VERSION ""

NS_ :

BS_:

BU_:

BO_ 2566756606 AT1HI1: 40 Vector__XXX
 SG_ Aftertreatment1TotalFuelUsed : 0|32@1+ (0.5,0) [0|2105540607.5] "l" Vector__XXX
 SG_ Aftrtrtmnt1TtlDsldTm : 64|32@1+ (1,0) [0|4211081215] "s" Vector__XXX
 SG_ Aftrtrtmnt1TtlNmrfAtvRgnrtns : 96|32@1+ (1,0) [0|4211081215] "count" Vector__XXX
 SG_ Aftrtrtmnt1TtlRgnrtnTm : 32|32@1+ (1,0) [0|4211081215] "s" Vector__XXX
 SG_ Atttt1DsPttFtAvDstBtwAtvRts : 288|32@1+ (0.125,0) [0|526385151.875] "km" Vector__XXX
 SG_ Atttt1DsPttFtAvTBtwAtvRts : 256|32@1+ (1,0) [0|4211081215] "s" Vector__XXX
 SG_ Atttt1DsPttFtTtNAtvRtItRqsts : 192|32@1+ (1,0) [0|4211081215] "count" Vector__XXX
 SG_ Atttt1DsPttFtTtNAtvRtMRqsts : 224|32@1+ (1,0) [0|4211081215] "count" Vector__XXX
 SG_ Atttt1DsPttFtTtNPssvRts : 160|32@1+ (1,0) [0|4211081215] "count" Vector__XXX
 SG_ Atttt1DsPttFtTtPssvRtT : 128|32@1+ (1,0) [0|4211081215] "s" Vector__XXX

BO_ 2566756862 AT2HI1: 40 Vector__XXX
 SG_ Aftertreatment2TotalFuelUsed : 0|32@1+ (0.5,0) [0|2105540607.5] "l" Vector__XXX
 SG_ Aftrtrtmnt2TtlDsldTm : 64|32@1+ (1,0) [0|4211081215] "s" Vector__XXX
 SG_ Aftrtrtmnt2TtlNmrfAtvRgnrtns : 96|32@1+ (1,0) [0|4211081215] "count" Vector__XXX
 SG_ Aftrtrtmnt2TtlRgnrtnTm : 32|32@1+ (1,0) [0|4211081215] "s" Vector__XXX
 SG_ Atttt2DsPttFtAvDstBtwAtvRts : 288|32@1+ (0.125,0) [0|526385151.875] "km" Vector__XXX
 SG_ Atttt2DsPttFtAvTBtwAtvRts : 256|32@1+ (1,0) [0|4211081215] "s" Vector__XXX
 SG_ Atttt2DsPttFtTtNAtvRtItRqsts : 192|32@1+ (1,0) [0|4211081215] "count" Vector__XXX
 SG_ Atttt2DsPttFtTtNAtvRtMRqsts : 224|32@1+ (1,0) [0|4211081215] "count" Vector__XXX
 SG_ Atttt2DsPttFtTtNPssvRts : 160|32@1+ (1,0) [0|4211081215] "count" Vector__XXX
 SG_ Atttt2DsPttFtTtPssvRtT : 128|32@1+ (1,0) [0|4211081215] "s" Vector__XXX

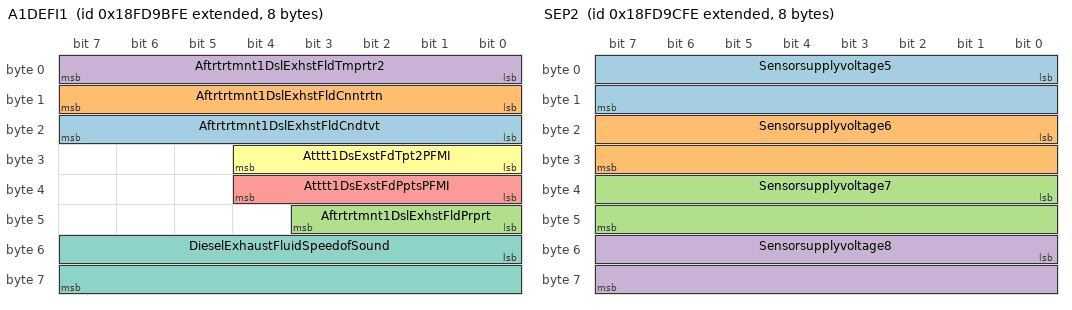
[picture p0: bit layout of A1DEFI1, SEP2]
BO_ 2566757374 A1DEFI1: 8 Vector__XXX
 SG_ Aftrtrtmnt1DslExhstFldCndtvt : 16|8@1+ (5,0) [0|1250] "µSiemens/mm" Vector__XXX
 SG_ Aftrtrtmnt1DslExhstFldCnntrtn : 8|8@1+ (0.25,0) [0|62.5] "%" Vector__XXX
 SG_ Aftrtrtmnt1DslExhstFldPrprt : 40|4@1+ (1,0) [0|15] "" Vector__XXX
 SG_ Aftrtrtmnt1DslExhstFldTmprtr2 : 0|8@1+ (1,-40) [-40|210] "degC" Vector__XXX
 SG_ Atttt1DsExstFdPptsPFMI : 32|5@1+ (1,0) [0|31] "binary" Vector__XXX
 SG_ Atttt1DsExstFdTpt2PFMI : 24|5@1+ (1,0) [0|31] "binary" Vector__XXX
 SG_ DieselExhaustFluidSpeedofSound : 48|16@1+ (0.1,0) [0|6425.5] "m/s" Vector__XXX

BO_ 2566757630 SEP2: 8 Vector__XXX
 SG_ Sensorsupplyvoltage5 : 0|16@1+ (0.05,0) [0|3212.75] "V" Vector__XXX
 SG_ Sensorsupplyvoltage6 : 16|16@1+ (0.05,0) [0|3212.75] "V" Vector__XXX
 SG_ Sensorsupplyvoltage7 : 32|16@1+ (0.05,0) [0|3212.75] "V" Vector__XXX
 SG_ Sensorsupplyvoltage8 : 48|16@1+ (0.05,0) [0|3212.75] "V" Vector__XXX

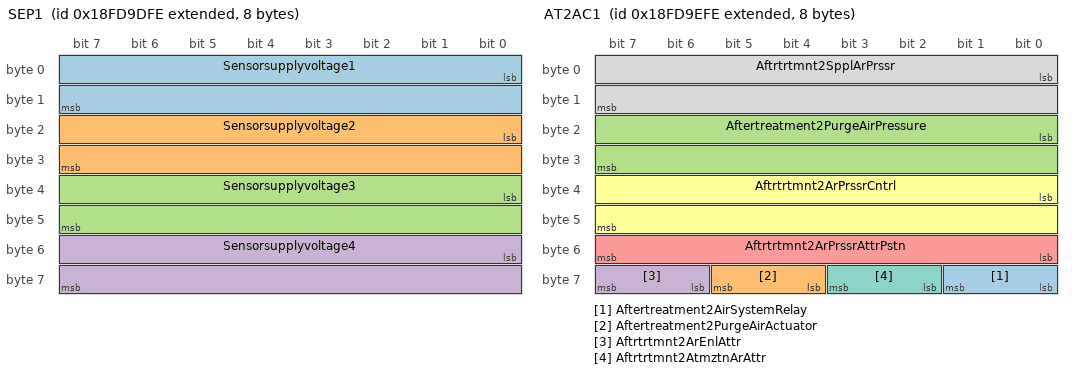
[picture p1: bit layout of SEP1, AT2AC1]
BO_ 2566757886 SEP1: 8 Vector__XXX
 SG_ Sensorsupplyvoltage1 : 0|16@1+ (0.05,0) [0|3212.75] "V" Vector__XXX
 SG_ Sensorsupplyvoltage2 : 16|16@1+ (0.05,0) [0|3212.75] "V" Vector__XXX
 SG_ Sensorsupplyvoltage3 : 32|16@1+ (0.05,0) [0|3212.75] "V" Vector__XXX
 SG_ Sensorsupplyvoltage4 : 48|16@1+ (0.05,0) [0|3212.75] "V" Vector__XXX

BO_ 2566758142 AT2AC1: 8 Vector__XXX
 SG_ Aftertreatment2AirSystemRelay : 56|2@1+ (1,0) [0|3] "" Vector__XXX
 SG_ Aftertreatment2PurgeAirActuator : 60|2@1+ (1,0) [0|3] "" Vector__XXX
 SG_ Aftertreatment2PurgeAirPressure : 16|16@1+ (0.1,0) [0|6425.5] "kPa" Vector__XXX
 SG_ Aftrtrtmnt2ArEnlAttr : 62|2@1+ (1,0) [0|3] "" Vector__XXX
 SG_ Aftrtrtmnt2ArPrssrAttrPstn : 48|8@1+ (0.4,0) [0|100] "%" Vector__XXX
 SG_ Aftrtrtmnt2ArPrssrCntrl : 32|16@1+ (0.0025,0) [0|160.6375] "%" Vector__XXX
 SG_ Aftrtrtmnt2AtmztnArAttr : 58|2@1+ (1,0) [0|3] "" Vector__XXX
 SG_ Aftrtrtmnt2SpplArPrssr : 0|16@1+ (0.1,0) [0|6425.5] "kPa" Vector__XXX

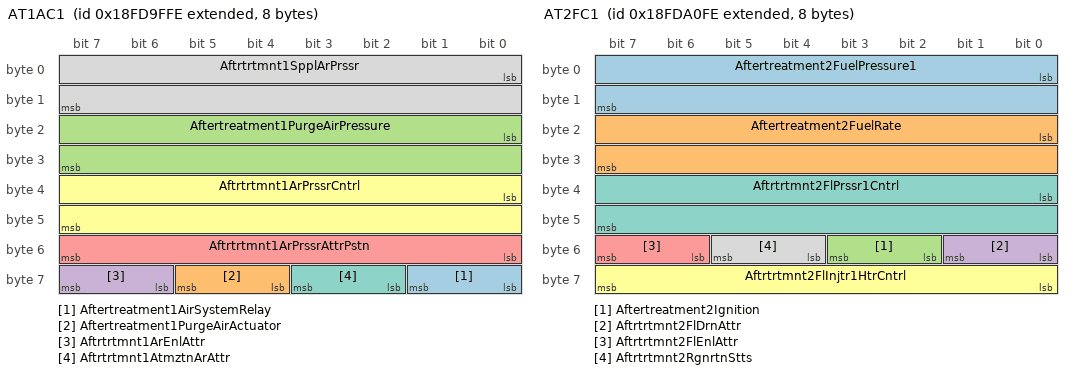
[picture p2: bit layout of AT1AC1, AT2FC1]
BO_ 2566758398 AT1AC1: 8 Vector__XXX
 SG_ Aftertreatment1AirSystemRelay : 56|2@1+ (1,0) [0|3] "" Vector__XXX
 SG_ Aftertreatment1PurgeAirActuator : 60|2@1+ (1,0) [0|3] "" Vector__XXX
 SG_ Aftertreatment1PurgeAirPressure : 16|16@1+ (0.1,0) [0|6425.5] "kPa" Vector__XXX
 SG_ Aftrtrtmnt1ArEnlAttr : 62|2@1+ (1,0) [0|3] "" Vector__XXX
 SG_ Aftrtrtmnt1ArPrssrAttrPstn : 48|8@1+ (0.4,0) [0|100] "%" Vector__XXX
 SG_ Aftrtrtmnt1ArPrssrCntrl : 32|16@1+ (0.0025,0) [0|160.6375] "%" Vector__XXX
 SG_ Aftrtrtmnt1AtmztnArAttr : 58|2@1+ (1,0) [0|3] "" Vector__XXX
 SG_ Aftrtrtmnt1SpplArPrssr : 0|16@1+ (0.1,0) [0|6425.5] "kPa" Vector__XXX

BO_ 2566758654 AT2FC1: 8 Vector__XXX
 SG_ Aftertreatment2FuelPressure1 : 0|16@1+ (0.1,0) [0|6425.5] "kPa" Vector__XXX
 SG_ Aftertreatment2FuelRate : 16|16@1+ (0.05,0) [0|3212.75] "l/h" Vector__XXX
 SG_ Aftertreatment2Ignition : 50|2@1+ (1,0) [0|3] "" Vector__XXX
 SG_ Aftrtrtmnt2FlDrnAttr : 48|2@1+ (1,0) [0|3] "" Vector__XXX
 SG_ Aftrtrtmnt2FlEnlAttr : 54|2@1+ (1,0) [0|3] "" Vector__XXX
 SG_ Aftrtrtmnt2FlInjtr1HtrCntrl : 56|8@1+ (0.4,0) [0|100] "%" Vector__XXX
 SG_ Aftrtrtmnt2FlPrssr1Cntrl : 32|16@1+ (0.0025,0) [0|160.6375] "%" Vector__XXX
 SG_ Aftrtrtmnt2RgnrtnStts : 52|2@1+ (1,0) [0|3] "" Vector__XXX

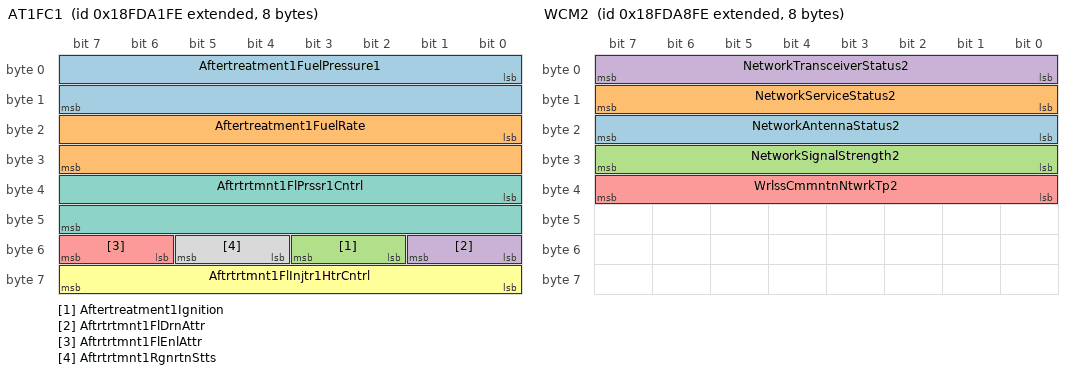
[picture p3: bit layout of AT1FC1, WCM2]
BO_ 2566758910 AT1FC1: 8 Vector__XXX
 SG_ Aftertreatment1FuelPressure1 : 0|16@1+ (0.1,0) [0|6425.5] "kPa" Vector__XXX
 SG_ Aftertreatment1FuelRate : 16|16@1+ (0.05,0) [0|3212.75] "l/h" Vector__XXX
 SG_ Aftertreatment1Ignition : 50|2@1+ (1,0) [0|3] "" Vector__XXX
 SG_ Aftrtrtmnt1FlDrnAttr : 48|2@1+ (1,0) [0|3] "" Vector__XXX
 SG_ Aftrtrtmnt1FlEnlAttr : 54|2@1+ (1,0) [0|3] "" Vector__XXX
 SG_ Aftrtrtmnt1FlInjtr1HtrCntrl : 56|8@1+ (0.4,0) [0|100] "%" Vector__XXX
 SG_ Aftrtrtmnt1FlPrssr1Cntrl : 32|16@1+ (0.0025,0) [0|160.6375] "%" Vector__XXX
 SG_ Aftrtrtmnt1RgnrtnStts : 52|2@1+ (1,0) [0|3] "" Vector__XXX

BO_ 2566759678 PTODE: 8 Vector__XXX
 SG_ AtleastonePTOengaged : 48|2@1+ (1,0) [0|3] "" Vector__XXX
 SG_ EnableSwitchPTOEngineFlywheel : 8|2@1+ (1,0) [0|3] "" Vector__XXX
 SG_ EnggmntCnsntPTOEngnAssrDrv1 : 26|2@1+ (1,0) [0|3] "" Vector__XXX
 SG_ EnggmntCnsntPTOEngnAssrDrv2 : 28|2@1+ (1,0) [0|3] "" Vector__XXX
 SG_ EnggmntCnsntPTOEngnFlwhl : 24|2@1+ (1,0) [0|3] "" Vector__XXX
 SG_ EnggmntSttsPTOEngnAssrDrv1 : 42|2@1+ (1,0) [0|3] "" Vector__XXX
 SG_ EnggmntSttsPTOEngnAssrDrv2 : 44|2@1+ (1,0) [0|3] "" Vector__XXX
 SG_ EnggmntSttsPTOEngnFlwhl : 40|2@1+ (1,0) [0|3] "" Vector__XXX
 SG_ EnlSwthPTOEngnAssrDrv1 : 10|2@1+ (1,0) [0|3] "" Vector__XXX
 SG_ EnlSwthPTOEngnAssrDrv2 : 12|2@1+ (1,0) [0|3] "" Vector__XXX
 SG_ EnlSwthTrnsfrstptshftPTO : 0|2@1+ (1,0) [0|3] "" Vector__XXX
 SG_ EnlSwthTrnsmssntptshftPTO : 2|2@1+ (1,0) [0|3] "" Vector__XXX
 SG_ EnlSwthTrnsmssnnptshftPTO2 : 4|2@1+ (1,0) [0|3] "" Vector__XXX
 SG_ EnlSwthTrnsmssnnptshftPTO1 : 6|2@1+ (1,0) [0|3] "" Vector__XXX
 SG_ EnggmntCnsntTrnsfrstptshftPTO : 16|2@1+ (1,0) [0|3] "" Vector__XXX
 SG_ EnggmntCnsntTrnsmssntptshftPTO : 18|2@1+ (1,0) [0|3] "" Vector__XXX
 SG_ EnggmntCnsntTrnsmssnnptshftPTO2 : 20|2@1+ (1,0) [0|3] "" Vector__XXX
 SG_ EnggmntCnsntTrnsmssnnptshftPTO1 : 22|2@1+ (1,0) [0|3] "" Vector__XXX
 SG_ EnggmntSttsTrnsfrstptshftPTO : 32|2@1+ (1,0) [0|3] "" Vector__XXX
 SG_ EnggmntSttsTrnsmssntptshftPTO : 34|2@1+ (1,0) [0|3] "" Vector__XXX
 SG_ EnggmntSttsTrnsmssnnptshftPTO2 : 36|2@1+ (1,0) [0|3] "" Vector__XXX
 SG_ EnggmntSttsTrnsmssnnptshftPTO1 : 38|2@1+ (1,0) [0|3] "" Vector__XXX
 SG_ PTOMessageCounter : 56|4@1+ (1,0) [0|15] "count" Vector__XXX
 SG_ PTOMessageChecksum : 60|4@1+ (1,0) [0|15] "count" Vector__XXX

BO_ 2566759934 DC2: 8 Vector__XXX
 SG_ EnableStatusofDoor1 : 4|2@1+ (1,0) [0|3] "" Vector__XXX
 SG_ EnableStatusofDoor10 : 58|2@1+ (1,0) [0|3] "" Vector__XXX
 SG_ EnableStatusofDoor2 : 10|2@1+ (1,0) [0|3] "" Vector__XXX
 SG_ EnableStatusofDoor3 : 16|2@1+ (1,0) [0|3] "" Vector__XXX
 SG_ EnableStatusofDoor4 : 22|2@1+ (1,0) [0|3] "" Vector__XXX
 SG_ EnableStatusofDoor5 : 28|2@1+ (1,0) [0|3] "" Vector__XXX
 SG_ EnableStatusofDoor6 : 34|2@1+ (1,0) [0|3] "" Vector__XXX
 SG_ EnableStatusofDoor7 : 40|2@1+ (1,0) [0|3] "" Vector__XXX
 SG_ EnableStatusofDoor8 : 46|2@1+ (1,0) [0|3] "" Vector__XXX
 SG_ EnableStatusofDoor9 : 52|2@1+ (1,0) [0|3] "" Vector__XXX
 SG_ LockStatusofDoor1 : 0|2@1+ (1,0) [0|3] "" Vector__XXX
 SG_ LockStatusofDoor10 : 54|2@1+ (1,0) [0|3] "" Vector__XXX
 SG_ LockStatusofDoor2 : 6|2@1+ (1,0) [0|3] "" Vector__XXX
 SG_ LockStatusofDoor3 : 12|2@1+ (1,0) [0|3] "" Vector__XXX
 SG_ LockStatusofDoor4 : 18|2@1+ (1,0) [0|3] "" Vector__XXX
 SG_ LockStatusofDoor5 : 24|2@1+ (1,0) [0|3] "" Vector__XXX
 SG_ LockStatusofDoor6 : 30|2@1+ (1,0) [0|3] "" Vector__XXX
 SG_ LockStatusofDoor7 : 36|2@1+ (1,0) [0|3] "" Vector__XXX
 SG_ LockStatusofDoor8 : 42|2@1+ (1,0) [0|3] "" Vector__XXX
 SG_ LockStatusofDoor9 : 48|2@1+ (1,0) [0|3] "" Vector__XXX
 SG_ OpenStatusofDoor1 : 2|2@1+ (1,0) [0|3] "" Vector__XXX
 SG_ OpenStatusofDoor10 : 56|2@1+ (1,0) [0|3] "" Vector__XXX
 SG_ OpenStatusofDoor2 : 8|2@1+ (1,0) [0|3] "" Vector__XXX
 SG_ OpenStatusofDoor3 : 14|2@1+ (1,0) [0|3] "" Vector__XXX
 SG_ OpenStatusofDoor4 : 20|2@1+ (1,0) [0|3] "" Vector__XXX
 SG_ OpenStatusofDoor5 : 26|2@1+ (1,0) [0|3] "" Vector__XXX
 SG_ OpenStatusofDoor6 : 32|2@1+ (1,0) [0|3] "" Vector__XXX
 SG_ OpenStatusofDoor7 : 38|2@1+ (1,0) [0|3] "" Vector__XXX
 SG_ OpenStatusofDoor8 : 44|2@1+ (1,0) [0|3] "" Vector__XXX
 SG_ OpenStatusofDoor9 : 50|2@1+ (1,0) [0|3] "" Vector__XXX

BO_ 2566760702 WCM2: 8 Vector__XXX
 SG_ NetworkAntennaStatus2 : 16|8@1+ (1,0) [0|255] "" Vector__XXX
 SG_ NetworkServiceStatus2 : 8|8@1+ (1,0) [0|255] "" Vector__XXX
 SG_ NetworkSignalStrength2 : 24|8@1+ (0.4,0) [0|100] "%" Vector__XXX
 SG_ NetworkTransceiverStatus2 : 0|8@1+ (1,0) [0|255] "" Vector__XXX
 SG_ WrlssCmmntnNtwrkTp2 : 32|8@1+ (1,0) [0|255] "" Vector__XXX

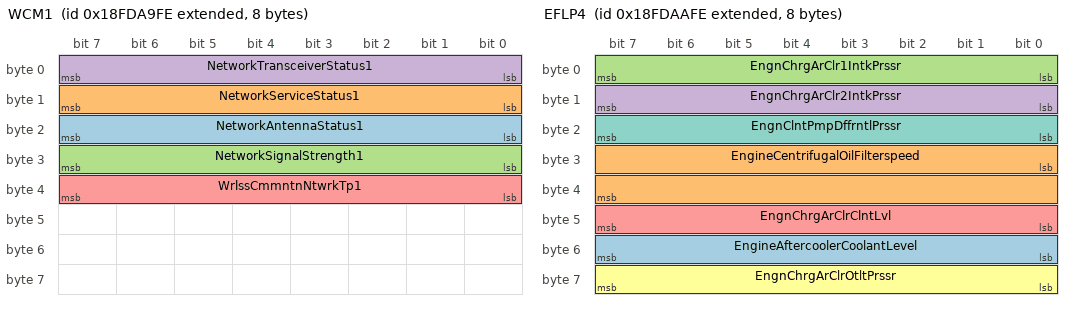
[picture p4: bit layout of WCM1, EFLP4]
BO_ 2566760958 WCM1: 8 Vector__XXX
 SG_ NetworkAntennaStatus1 : 16|8@1+ (1,0) [0|255] "" Vector__XXX
 SG_ NetworkServiceStatus1 : 8|8@1+ (1,0) [0|255] "" Vector__XXX
 SG_ NetworkSignalStrength1 : 24|8@1+ (0.4,0) [0|100] "%" Vector__XXX
 SG_ NetworkTransceiverStatus1 : 0|8@1+ (1,0) [0|255] "" Vector__XXX
 SG_ WrlssCmmntnNtwrkTp1 : 32|8@1+ (1,0) [0|255] "" Vector__XXX

BO_ 2566761214 EFLP4: 8 Vector__XXX
 SG_ EngineAftercoolerCoolantLevel : 48|8@1+ (0.4,0) [0|100] "%" Vector__XXX
 SG_ EngineCentrifugalOilFilterspeed : 24|16@1+ (4,0) [0|257020] "rpm" Vector__XXX
 SG_ EngnChrgArClr1IntkPrssr : 0|8@1+ (2,0) [0|500] "kPa" Vector__XXX
 SG_ EngnChrgArClr2IntkPrssr : 8|8@1+ (2,0) [0|500] "kPa" Vector__XXX
 SG_ EngnChrgArClrClntLvl : 40|8@1+ (0.4,0) [0|100] "%" Vector__XXX
 SG_ EngnChrgArClrOtltPrssr : 56|8@1+ (2,0) [0|500] "kPa" Vector__XXX
 SG_ EngnClntPmpDffrntlPrssr : 16|8@1+ (1.64,-7) [-7|403] "kPa" Vector__XXX

BO_ 2566761726 EFI: 8 Vector__XXX
 SG_ EngineIdleFuelFlowRateThreshold : 8|32@1+ (0.001,0) [0|4211081.215] "l/h" Vector__XXX
 SG_ NmrfFlCnsmptnMntrngTrnsdrs : 0|8@1+ (1,0) [0|250] "count" Vector__XXX

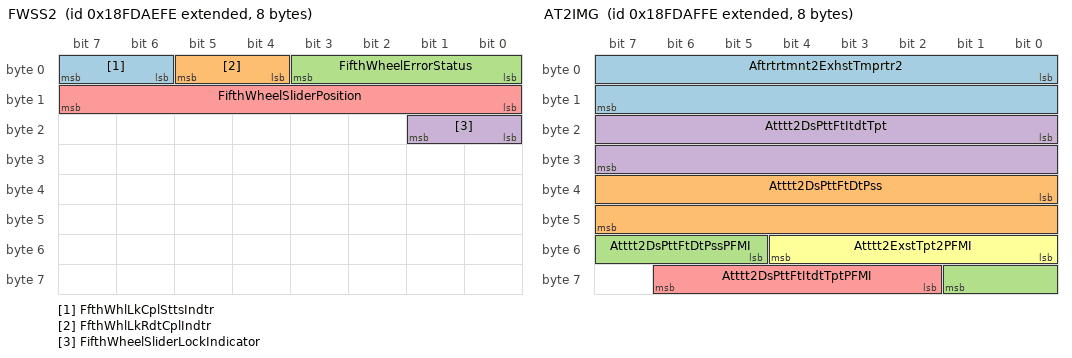
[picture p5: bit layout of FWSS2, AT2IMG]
BO_ 2566762238 FWSS2: 8 Vector__XXX
 SG_ FfthWhlLkCplSttsIndtr : 6|2@1+ (1,0) [0|3] "" Vector__XXX
 SG_ FfthWhlLkRdtCplIndtr : 4|2@1+ (1,0) [0|3] "" Vector__XXX
 SG_ FifthWheelErrorStatus : 0|4@1+ (1,0) [0|15] "" Vector__XXX
 SG_ FifthWheelSliderLockIndicator : 16|2@1+ (1,0) [0|3] "" Vector__XXX
 SG_ FifthWheelSliderPosition : 8|8@1+ (10,0) [0|2500] "mm" Vector__XXX

BO_ 2566762494 AT2IMG: 8 Vector__XXX
 SG_ Aftrtrtmnt2ExhstTmprtr2 : 0|16@1+ (0.03125,-273) [-273|1734.96875] "degC" Vector__XXX
 SG_ Atttt2DsPttFtDtPss : 32|16@1+ (0.1,0) [0|6425.5] "kPa" Vector__XXX
 SG_ Atttt2DsPttFtDtPssPFMI : 53|5@1+ (1,0) [0|31] "binary" Vector__XXX
 SG_ Atttt2DsPttFtItdtTpt : 16|16@1+ (0.03125,-273) [-273|1734.96875] "degC" Vector__XXX
 SG_ Atttt2DsPttFtItdtTptPFMI : 58|5@1+ (1,0) [0|31] "binary" Vector__XXX
 SG_ Atttt2ExstTpt2PFMI : 48|5@1+ (1,0) [0|31] "binary" Vector__XXX

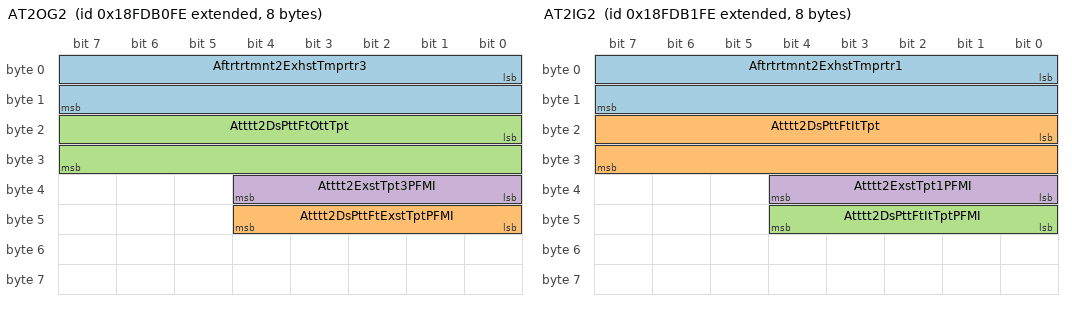
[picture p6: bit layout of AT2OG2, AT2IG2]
BO_ 2566762750 AT2OG2: 8 Vector__XXX
 SG_ Aftrtrtmnt2ExhstTmprtr3 : 0|16@1+ (0.03125,-273) [-273|1734.96875] "degC" Vector__XXX
 SG_ Atttt2DsPttFtExstTptPFMI : 40|5@1+ (1,0) [0|31] "binary" Vector__XXX
 SG_ Atttt2DsPttFtOttTpt : 16|16@1+ (0.03125,-273) [-273|1734.96875] "degC" Vector__XXX
 SG_ Atttt2ExstTpt3PFMI : 32|5@1+ (1,0) [0|31] "binary" Vector__XXX

BO_ 2566763006 AT2IG2: 8 Vector__XXX
 SG_ Aftrtrtmnt2ExhstTmprtr1 : 0|16@1+ (0.03125,-273) [-273|1734.96875] "degC" Vector__XXX
 SG_ Atttt2DsPttFtItTpt : 16|16@1+ (0.03125,-273) [-273|1734.96875] "degC" Vector__XXX
 SG_ Atttt2DsPttFtItTptPFMI : 40|5@1+ (1,0) [0|31] "binary" Vector__XXX
 SG_ Atttt2ExstTpt1PFMI : 32|5@1+ (1,0) [0|31] "binary" Vector__XXX

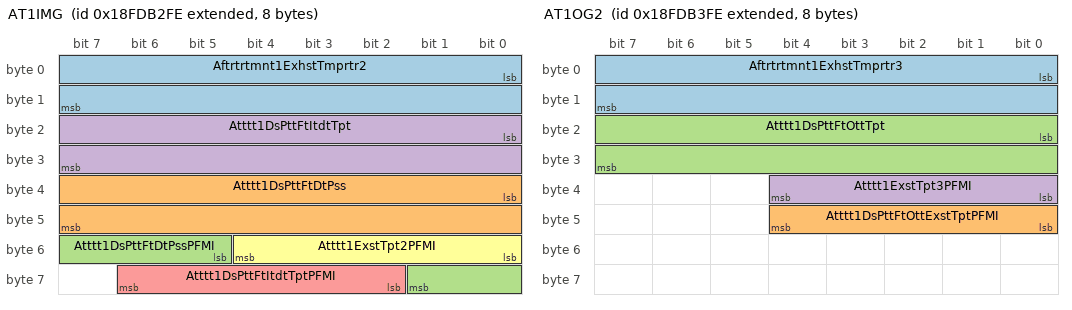
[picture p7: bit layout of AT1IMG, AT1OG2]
BO_ 2566763262 AT1IMG: 8 Vector__XXX
 SG_ Aftrtrtmnt1ExhstTmprtr2 : 0|16@1+ (0.03125,-273) [-273|1734.96875] "degC" Vector__XXX
 SG_ Atttt1DsPttFtDtPss : 32|16@1+ (0.1,0) [0|6425.5] "kPa" Vector__XXX
 SG_ Atttt1DsPttFtDtPssPFMI : 53|5@1+ (1,0) [0|31] "binary" Vector__XXX
 SG_ Atttt1DsPttFtItdtTpt : 16|16@1+ (0.03125,-273) [-273|1734.96875] "degC" Vector__XXX
 SG_ Atttt1DsPttFtItdtTptPFMI : 58|5@1+ (1,0) [0|31] "binary" Vector__XXX
 SG_ Atttt1ExstTpt2PFMI : 48|5@1+ (1,0) [0|31] "binary" Vector__XXX

BO_ 2566763518 AT1OG2: 8 Vector__XXX
 SG_ Aftrtrtmnt1ExhstTmprtr3 : 0|16@1+ (0.03125,-273) [-273|1734.96875] "degC" Vector__XXX
 SG_ Atttt1DsPttFtOttExstTptPFMI : 40|5@1+ (1,0) [0|31] "binary" Vector__XXX
 SG_ Atttt1DsPttFtOttTpt : 16|16@1+ (0.03125,-273) [-273|1734.96875] "degC" Vector__XXX
 SG_ Atttt1ExstTpt3PFMI : 32|5@1+ (1,0) [0|31] "binary" Vector__XXX

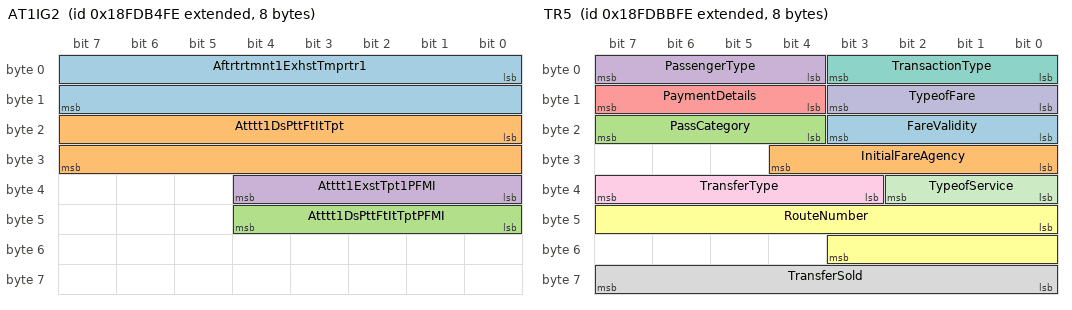
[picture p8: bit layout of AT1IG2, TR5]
BO_ 2566763774 AT1IG2: 8 Vector__XXX
 SG_ Aftrtrtmnt1ExhstTmprtr1 : 0|16@1+ (0.03125,-273) [-273|1734.96875] "degC" Vector__XXX
 SG_ Atttt1DsPttFtItTpt : 16|16@1+ (0.03125,-273) [-273|1734.96875] "degC" Vector__XXX
 SG_ Atttt1DsPttFtItTptPFMI : 40|5@1+ (1,0) [0|31] "binary" Vector__XXX
 SG_ Atttt1ExstTpt1PFMI : 32|5@1+ (1,0) [0|31] "binary" Vector__XXX

BO_ 2566765054 TPRI: 8 Vector__XXX
 SG_ ReferenceTirePressure : 8|8@1+ (8,0) [0|2000] "kPa" Vector__XXX
 SG_ TireLocation : 0|8@1+ (1,0) [0|255] "" Vector__XXX

BO_ 2566765310 TR6: 8 Vector__XXX
 SG_ FareboxAlarmIdentifier : 8|7@1+ (1,0) [0|127] "" Vector__XXX
 SG_ FareboxEmergencyStatus : 0|2@1+ (1,0) [0|3] "" Vector__XXX

BO_ 2566765566 TR5: 8 Vector__XXX
 SG_ FareValidity : 16|4@1+ (1,0) [0|15] "count" Vector__XXX
 SG_ InitialFareAgency : 24|5@1+ (1,0) [0|31] "count" Vector__XXX
 SG_ PassCategory : 20|4@1+ (1,0) [0|15] "count" Vector__XXX
 SG_ PassengerType : 4|4@1+ (1,0) [0|15] "" Vector__XXX
 SG_ PaymentDetails : 12|4@1+ (1,0) [0|15] "" Vector__XXX
 SG_ RouteNumber : 40|12@1+ (1,0) [0|4095] "count" Vector__XXX
 SG_ TransactionType : 0|4@1+ (1,0) [0|15] "" Vector__XXX
 SG_ TransferSold : 56|8@1+ (1,0) [0|255] "count" Vector__XXX
 SG_ TransferType : 35|5@1+ (1,0) [0|31] "" Vector__XXX
 SG_ TypeofFare : 8|4@1+ (1,0) [0|15] "" Vector__XXX
 SG_ TypeofService : 32|3@1+ (1,0) [0|7] "" Vector__XXX

BO_ 2566765822 TR4: 15 Vector__XXX
 SG_ AssignedBlock : 88|16@1+ (1,0) [0|65535] "count" Vector__XXX
 SG_ AssignedRoute : 56|16@1+ (1,0) [0|65535] "count" Vector__XXX
 SG_ AssignedRun : 72|16@1+ (1,0) [0|65535] "count" Vector__XXX
 SG_ Driversfareboxsecuritycode : 104|16@1+ (1,0) [0|65535] "count" Vector__XXX
 SG_ FareboxServiceStatus : 0|2@1+ (1,0) [0|3] "" Vector__XXX
 SG_ FarePresets : 16|8@1+ (1,0) [0|255] "" Vector__XXX
 SG_ PatternNumber : 40|16@1+ (1,0) [0|65535] "count" Vector__XXX
 SG_ TripDirection : 8|4@1+ (1,0) [0|15] "" Vector__XXX
 SG_ TripNumber : 24|16@1+ (1,0) [0|65535] "count" Vector__XXX
 SG_ TripStatus : 2|3@1+ (1,0) [0|7] "" Vector__XXX

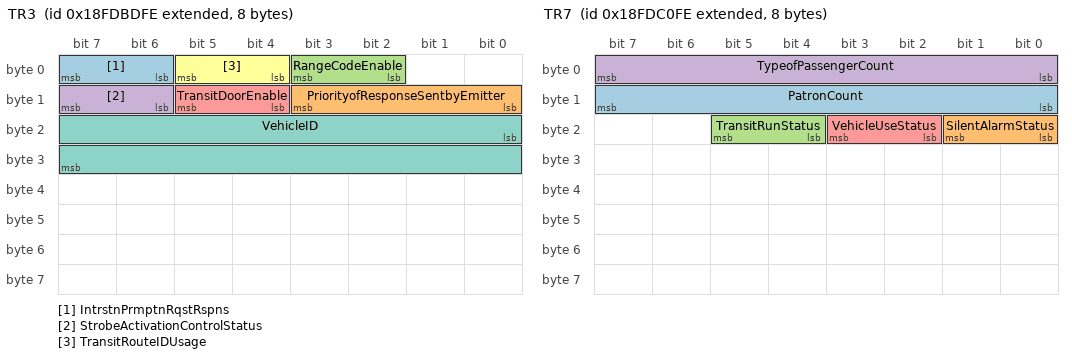
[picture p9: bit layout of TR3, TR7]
BO_ 2566766078 TR3: 8 Vector__XXX
 SG_ IntrstnPrmptnRqstRspns : 6|2@1+ (1,0) [0|3] "" Vector__XXX
 SG_ PriorityofResponseSentbyEmitter : 8|4@1+ (1,0) [0|15] "" Vector__XXX
 SG_ RangeCodeEnable : 2|2@1+ (1,0) [0|3] "" Vector__XXX
 SG_ StrobeActivationControlStatus : 14|2@1+ (1,0) [0|3] "" Vector__XXX
 SG_ TransitDoorEnable : 12|2@1+ (1,0) [0|3] "" Vector__XXX
 SG_ TransitRouteIDUsage : 4|2@1+ (1,0) [0|3] "" Vector__XXX
 SG_ VehicleID : 16|16@1+ (1,0) [0|65535] "count" Vector__XXX

BO_ 2566766334 TR1: 4 Vector__XXX
 SG_ Agency : 0|8@1+ (1,0) [0|255] "count" Vector__XXX
 SG_ NmrftsnthTrnstAssgndBlkIdntt : 24|8@1+ (1,0) [0|250] "byte" Vector__XXX
 SG_ NmrftsnthTrnstAssgndRnIdntt : 16|8@1+ (1,0) [0|250] "byte" Vector__XXX
 SG_ NmrftsnthTrnstAssgndRtIdntt : 8|8@1+ (1,0) [0|250] "byte" Vector__XXX

BO_ 2566766590 TR2: 8 Vector__XXX
 SG_ NmrftsnthMlpstIdntftn : 0|8@1+ (1,0) [0|250] "byte" Vector__XXX

BO_ 2566766846 TR7: 8 Vector__XXX
 SG_ PatronCount : 8|8@1+ (1,0) [0|250] "count" Vector__XXX
 SG_ SilentAlarmStatus : 16|2@1+ (1,0) [0|3] "" Vector__XXX
 SG_ TransitRunStatus : 20|2@1+ (1,0) [0|3] "" Vector__XXX
 SG_ TypeofPassengerCount : 0|8@1+ (1,0) [0|255] "" Vector__XXX
 SG_ VehicleUseStatus : 18|2@1+ (1,0) [0|3] "" Vector__XXX

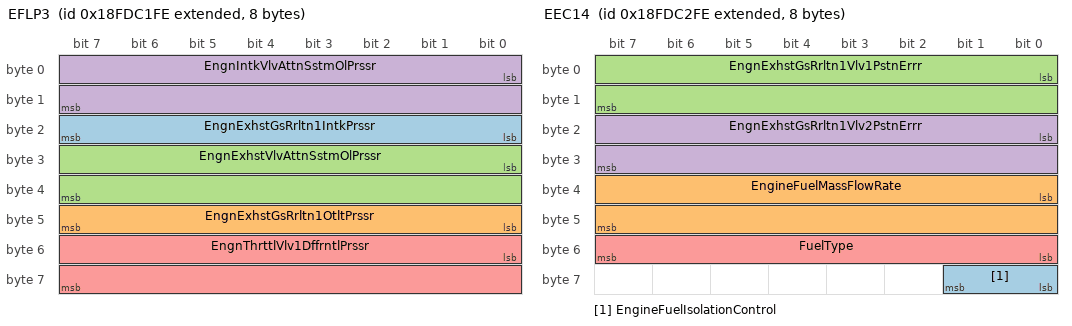
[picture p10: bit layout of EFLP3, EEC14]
BO_ 2566767102 EFLP3: 8 Vector__XXX
 SG_ EngnExhstGsRrltn1IntkPrssr : 16|8@1+ (2,0) [0|500] "kPa" Vector__XXX
 SG_ EngnExhstGsRrltn1OtltPrssr : 40|8@1+ (2,0) [0|500] "kPa" Vector__XXX
 SG_ EngnExhstVlvAttnSstmOlPrssr : 24|16@1+ (0.00390625,0) [0|250.996] "MPa" Vector__XXX
 SG_ EngnIntkVlvAttnSstmOlPrssr : 0|16@1+ (0.00390625,0) [0|250.996] "MPa" Vector__XXX
 SG_ EngnThrttlVlv1DffrntlPrssr : 48|16@1+ (0.1,0) [0|6425.5] "kPa" Vector__XXX

BO_ 2566767358 EEC14: 8 Vector__XXX
 SG_ EngineFuelIsolationControl : 56|2@1+ (1,0) [0|3] "" Vector__XXX
 SG_ EngineFuelMassFlowRate : 32|16@1+ (0.005,0) [0|321.275] "g/s" Vector__XXX
 SG_ EngnExhstGsRrltn1Vlv1PstnErrr : 0|16@1+ (0.004,-125) [-125|132.02] "%" Vector__XXX
 SG_ EngnExhstGsRrltn1Vlv2PstnErrr : 16|16@1+ (0.004,-125) [-125|132.02] "%" Vector__XXX
 SG_ FuelType : 48|8@1+ (1,0) [0|255] "" Vector__XXX

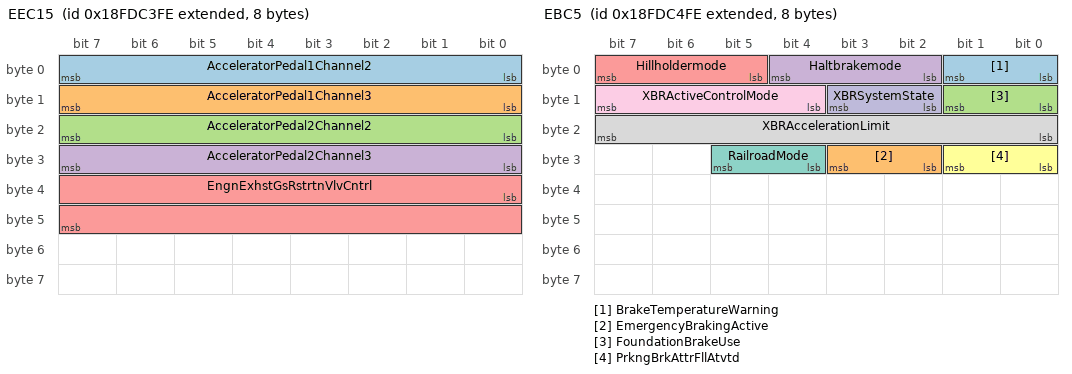
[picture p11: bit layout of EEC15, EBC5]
BO_ 2566767614 EEC15: 8 Vector__XXX
 SG_ AcceleratorPedal1Channel2 : 0|8@1+ (0.4,0) [0|100] "%" Vector__XXX
 SG_ AcceleratorPedal1Channel3 : 8|8@1+ (0.4,0) [0|100] "%" Vector__XXX
 SG_ AcceleratorPedal2Channel2 : 16|8@1+ (0.4,0) [0|100] "%" Vector__XXX
 SG_ AcceleratorPedal2Channel3 : 24|8@1+ (0.4,0) [0|100] "%" Vector__XXX
 SG_ EngnExhstGsRstrtnVlvCntrl : 32|16@1+ (0.0025,0) [0|160.6375] "%" Vector__XXX

BO_ 2566767870 EBC5: 8 Vector__XXX
 SG_ BrakeTemperatureWarning : 0|2@1+ (1,0) [0|3] "" Vector__XXX
 SG_ EmergencyBrakingActive : 26|2@1+ (1,0) [0|3] "" Vector__XXX
 SG_ FoundationBrakeUse : 8|2@1+ (1,0) [0|3] "" Vector__XXX
 SG_ Haltbrakemode : 2|3@1+ (1,0) [0|7] "" Vector__XXX
 SG_ Hillholdermode : 5|3@1+ (1,0) [0|7] "" Vector__XXX
 SG_ PrkngBrkAttrFllAtvtd : 24|2@1+ (1,0) [0|3] "" Vector__XXX
 SG_ RailroadMode : 28|2@1+ (1,0) [0|3] "" Vector__XXX
 SG_ XBRAccelerationLimit : 16|8@1+ (0.1,-12.5) [-12.5|12.5] "m/(s*s)" Vector__XXX
 SG_ XBRActiveControlMode : 12|4@1+ (1,0) [0|15] "" Vector__XXX
 SG_ XBRSystemState : 10|2@1+ (1,0) [0|3] "" Vector__XXX

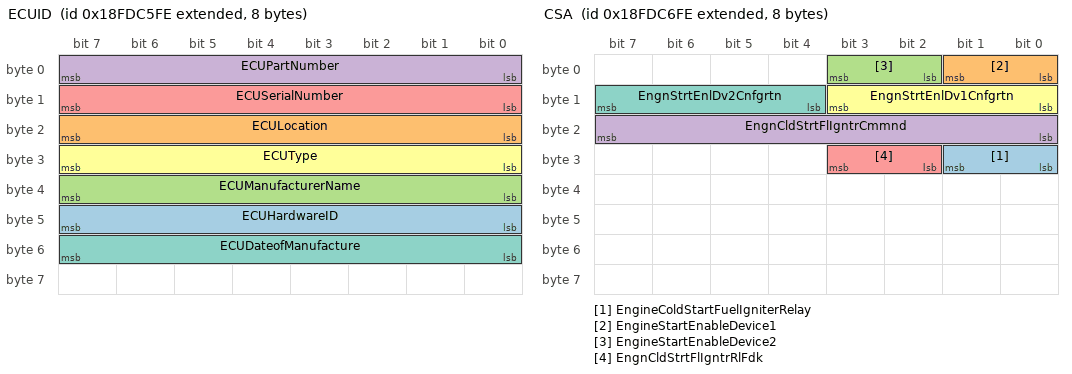
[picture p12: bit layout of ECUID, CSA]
BO_ 2566768126 ECUID: 8 Vector__XXX
 SG_ ECUHardwareID : 40|8@1+ (1,0) [0|255] "ASCII" Vector__XXX
 SG_ ECULocation : 16|8@1+ (1,0) [0|255] "ASCII" Vector__XXX
 SG_ ECUManufacturerName : 32|8@1+ (1,0) [0|255] "ASCII" Vector__XXX
 SG_ ECUPartNumber : 0|8@1+ (1,0) [0|255] "ASCII" Vector__XXX
 SG_ ECUSerialNumber : 8|8@1+ (1,0) [0|255] "ASCII" Vector__XXX
 SG_ ECUType : 24|8@1+ (1,0) [0|255] "ASCII" Vector__XXX
 SG_ ECUDateofManufacture : 48|8@1+ (1,0) [0|255] "ASCII" Vector__XXX

BO_ 2566768382 CSA: 8 Vector__XXX
 SG_ EngineColdStartFuelIgniterRelay : 24|2@1+ (1,0) [0|3] "" Vector__XXX
 SG_ EngineStartEnableDevice1 : 0|2@1+ (1,0) [0|3] "" Vector__XXX
 SG_ EngineStartEnableDevice2 : 2|2@1+ (1,0) [0|3] "" Vector__XXX
 SG_ EngnCldStrtFlIgntrCmmnd : 16|8@1+ (0.4,0) [0|100] "%" Vector__XXX
 SG_ EngnCldStrtFlIgntrRlFdk : 26|2@1+ (1,0) [0|3] "" Vector__XXX
 SG_ EngnStrtEnlDv1Cnfgrtn : 8|4@1+ (1,0) [0|15] "" Vector__XXX
 SG_ EngnStrtEnlDv2Cnfgrtn : 12|4@1+ (1,0) [0|15] "" Vector__XXX

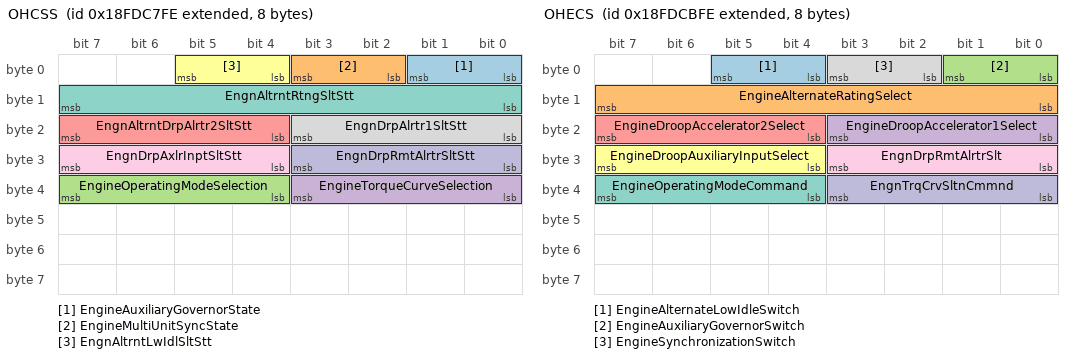
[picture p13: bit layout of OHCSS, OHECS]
BO_ 2566768638 OHCSS: 8 Vector__XXX
 SG_ EngineAuxiliaryGovernorState : 0|2@1+ (1,0) [0|3] "" Vector__XXX
 SG_ EngineMultiUnitSyncState : 2|2@1+ (1,0) [0|3] "" Vector__XXX
 SG_ EngineOperatingModeSelection : 36|4@1+ (1,0) [0|15] "" Vector__XXX
 SG_ EngineTorqueCurveSelection : 32|4@1+ (1,0) [0|15] "" Vector__XXX
 SG_ EngnAltrntDrpAlrtr2SltStt : 20|4@1+ (1,0) [0|15] "" Vector__XXX
 SG_ EngnAltrntLwIdlSltStt : 4|2@1+ (1,0) [0|3] "" Vector__XXX
 SG_ EngnAltrntRtngSltStt : 8|8@1+ (1,0) [0|255] "" Vector__XXX
 SG_ EngnDrpAlrtr1SltStt : 16|4@1+ (1,0) [0|15] "" Vector__XXX
 SG_ EngnDrpAxlrInptSltStt : 28|4@1+ (1,0) [0|15] "" Vector__XXX
 SG_ EngnDrpRmtAlrtrSltStt : 24|4@1+ (1,0) [0|15] "" Vector__XXX

BO_ 2566768894 ISCS: 8 Vector__XXX
 SG_ EngnOprtrPrmrIntrmdtSpdSltStt : 0|4@1+ (1,0) [0|15] "" Vector__XXX

BO_ 2566769406 ISC: 8 Vector__XXX
 SG_ EngnOprtrPrmrIntrmdtSpdSlt : 0|4@1+ (1,0) [0|15] "" Vector__XXX

BO_ 2566769662 OHECS: 8 Vector__XXX
 SG_ EngineAlternateLowIdleSwitch : 4|2@1+ (1,0) [0|3] "" Vector__XXX
 SG_ EngineAlternateRatingSelect : 8|8@1+ (1,0) [0|255] "selection" Vector__XXX
 SG_ EngineAuxiliaryGovernorSwitch : 0|2@1+ (1,0) [0|3] "" Vector__XXX
 SG_ EngineDroopAccelerator1Select : 16|4@1+ (1,0) [0|15] "" Vector__XXX
 SG_ EngineDroopAccelerator2Select : 20|4@1+ (1,0) [0|15] "" Vector__XXX
 SG_ EngineDroopAuxiliaryInputSelect : 28|4@1+ (1,0) [0|15] "" Vector__XXX
 SG_ EngineOperatingModeCommand : 36|4@1+ (1,0) [0|15] "" Vector__XXX
 SG_ EngineSynchronizationSwitch : 2|2@1+ (1,0) [0|3] "" Vector__XXX
 SG_ EngnDrpRmtAlrtrSlt : 24|4@1+ (1,0) [0|15] "" Vector__XXX
 SG_ EngnTrqCrvSltnCmmnd : 32|4@1+ (1,0) [0|15] "" Vector__XXX

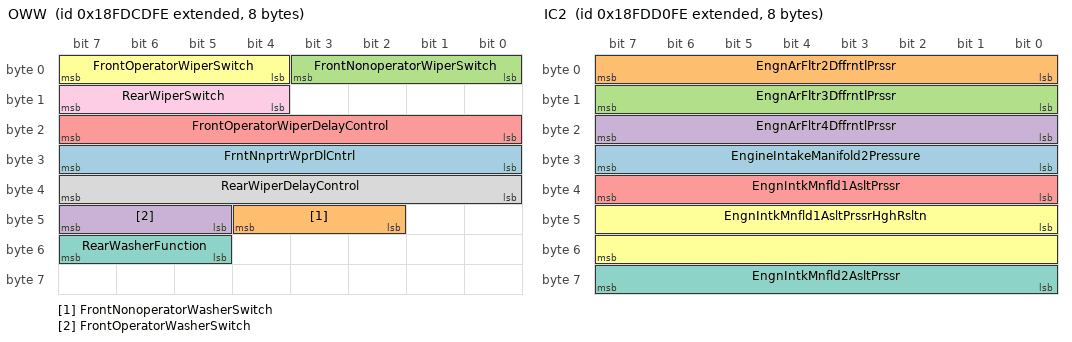
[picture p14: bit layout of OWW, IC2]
BO_ 2566770174 OWW: 8 Vector__XXX
 SG_ FrntNnprtrWprDlCntrl : 24|8@1+ (0.4,0) [0|100] "%" Vector__XXX
 SG_ FrontNonoperatorWasherSwitch : 42|3@1+ (1,0) [0|7] "" Vector__XXX
 SG_ FrontNonoperatorWiperSwitch : 0|4@1+ (1,0) [0|15] "" Vector__XXX
 SG_ FrontOperatorWasherSwitch : 45|3@1+ (1,0) [0|7] "" Vector__XXX
 SG_ FrontOperatorWiperDelayControl : 16|8@1+ (0.4,0) [0|100] "%" Vector__XXX
 SG_ FrontOperatorWiperSwitch : 4|4@1+ (1,0) [0|15] "" Vector__XXX
 SG_ RearWasherFunction : 53|3@1+ (1,0) [0|7] "" Vector__XXX
 SG_ RearWiperDelayControl : 32|8@1+ (0.4,0) [0|100] "%" Vector__XXX
 SG_ RearWiperSwitch : 12|4@1+ (1,0) [0|15] "" Vector__XXX

BO_ 2566770942 IC2: 8 Vector__XXX
 SG_ EngineIntakeManifold2Pressure : 24|8@1+ (2,0) [0|500] "kPa" Vector__XXX
 SG_ EngnArFltr2DffrntlPrssr : 0|8@1+ (0.05,0) [0|12.5] "kPa" Vector__XXX
 SG_ EngnArFltr3DffrntlPrssr : 8|8@1+ (0.05,0) [0|12.5] "kPa" Vector__XXX
 SG_ EngnArFltr4DffrntlPrssr : 16|8@1+ (0.05,0) [0|12.5] "kPa" Vector__XXX
 SG_ EngnIntkMnfld1AsltPrssr : 32|8@1+ (2,0) [0|500] "kPa" Vector__XXX
 SG_ EngnIntkMnfld1AsltPrssrHghRsltn : 40|16@1+ (0.1,0) [0|6425.5] "kPa" Vector__XXX
 SG_ EngnIntkMnfld2AsltPrssr : 56|8@1+ (2,0) [0|500] "kPa" Vector__XXX

BO_ 2566771454 EP: 8 Vector__XXX
 SG_ DataMemoryUsage : 16|8@1+ (0.4,0) [0|100] "%" Vector__XXX
 SG_ KeepAliveBatteryConsumption : 0|16@1+ (1,0) [0|64255] "mAh" Vector__XXX

BO_ 2566771710 TCI6: 8 Vector__XXX
 SG_ EngnTrhrgr1CmprssrOtltTmprtr : 0|16@1+ (0.03125,-273) [-273|1734.96875] "degC" Vector__XXX
 SG_ EngnTrhrgr2CmprssrOtltTmprtr : 16|16@1+ (0.03125,-273) [-273|1734.96875] "degC" Vector__XXX
 SG_ EngnTrhrgr3CmprssrOtltTmprtr : 32|16@1+ (0.03125,-273) [-273|1734.96875] "degC" Vector__XXX
 SG_ EngnTrhrgr4CmprssrOtltTmprtr : 48|16@1+ (0.03125,-273) [-273|1734.96875] "degC" Vector__XXX

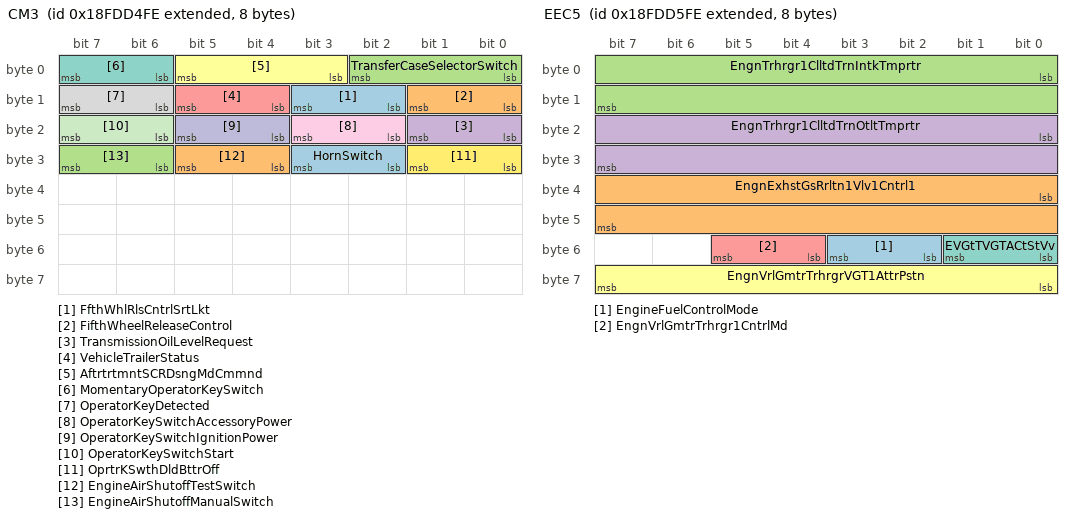
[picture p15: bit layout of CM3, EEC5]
BO_ 2566771966 CM3: 8 Vector__XXX
 SG_ FfthWhlRlsCntrlSrtLkt : 10|2@1+ (1,0) [0|3] "" Vector__XXX
 SG_ FifthWheelReleaseControl : 8|2@1+ (1,0) [0|3] "" Vector__XXX
 SG_ TransferCaseSelectorSwitch : 0|3@1+ (1,0) [0|7] "" Vector__XXX
 SG_ TransmissionOilLevelRequest : 16|2@1+ (1,0) [0|3] "" Vector__XXX
 SG_ VehicleTrailerStatus : 12|2@1+ (1,0) [0|3] "" Vector__XXX
 SG_ AftrtrtmntSCRDsngMdCmmnd : 3|3@1+ (1,0) [0|7] "" Vector__XXX
 SG_ MomentaryOperatorKeySwitch : 6|2@1+ (1,0) [0|3] "" Vector__XXX
 SG_ OperatorKeyDetected : 14|2@1+ (1,0) [0|3] "" Vector__XXX
 SG_ OperatorKeySwitchAccessoryPower : 18|2@1+ (1,0) [0|3] "" Vector__XXX
 SG_ OperatorKeySwitchIgnitionPower : 20|2@1+ (1,0) [0|3] "" Vector__XXX
 SG_ OperatorKeySwitchStart : 22|2@1+ (1,0) [0|3] "" Vector__XXX
 SG_ OprtrKSwthDldBttrOff : 24|2@1+ (1,0) [0|3] "" Vector__XXX
 SG_ HornSwitch : 26|2@1+ (1,0) [0|3] "" Vector__XXX
 SG_ EngineAirShutoffTestSwitch : 28|2@1+ (1,0) [0|3] "" Vector__XXX
 SG_ EngineAirShutoffManualSwitch : 30|2@1+ (1,0) [0|3] "" Vector__XXX

BO_ 2566772222 EEC5: 8 Vector__XXX
 SG_ EngineFuelControlMode : 50|2@1+ (1,0) [0|3] "" Vector__XXX
 SG_ EngnExhstGsRrltn1Vlv1Cntrl1 : 32|16@1+ (0.0025,0) [0|160.6375] "%" Vector__XXX
 SG_ EngnTrhrgr1ClltdTrnIntkTmprtr : 0|16@1+ (0.03125,-273) [-273|1734.96875] "degC" Vector__XXX
 SG_ EngnTrhrgr1ClltdTrnOtltTmprtr : 16|16@1+ (0.03125,-273) [-273|1734.96875] "degC" Vector__XXX
 SG_ EngnVrlGmtrTrhrgr1CntrlMd : 52|2@1+ (1,0) [0|3] "" Vector__XXX
 SG_ EngnVrlGmtrTrhrgrVGT1AttrPstn : 56|8@1+ (0.4,0) [0|100] "%" Vector__XXX
 SG_ EVGtTVGTACtStVv : 48|2@1+ (1,0) [0|3] "" Vector__XXX

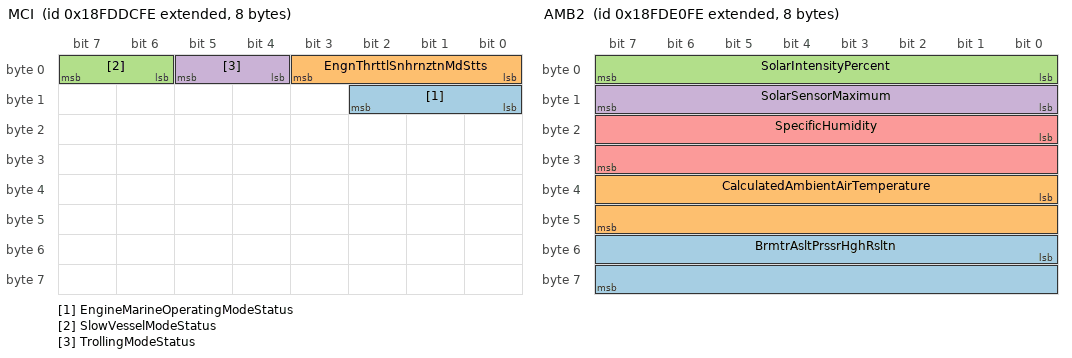
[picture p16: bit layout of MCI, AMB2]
BO_ 2566774014 MCI: 8 Vector__XXX
 SG_ EngineMarineOperatingModeStatus : 8|3@1+ (1,0) [0|7] "" Vector__XXX
 SG_ EngnThrttlSnhrnztnMdStts : 0|4@1+ (1,0) [0|15] "" Vector__XXX
 SG_ SlowVesselModeStatus : 6|2@1+ (1,0) [0|3] "" Vector__XXX
 SG_ TrollingModeStatus : 4|2@1+ (1,0) [0|3] "" Vector__XXX

BO_ 2566775038 AMB2: 8 Vector__XXX
 SG_ BrmtrAsltPrssrHghRsltn : 48|16@1+ (0.1,0) [0|6425.5] "kPa" Vector__XXX
 SG_ CalculatedAmbientAirTemperature : 32|16@1+ (0.03125,-273) [-273|1734.96875] "degC" Vector__XXX
 SG_ SolarIntensityPercent : 0|8@1+ (0.4,0) [0|100] "%" Vector__XXX
 SG_ SolarSensorMaximum : 8|8@1+ (0.4,0) [0|100] "mW/(cm*cm)" Vector__XXX
 SG_ SpecificHumidity : 16|16@1+ (0.01,0) [0|642.55] "g/kg" Vector__XXX

BO_ 2566775294 CCSI1: 8 Vector__XXX
 SG_ AirConditionerCompressorStatus : 8|2@1+ (1,0) [0|3] "" Vector__XXX
 SG_ CACRfrgrntCmprssrOtltPrssr : 0|8@1+ (16,0) [0|4000] "kPa" Vector__XXX

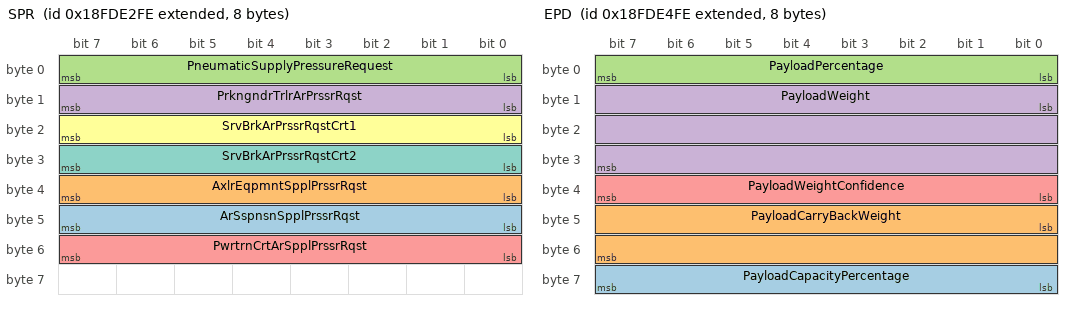
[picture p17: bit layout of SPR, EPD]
BO_ 2566775550 SPR: 8 Vector__XXX
 SG_ ArSspnsnSpplPrssrRqst : 40|8@1+ (8,0) [0|2000] "kPa" Vector__XXX
 SG_ AxlrEqpmntSpplPrssrRqst : 32|8@1+ (8,0) [0|2000] "kPa" Vector__XXX
 SG_ PneumaticSupplyPressureRequest : 0|8@1+ (8,0) [0|2000] "kPa" Vector__XXX
 SG_ PrkngndrTrlrArPrssrRqst : 8|8@1+ (8,0) [0|2000] "kPa" Vector__XXX
 SG_ PwrtrnCrtArSpplPrssrRqst : 48|8@1+ (8,0) [0|2000] "kPa" Vector__XXX
 SG_ SrvBrkArPrssrRqstCrt1 : 16|8@1+ (8,0) [0|2000] "kPa" Vector__XXX
 SG_ SrvBrkArPrssrRqstCrt2 : 24|8@1+ (8,0) [0|2000] "kPa" Vector__XXX

BO_ 2566775806 EOAC: 8 Vector__XXX
 SG_ TravelVelocityControlPosition : 0|8@1+ (1,-125) [-125|125] "%" Vector__XXX

BO_ 2566776062 EPD: 8 Vector__XXX
 SG_ PayloadCapacityPercentage : 56|8@1+ (1,0) [0|250] "%" Vector__XXX
 SG_ PayloadCarryBackWeight : 40|16@1+ (2,0) [0|128510] "kg" Vector__XXX
 SG_ PayloadPercentage : 0|8@1+ (1,0) [0|250] "%" Vector__XXX
 SG_ PayloadWeight : 8|24@1+ (2,0) [0|32899070] "kg" Vector__XXX
 SG_ PayloadWeightConfidence : 32|8@1+ (0.5,0) [0|125] "%" Vector__XXX

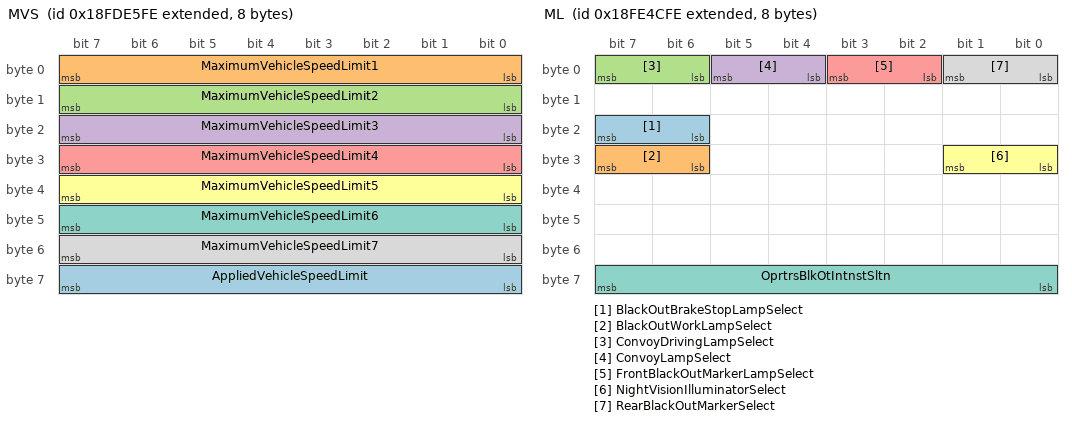
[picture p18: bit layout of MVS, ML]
BO_ 2566776318 MVS: 8 Vector__XXX
 SG_ AppliedVehicleSpeedLimit : 56|8@1+ (1,0) [0|250] "km/h" Vector__XXX
 SG_ MaximumVehicleSpeedLimit1 : 0|8@1+ (1,0) [0|250] "km/h" Vector__XXX
 SG_ MaximumVehicleSpeedLimit2 : 8|8@1+ (1,0) [0|250] "km/h" Vector__XXX
 SG_ MaximumVehicleSpeedLimit3 : 16|8@1+ (1,0) [0|250] "km/h" Vector__XXX
 SG_ MaximumVehicleSpeedLimit4 : 24|8@1+ (1,0) [0|250] "km/h" Vector__XXX
 SG_ MaximumVehicleSpeedLimit5 : 32|8@1+ (1,0) [0|250] "km/h" Vector__XXX
 SG_ MaximumVehicleSpeedLimit6 : 40|8@1+ (1,0) [0|250] "km/h" Vector__XXX
 SG_ MaximumVehicleSpeedLimit7 : 48|8@1+ (1,0) [0|250] "km/h" Vector__XXX

BO_ 2566785022 ET: 8 Vector__XXX
 SG_ EngnExhstMnfldBnk1Tmprtr1 : 16|16@1+ (0.03125,-273) [-273|1734.96875] "degC" Vector__XXX
 SG_ EngnExhstMnfldBnk1Tmprtr2 : 48|16@1+ (0.03125,-273) [-273|1734.96875] "degC" Vector__XXX
 SG_ EngnExhstMnfldBnk2Tmprtr1 : 0|16@1+ (0.03125,-273) [-273|1734.96875] "degC" Vector__XXX
 SG_ EngnExhstMnfldBnk2Tmprtr2 : 32|16@1+ (0.03125,-273) [-273|1734.96875] "degC" Vector__XXX

BO_ 2566799614 LD: 8 Vector__XXX
 SG_ AlternateBeamHeadLightData : 2|2@1+ (1,0) [0|3] "" Vector__XXX
 SG_ BackUpLightandAlarmHorn : 16|2@1+ (1,0) [0|3] "" Vector__XXX
 SG_ CenterStopLight : 18|2@1+ (1,0) [0|3] "" Vector__XXX
 SG_ HighBeamHeadLightData : 6|2@1+ (1,0) [0|3] "" Vector__XXX
 SG_ ImplementClearanceLight : 24|2@1+ (1,0) [0|3] "" Vector__XXX
 SG_ ImplementLeftFacingWorkLight : 60|2@1+ (1,0) [0|3] "" Vector__XXX
 SG_ ImplementLeftForwardWorkLight : 54|2@1+ (1,0) [0|3] "" Vector__XXX
 SG_ ImplementMarkerLight : 28|2@1+ (1,0) [0|3] "" Vector__XXX
 SG_ ImplementOEMOption1Light : 50|2@1+ (1,0) [0|3] "" Vector__XXX
 SG_ ImplementOEMOption2Light : 48|2@1+ (1,0) [0|3] "" Vector__XXX
 SG_ ImplementRearWorkLight : 62|2@1+ (1,0) [0|3] "" Vector__XXX
 SG_ ImplementRightFacingWorkLight : 52|2@1+ (1,0) [0|3] "" Vector__XXX
 SG_ ImplementRightForwardWorkLight : 58|2@1+ (1,0) [0|3] "" Vector__XXX
 SG_ LeftStopLight : 22|2@1+ (1,0) [0|3] "" Vector__XXX
 SG_ LeftTurnSignalLights : 14|2@1+ (1,0) [0|3] "" Vector__XXX
 SG_ LowBeamHeadLightData : 4|2@1+ (1,0) [0|3] "" Vector__XXX
 SG_ RearFogLights : 32|2@1+ (1,0) [0|3] "" Vector__XXX
 SG_ RightStopLight : 20|2@1+ (1,0) [0|3] "" Vector__XXX
 SG_ RightTurnSignalLights : 12|2@1+ (1,0) [0|3] "" Vector__XXX
 SG_ RotatingBeaconLight : 10|2@1+ (1,0) [0|3] "" Vector__XXX
 SG_ RunningLight : 0|2@1+ (1,0) [0|3] "" Vector__XXX
 SG_ TractorClearanceLight : 26|2@1+ (1,0) [0|3] "" Vector__XXX
 SG_ TractorFrontFogLights : 8|2@1+ (1,0) [0|3] "" Vector__XXX
 SG_ TractorMarkerLight : 30|2@1+ (1,0) [0|3] "" Vector__XXX
 SG_ TractorRearLowMountedWorkLights : 36|2@1+ (1,0) [0|3] "" Vector__XXX
 SG_ TractorSideLowMountedWorkLights : 40|2@1+ (1,0) [0|3] "" Vector__XXX
 SG_ TrtrFrntHghMntdWrkLghts : 46|2@1+ (1,0) [0|3] "" Vector__XXX
 SG_ TrtrFrntLwMntdWrkLghts : 44|2@1+ (1,0) [0|3] "" Vector__XXX
 SG_ TrtrRrHghMntdWrkLghts : 38|2@1+ (1,0) [0|3] "" Vector__XXX
 SG_ TrtrSdHghMntdWrkLghts : 42|2@1+ (1,0) [0|3] "" Vector__XXX
 SG_ TrtrUndrsdMntdWrkLghts : 34|2@1+ (1,0) [0|3] "" Vector__XXX

BO_ 2566802174 ETC7: 8 Vector__XXX
 SG_ ActiveShiftConsoleIndicator : 10|2@1+ (1,0) [0|3] "" Vector__XXX
 SG_ TransmissionEngineCrankEnable : 12|2@1+ (1,0) [0|3] "" Vector__XXX
 SG_ TransmissionManualModeIndicator : 54|2@1+ (1,0) [0|3] "" Vector__XXX
 SG_ TransmissionMode10Indicator : 46|2@1+ (1,0) [0|3] "" Vector__XXX
 SG_ TransmissionMode1Indicator : 22|2@1+ (1,0) [0|3] "" Vector__XXX
 SG_ TransmissionMode2Indicator : 20|2@1+ (1,0) [0|3] "" Vector__XXX
 SG_ TransmissionMode3Indicator : 18|2@1+ (1,0) [0|3] "" Vector__XXX
 SG_ TransmissionMode4Indicator : 16|2@1+ (1,0) [0|3] "" Vector__XXX
 SG_ TransmissionMode5Indicator : 32|2@1+ (1,0) [0|3] "" Vector__XXX
 SG_ TransmissionMode6Indicator : 34|2@1+ (1,0) [0|3] "" Vector__XXX
 SG_ TransmissionMode7Indicator : 36|2@1+ (1,0) [0|3] "" Vector__XXX
 SG_ TransmissionMode8Indicator : 38|2@1+ (1,0) [0|3] "" Vector__XXX
 SG_ TransmissionMode9Indicator : 44|2@1+ (1,0) [0|3] "" Vector__XXX
 SG_ TransmissionServiceIndicator : 2|2@1+ (1,0) [0|3] "" Vector__XXX
 SG_ TransmissionWarningIndicator : 42|2@1+ (1,0) [0|3] "" Vector__XXX
 SG_ TrnsmssnArSpplPrssrIndtr : 48|3@1+ (1,0) [0|7] "" Vector__XXX
 SG_ TrnsmssnAtNtrlMnlRtrnStt : 51|3@1+ (1,0) [0|7] "" Vector__XXX
 SG_ TrnsmssnCrrntRngDsplBlnkStt : 0|2@1+ (1,0) [0|3] "" Vector__XXX
 SG_ TrnsmssnRdfrBrkRls : 8|2@1+ (1,0) [0|3] "" Vector__XXX
 SG_ TrnsmssnRqstdGrFdk : 24|8@1+ (1,-125) [-125|125] "gear value" Vector__XXX
 SG_ TrnsmssnRqstdRngDsplBlnkStt : 4|2@1+ (1,0) [0|3] "" Vector__XXX
 SG_ TrnsmssnRqstdRngDsplFlshStt : 6|2@1+ (1,0) [0|3] "" Vector__XXX
 SG_ TrnsmssnRvrsGrShftInhtStts : 40|2@1+ (1,0) [0|3] "" Vector__XXX
 SG_ TrnsmssnShftInhtIndtr : 14|2@1+ (1,0) [0|3] "" Vector__XXX
 SG_ TrnsmssnLdRdtnIndtr : 56|2@1+ (1,0) [0|3] "" Vector__XXX
 SG_ TrnsmssnPrDfndRngLmtIndtr : 58|2@1+ (1,0) [0|3] "" Vector__XXX
 SG_ TransmissionCoastModeIndicator : 60|2@1+ (1,0) [0|3] "" Vector__XXX

BO_ 2566802430 TCFG2: 8 Vector__XXX
 SG_ TransmissionReferenceTorque : 16|16@1+ (1,0) [0|64255] "Nm" Vector__XXX
 SG_ TransmissionTorqueLimit : 0|16@1+ (1,0) [0|64255] "Nm" Vector__XXX
 SG_ TrnsmssnCmmntnsFlrIdlTrqLmt : 32|8@1+ (1,-125) [-125|125] "%" Vector__XXX

BO_ 2566802686 ML: 8 Vector__XXX
 SG_ BlackOutBrakeStopLampSelect : 22|2@1+ (1,0) [0|3] "" Vector__XXX
 SG_ BlackOutWorkLampSelect : 30|2@1+ (1,0) [0|3] "" Vector__XXX
 SG_ ConvoyDrivingLampSelect : 6|2@1+ (1,0) [0|3] "" Vector__XXX
 SG_ ConvoyLampSelect : 4|2@1+ (1,0) [0|3] "" Vector__XXX
 SG_ FrontBlackOutMarkerLampSelect : 2|2@1+ (1,0) [0|3] "" Vector__XXX
 SG_ NightVisionIlluminatorSelect : 24|2@1+ (1,0) [0|3] "" Vector__XXX
 SG_ OprtrsBlkOtIntnstSltn : 56|8@1+ (0.4,0) [0|100] "%" Vector__XXX
 SG_ RearBlackOutMarkerSelect : 0|2@1+ (1,0) [0|3] "" Vector__XXX

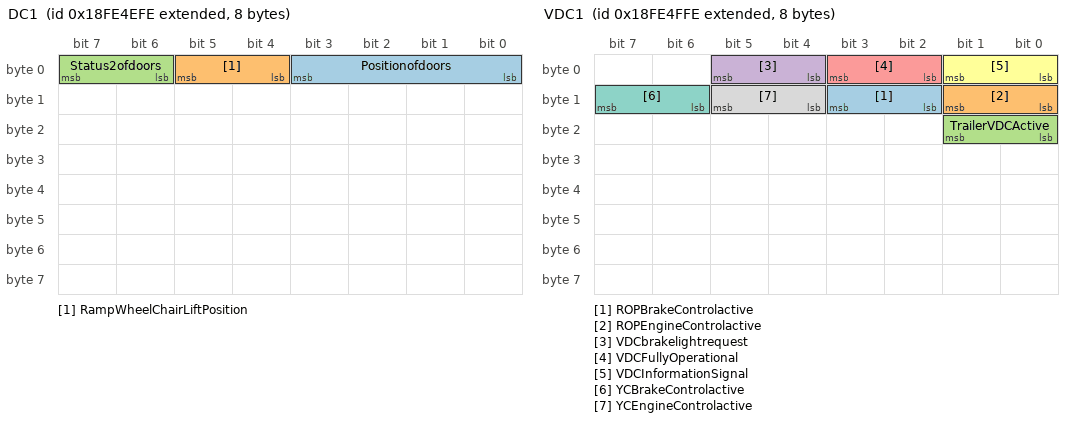
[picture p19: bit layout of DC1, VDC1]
BO_ 2566803198 DC1: 8 Vector__XXX
 SG_ Positionofdoors : 0|4@1+ (1,0) [0|15] "" Vector__XXX
 SG_ RampWheelChairLiftPosition : 4|2@1+ (1,0) [0|3] "" Vector__XXX
 SG_ Status2ofdoors : 6|2@1+ (1,0) [0|3] "" Vector__XXX

BO_ 2566803454 VDC1: 8 Vector__XXX
 SG_ ROPBrakeControlactive : 10|2@1+ (1,0) [0|3] "" Vector__XXX
 SG_ ROPEngineControlactive : 8|2@1+ (1,0) [0|3] "" Vector__XXX
 SG_ TrailerVDCActive : 16|2@1+ (1,0) [0|3] "" Vector__XXX
 SG_ VDCbrakelightrequest : 4|2@1+ (1,0) [0|3] "" Vector__XXX
 SG_ VDCFullyOperational : 2|2@1+ (1,0) [0|3] "" Vector__XXX
 SG_ VDCInformationSignal : 0|2@1+ (1,0) [0|3] "" Vector__XXX
 SG_ YCBrakeControlactive : 14|2@1+ (1,0) [0|3] "" Vector__XXX
 SG_ YCEngineControlactive : 12|2@1+ (1,0) [0|3] "" Vector__XXX

BO_ 2566803710 BT1: 8 Vector__XXX
 SG_ SLIBattery1Temperature : 0|8@1+ (1,-40) [-40|210] "degC" Vector__XXX
 SG_ SLIBattery2Temperature : 8|8@1+ (1,-40) [-40|210] "degC" Vector__XXX
 SG_ SLIBattery3Temperature : 16|8@1+ (1,-40) [-40|210] "degC" Vector__XXX
 SG_ SLIBattery4Temperature : 24|8@1+ (1,-40) [-40|210] "degC" Vector__XXX

BO_ 2566803966 ACC2: 8 Vector__XXX
 SG_ ACCusagedemand : 0|2@1+ (1,0) [0|3] "" Vector__XXX
 SG_ RequestedACCDistanceMode : 5|3@1+ (1,0) [0|7] "" Vector__XXX

CM_ BO_ 2566756606 "Aftertreatment 1 Historical Information 1";
CM_ SG_ 2566756606 Aftertreatment1TotalFuelUsed "Aftertreatment 1 Total Fuel Used: Total amount of fuel used by aftertreatment device 1 over the lifetime of the device.";
CM_ SG_ 2566756606 Aftrtrtmnt1TtlDsldTm "Aftertreatment 1 Total Disabled Time: Total amount of time that aftertreatment 1 regeneration has been manually disabled.";
CM_ SG_ 2566756606 Aftrtrtmnt1TtlNmrfAtvRgnrtns "Aftertreatment 1 Total Number of Active Regenerations: Total number of active regenerations by aftertreatment device 1 over the lifetime of the device.";
CM_ SG_ 2566756606 Aftrtrtmnt1TtlRgnrtnTm "Aftertreatment 1 Total Regeneration Time: Total amount of time that aftertreatment device 1 has been regenerating over the lifetime of the device.";
CM_ SG_ 2566756606 Atttt1DsPttFtAvDstBtwAtvRts "Aftertreatment 1 Diesel Particulate Filter Average Distance Between Active Regenerations: Indicates the average distance since last reset between active regenerations, that have not been forced to occur by manual request, for aftertreatment device 1....";
CM_ SG_ 2566756606 Atttt1DsPttFtAvTBtwAtvRts "Aftertreatment 1 Diesel Particulate Filter Average Time Between Active Regenerations: Indicates the average time since last reset between active regenerations, that have not been forced to occur by manual request, for Aftertreatment device 1.If the m...";
CM_ SG_ 2566756606 Atttt1DsPttFtTtNAtvRtItRqsts "Aftertreatment 1 Diesel Particulate Filter Total Number of Active Regeneration Inhibit Requests: Total number of aftertreatment device 1 active regeneration inhibit requests by the operator over the lifetime of the device.";
CM_ SG_ 2566756606 Atttt1DsPttFtTtNAtvRtMRqsts "Aftertreatment 1 Diesel Particulate Filter Total Number of Active Regeneration Manual Requests: Total number of aftertreatment device 1 active regeneration manual requests by the operator over the lifetime of the device.";
CM_ SG_ 2566756606 Atttt1DsPttFtTtNPssvRts "Aftertreatment 1 Diesel Particulate Filter Total Number of Passive Regenerations: Total number of passive regenerations by aftertreatment device 1 over the lifetime of the device.";
CM_ SG_ 2566756606 Atttt1DsPttFtTtPssvRtT "Aftertreatment 1 Diesel Particulate Filter Total Passive Regeneration Time: Total amount of time that aftertreatment 1 diesel particulate filter has been in passive regeneration over the lifetime of the device.";
CM_ BO_ 2566756862 "Aftertreatment 2 Historical information 1";
CM_ SG_ 2566756862 Aftertreatment2TotalFuelUsed "Aftertreatment 2 Total Fuel Used: Total amount of fuel used by aftertreatment device 2 over the lifetime of the device.";
CM_ SG_ 2566756862 Aftrtrtmnt2TtlDsldTm "Aftertreatment 2 Total Disabled Time: Total amount of time that aftertreatment 2 regeneration has been manually disabled.";
CM_ SG_ 2566756862 Aftrtrtmnt2TtlNmrfAtvRgnrtns "Aftertreatment 2 Total Number of Active Regenerations: Total number of active regenerations by aftertreatment device 2 over the lifetime of the device.";
CM_ SG_ 2566756862 Aftrtrtmnt2TtlRgnrtnTm "Aftertreatment 2 Total Regeneration Time: Total amount of time that aftertreatment device 2 has been regenerating over the lifetime of the device.";
CM_ SG_ 2566756862 Atttt2DsPttFtAvDstBtwAtvRts "Aftertreatment 2 Diesel Particulate Filter Average Distance Between Active Regenerations: Indicates the average distance since last reset between active regenerations, that have not been forced to occur by manual request, for aftertreatment device 2....";
CM_ SG_ 2566756862 Atttt2DsPttFtAvTBtwAtvRts "Aftertreatment 2 Diesel Particulate Filter Average Time Between Active Regenerations: Indicates the average time since last reset between active regenerations, that have not been forced to occur by manual request, for Aftertreatment device 2.";
CM_ SG_ 2566756862 Atttt2DsPttFtTtNAtvRtItRqsts "Aftertreatment 2 Diesel Particulate Filter Total Number of Active Regeneration Inhibit Requests: Total number of Aftertreatment device 2 active regeneration inhibit requests by the operator over the lifetime of the device.";
CM_ SG_ 2566756862 Atttt2DsPttFtTtNAtvRtMRqsts "Aftertreatment 2 Diesel Particulate Filter Total Number of Active Regeneration Manual Requests: Total number of Aftertreatment device 2 active regeneration manual requests by the operator over the lifetime of the device.";
CM_ SG_ 2566756862 Atttt2DsPttFtTtNPssvRts "Aftertreatment 2 Diesel Particulate Filter Total Number of Passive Regenerations: Total number of passive regenerations by Aftertreatment device 2 over the lifetime of the device.";
CM_ SG_ 2566756862 Atttt2DsPttFtTtPssvRtT "Aftertreatment 2 Diesel Particulate Filter Total Passive Regeneration Time: Total amount of time that Aftertreatment device 2 has been in passive regeneration over the lifetime of the device.";
CM_ BO_ 2566757374 "Aftertreatment 1 Diesel Exhaust Fluid Information 1";
CM_ SG_ 2566757374 Aftrtrtmnt1DslExhstFldCndtvt "Aftertreatment 1 Diesel Exhaust Fluid Conductivity: A measure of the conductivity of the diesel exhaust fluid at the sensor.  The conductivity is an indication of the diesel exhaust fluid's chemical make up.";
CM_ SG_ 2566757374 Aftrtrtmnt1DslExhstFldCnntrtn "Aftertreatment 1 Diesel Exhaust Fluid Concentration: A measure of the concentration of urea in water.  Zero percent means that the tank contains no urea.  A 32.5% value indicates that the diesel exhaust fluid is of the proper concentration.  The 32.5...";
CM_ SG_ 2566757374 Aftrtrtmnt1DslExhstFldPrprt "Aftertreatment 1 Diesel Exhaust Fluid Property: This parameter indicates the property of the fluid compound in the tank.  A value of 0011b indicates uncontaminated Diesel Exhaust Fluid.0000b = Urea concentration too high0001b = Urea concentration too...";
CM_ SG_ 2566757374 Aftrtrtmnt1DslExhstFldTmprtr2 "Aftertreatment 1 Diesel Exhaust Fluid Temperature 2: Temperature of the diesel exhaust fluid at the device measuring diesel exhaust fluid quality";
CM_ SG_ 2566757374 Atttt1DsExstFdPptsPFMI "Aftertreatment 1 Diesel Exhaust Fluid Properties Preliminary FMI: Used to identify the applicable J1939-73 FMI that applies to the most significant failure of the diesel exhaust fluid properties sensor.  This may be used for indicating failures of th...";
CM_ SG_ 2566757374 Atttt1DsExstFdTpt2PFMI "Aftertreatment 1 Diesel Exhaust Fluid Temperature 2 Preliminary FMI: Used to identify the applicable J1939-73 FMI that applies to the most significant failure of the diesel exhaust fluid temperature sensor.  In the case of multiple failures the most ...";
CM_ SG_ 2566757374 DieselExhaustFluidSpeedofSound "Diesel Exhaust Fluid Speed of Sound: The speed of sound in the fluid that is in the diesel exhaust fluid tank.";
CM_ BO_ 2566757630 "Sensor Electrical Power #2";
CM_ SG_ 2566757630 Sensorsupplyvoltage5 "Sensor supply voltage 5: Sensor ECU supply voltage 5";
CM_ SG_ 2566757630 Sensorsupplyvoltage6 "Sensor supply voltage 6: Sensor ECU supply voltage 6";
CM_ SG_ 2566757630 Sensorsupplyvoltage7 "Sensor supply voltage 7: Sensor ECU supply voltage 7";
CM_ SG_ 2566757630 Sensorsupplyvoltage8 "Sensor supply voltage 8: Sensor ECU supply voltage 8";
CM_ BO_ 2566757886 "Sensor Electrical Power #1";
CM_ SG_ 2566757886 Sensorsupplyvoltage1 "Sensor supply voltage 1: Sensor ECU supply voltage 1";
CM_ SG_ 2566757886 Sensorsupplyvoltage2 "Sensor supply voltage 2: Sensor ECU supply voltage 2";
CM_ SG_ 2566757886 Sensorsupplyvoltage3 "Sensor supply voltage 3: Sensor ECU supply voltage 3";
CM_ SG_ 2566757886 Sensorsupplyvoltage4 "Sensor supply voltage 4: Sensor ECU supply voltage 4";
CM_ BO_ 2566758142 "Aftertreatment 2 Air Control 1";
CM_ SG_ 2566758142 Aftertreatment2AirSystemRelay "Aftertreatment 2 Air System Relay: Indicates whether aftertreatment 2 air system relay is on or off00b = not active01b = active10b = reserved for SAE assignment11b = not available";
CM_ SG_ 2566758142 Aftertreatment2PurgeAirActuator "Aftertreatment 2 Purge Air Actuator: Indicates whether aftertreatment 2 purge air actuator is on or off00b = not active01b = active10b = reserved for SAE assignment11b = not available";
CM_ SG_ 2566758142 Aftertreatment2PurgeAirPressure "Aftertreatment 2 Purge Air Pressure: Pressure of the purge air supply for aftertreatment 2";
CM_ SG_ 2566758142 Aftrtrtmnt2ArEnlAttr "Aftertreatment 2 Air Enable Actuator: Indicates whether aftertreatment 2 air enable actuator is on or off00b = not active01b = active10b = reserved for SAE assignment11b = not available";
CM_ SG_ 2566758142 Aftrtrtmnt2ArPrssrAttrPstn "Aftertreatment 2 Air Pressure Actuator Position: Position of the aftertreatment 2 air pressure actuator as measured by a position feedback sensor.";
CM_ SG_ 2566758142 Aftrtrtmnt2ArPrssrCntrl "Aftertreatment 2 Air Pressure Control: Position that the controller is commanding the aftertreatment 2 air pressure control to maintain.  0% = fully closed, 100% = fully open";
CM_ SG_ 2566758142 Aftrtrtmnt2AtmztnArAttr "Aftertreatment 2 Atomization Air Actuator: Indicates whether aftertreatment 2 atomization air actuator is on or off00b = not active01b = active10b = reserved for SAE assignment11b = not available";
CM_ SG_ 2566758142 Aftrtrtmnt2SpplArPrssr "Aftertreatment 2 Supply Air Pressure: Pressure of the supply air for aftertreatment 2.  Supply air is the air supplied from a pneumatic line for an air-assisted or pneumatic actuator.  One example is an air assisted fuel injector (the supply air assi...";
CM_ BO_ 2566758398 "Aftertreatment 1 Air Control 1";
CM_ SG_ 2566758398 Aftertreatment1AirSystemRelay "Aftertreatment 1 Air System Relay: Indicates whether aftertreatment 1 air system relay is on or off00b = not active01b = active10b = reserved for SAE assignment11b = not available";
CM_ SG_ 2566758398 Aftertreatment1PurgeAirActuator "Aftertreatment 1 Purge Air Actuator: Indicates whether aftertreatment 1 purge air actuator is on or off00b = not active01b = active10b = reserved for SAE assignment11b = not available";
CM_ SG_ 2566758398 Aftertreatment1PurgeAirPressure "Aftertreatment 1 Purge Air Pressure: Pressure of the purge air supply for aftertreatment 1";
CM_ SG_ 2566758398 Aftrtrtmnt1ArEnlAttr "Aftertreatment 1 Air Enable Actuator: Indicates whether aftertreatment 1 air enable actuator is on or off00b = not active01b = active10b = reserved for SAE assignment11b = not available";
CM_ SG_ 2566758398 Aftrtrtmnt1ArPrssrAttrPstn "Aftertreatment 1 Air Pressure Actuator Position: Position of the aftertreatment 1 air pressure actuator as measured by a position feedback sensor.";
CM_ SG_ 2566758398 Aftrtrtmnt1ArPrssrCntrl "Aftertreatment 1 Air Pressure Control: Position that the controller is commanding the aftertreatment 1 air pressure control to maintain.  0% = fully closed, 100% = fully open";
CM_ SG_ 2566758398 Aftrtrtmnt1AtmztnArAttr "Aftertreatment 1 Atomization Air Actuator: Indicates whether aftertreatment 1 atomization air actuator is on or off00b = not active01b = active10b = reserved for SAE assignment11b = not available";
CM_ SG_ 2566758398 Aftrtrtmnt1SpplArPrssr "Aftertreatment 1 Supply Air Pressure: Pressure of the supply air for aftertreatment 1.  Supply air is the air supplied from a pneumatic line for an air-assisted or pneumatic actuator.  One example is an air assisted fuel injector (the supply air assi...";
CM_ BO_ 2566758654 "Aftertreatment 2 Fuel Control 1";
CM_ SG_ 2566758654 Aftertreatment2FuelPressure1 "Aftertreatment 2 Fuel Pressure 1: Pressure of the fuel for Aftertreatment 2.";
CM_ SG_ 2566758654 Aftertreatment2FuelRate "Aftertreatment 2 Fuel Rate: Rate of fuel being delivered to aftertreatment 2 for regeneration";
CM_ SG_ 2566758654 Aftertreatment2Ignition "Aftertreatment 2 Ignition: Indicates whether aftertreatment 2 ignition circuit is energized by the ECU.00b = not active01b = active10b = reserved for SAE assignment11b = not available";
CM_ SG_ 2566758654 Aftrtrtmnt2FlDrnAttr "Aftertreatment 2 Fuel Drain Actuator: Indicates whether aftertreatment 2 fuel drain actuator is on or off00b = not active01b = active10b = reserved for SAE assignment11b = not available";
CM_ SG_ 2566758654 Aftrtrtmnt2FlEnlAttr "Aftertreatment 2 Fuel Enable Actuator: Indicates whether aftertreatment 2 fuel enable actuator is on or off00b = not active01b = active10b = reserved for SAE assignment11b = not available";
CM_ SG_ 2566758654 Aftrtrtmnt2FlInjtr1HtrCntrl "Aftertreatment 2 Fuel Injector 1 Heater Control: Heating level that the controller is commanding the aftertreatment 2 fuel injector 1 heater control to maintain. 0% = off, 100% = maximum.";
CM_ SG_ 2566758654 Aftrtrtmnt2FlPrssr1Cntrl "Aftertreatment 2 Fuel Pressure 1 Control: Position that the controller is commanding the aftertreatment 2 fuel pressure control to maintain.  0% = fully closed, 100% = fully open.";
CM_ SG_ 2566758654 Aftrtrtmnt2RgnrtnStts "Aftertreatment 2 Regeneration Status: Indicates whether regeneration is active or inactive in aftertreatment 2.  00b = not active01b = active10b = reserved for SAE assignment11b = not available";
CM_ BO_ 2566758910 "Aftertreatment 1 Fuel Control 1";
CM_ SG_ 2566758910 Aftertreatment1FuelPressure1 "Aftertreatment 1 Fuel Pressure 1: First fuel pressure measurement for the aftertreatment 1 system";
CM_ SG_ 2566758910 Aftertreatment1FuelRate "Aftertreatment 1 Fuel Rate: Rate of fuel being delivered to aftertreatment 1 for regeneration";
CM_ SG_ 2566758910 Aftertreatment1Ignition "Aftertreatment 1 Ignition: Indicates whether aftertreatment 1 ignition circuit is energized by the ECU.00b = not active01b = active10b = reserved for SAE assignment11b = not available";
CM_ SG_ 2566758910 Aftrtrtmnt1FlDrnAttr "Aftertreatment 1 Fuel Drain Actuator: Indicates whether aftertreatment 1 fuel drain actuator is on or off00b = not active01b = active10b = reserved for SAE assignment11b = not available";
CM_ SG_ 2566758910 Aftrtrtmnt1FlEnlAttr "Aftertreatment 1 Fuel Enable Actuator: Indicates whether aftertreatment 1 fuel enable actuator is on or off00b = not active01b = active10b = reserved for SAE assignment11b = not available";
CM_ SG_ 2566758910 Aftrtrtmnt1FlInjtr1HtrCntrl "Aftertreatment 1 Fuel Injector 1 Heater Control: Heating level that the controller is commanding the aftertreatment 1 fuel injector 1 heater control to maintain. 0% = off, 100% = maximum.";
CM_ SG_ 2566758910 Aftrtrtmnt1FlPrssr1Cntrl "Aftertreatment 1 Fuel Pressure 1 Control: Position that the controller is commanding the aftertreatment 1 fuel pressure control to maintain.  0% = fully closed, 100% = fully open.";
CM_ SG_ 2566758910 Aftrtrtmnt1RgnrtnStts "Aftertreatment 1 Regeneration Status: Indicates whether regeneration is active or inactive in aftertreatment 1.  00b = not active01b = active10b = reserved for SAE assignment11b = not available";
CM_ BO_ 2566759678 "PTO Drive Engagement";
CM_ SG_ 2566759678 AtleastonePTOengaged "At least one PTO engaged: Indicates that at least one PTO is engaged00b = No PTO drive is engaged01b = At least one PTO drive is engaged10b = Error11b = Not availableNote:  This parameter should only be sent by the controller that has knowledge of al...";
CM_ SG_ 2566759678 EnableSwitchPTOEngineFlywheel "Enable Switch - PTO Engine Flywheel: Status of the PTO Engine Flywheel enable switch00b = Enable switch off – PTO operation not desired01b = Enable switch on – PTO operation desired 10b = Error11b = Not available";
CM_ SG_ 2566759678 EnggmntCnsntPTOEngnAssrDrv1 "Engagement Consent - PTO Engine Accessory Drive 1: Engagement consent status for the PTO engine accessory drive 100b = Consent not given – PTO drive may not be engaged01b = Consent given – PTO drive may be engaged10b = Error11b = Not available...";
CM_ SG_ 2566759678 EnggmntCnsntPTOEngnAssrDrv2 "Engagement Consent - PTO Engine Accessory Drive 2: Engagement Consent status for the PTO engine accessory drive 2 00b = Consent not given – PTO drive may not be engaged01b = Consent given – PTO drive may be engaged10b = Error11b = Not available...";
CM_ SG_ 2566759678 EnggmntCnsntPTOEngnFlwhl "Engagement Consent - PTO Engine Flywheel: Engagement Consent status for the PTO Engine Flywheel00b = Consent not given – PTO drive may not be engaged01b = Consent given – PTO drive may be engaged10b = Error11b = Not available";
CM_ SG_ 2566759678 EnggmntSttsPTOEngnAssrDrv1 "Engagement Status - PTO Engine Accessory Drive 1: Engagement status of the PTO engine accessory drive 100b = Drive not engaged01b = Drive engaged10b = Error11b = Not available";
CM_ SG_ 2566759678 EnggmntSttsPTOEngnAssrDrv2 "Engagement Status - PTO Engine Accessory Drive 2: Engagement status of the PTO engine accessory drive 200b = Drive not engaged01b = Drive engaged10b = Error11b = Not available";
CM_ SG_ 2566759678 EnggmntSttsPTOEngnFlwhl "Engagement Status - PTO Engine Flywheel: Engagement status of the PTO Engine Flywheel00b = Drive not engaged01b = Drive engaged10b = Error11b = Not available";
CM_ SG_ 2566759678 EnlSwthPTOEngnAssrDrv1 "Enable Switch - PTO Engine Accessory Drive 1: Status of the PTO engine accessory drive 1 enable switch00b = Enable switch off – PTO operation not desired01b = Enable switch on – PTO operation desired10b = Error11b = Not available";
CM_ SG_ 2566759678 EnlSwthPTOEngnAssrDrv2 "Enable Switch - PTO Engine Accessory Drive 2: Status of the PTO engine accessory drive 2 enable switch00b = Enable switch off – PTO operation not desired01b = Enable switch on – PTO operation desired10b = Error11b = Not available";
CM_ SG_ 2566759678 EnlSwthTrnsfrstptshftPTO "Enable Switch – Transfer case output shaft PTO: Status of the operator's switch or other input which indicates the desire for engaging the PTO drive mounted on the output shaft of the transfer case. 00b = Enable switch off – PTO operation not desired...";
CM_ SG_ 2566759678 EnlSwthTrnsmssntptshftPTO "Enable Switch – Transmission output shaft PTO: Status of the operator's switch or other input which indicates the desire for engaging the PTO drive mounted on the transmission output shaft. 00b = Enable switch off – PTO operation not desired01b = Ena...";
CM_ SG_ 2566759678 EnlSwthTrnsmssnnptshftPTO2 "Enable Switch – Transmission input shaft PTO 2: Status of the operator's switch or other input which indicates the desire for engaging the second PTO drive mounted on the transmission case.   If there is only one PTO drive on the transmission case, u...";
CM_ SG_ 2566759678 EnlSwthTrnsmssnnptshftPTO1 "Enable Switch – Transmission input shaft PTO 1: Status of the operator's switch or other input which indicates the desire for engaging the first PTO drive mounted on the transmission case.  There may be more than one PTO drive mounted on the transmis...";
CM_ SG_ 2566759678 EnggmntCnsntTrnsfrstptshftPTO "Engagement Consent – Transfer case output shaft PTO: Status of the transmission controller's consent to engage the PTO drive connected to the transfer case output shaft.  The controller in charge of the PTO drive should monitor this parameter and onl...";
CM_ SG_ 2566759678 EnggmntCnsntTrnsmssntptshftPTO "Engagement Consent – Transmission output shaft PTO: Status of the transmission controller's consent to engage the PTO drive connected to the transmission output shaft.  The controller in charge of the PTO drive should monitor this parameter and only ...";
CM_ SG_ 2566759678 EnggmntCnsntTrnsmssnnptshftPTO2 "Engagement Consent – Transmission input shaft PTO 2: Status of the transmission controller's consent to engage the second PTO drive mounted on the transmission case.  The controller in charge of the PTO drive should monitor this parameter and only en...";
CM_ SG_ 2566759678 EnggmntCnsntTrnsmssnnptshftPTO1 "Engagement Consent – Transmission input shaft PTO 1: Status of the transmission controller's consent to engage the first or sole PTO drive mounted on the transmission case.  The controller in charge of the PTO drive should monitor this parameter and ...";
CM_ SG_ 2566759678 EnggmntSttsTrnsfrstptshftPTO "Engagement Status – Transfer case output shaft PTO: Reports if this specific PTO drive is engaged.  This parameter should be broadcast only by the controller(s) receiving feedback about the specific drive.  For example, a pressure switch may be used ...";
CM_ SG_ 2566759678 EnggmntSttsTrnsmssntptshftPTO "Engagement Status – Transmission output shaft PTO: Reports if this specific PTO drive is engaged.  This parameter should be broadcast only by the controller(s) receiving feedback about the specific drive.  For example, a pressure switch may be used t...";
CM_ SG_ 2566759678 EnggmntSttsTrnsmssnnptshftPTO2 "Engagement Status – Transmission input shaft PTO 2: Reports if this specific PTO drive is engaged.  This parameter should be broadcast only by the controller(s) receiving feedback about the specific drive.  For example, a pressure switch may be used ...";
CM_ SG_ 2566759678 EnggmntSttsTrnsmssnnptshftPTO1 "Engagement Status – Transmission input shaft PTO 1: Reports if this specific PTO drive is engaged.  This parameter should be broadcast only by the controller(s) receiving feedback about the specific drive.  For example, a pressure switch may be used ...";
CM_ SG_ 2566759678 PTOMessageCounter "PTO Message Counter: The message counter is used to detect situations where the transmitting ECU malfunction repeats the same frame all the time.  The receiver of the information may use the counter parameter to detect this situation.  The transmitti...";
CM_ SG_ 2566759678 PTOMessageChecksum "PTO Message Checksum: The message checksum is used to verify the signal path from the transmitting device to the receiving device. The message checksum is calculated using the first 7 data bytes, the message counter and the bytes of the message ident...";
CM_ BO_ 2566759934 "Door Control 2";
CM_ SG_ 2566759934 EnableStatusofDoor1 "Enable Status of Door 1: Enable status of bus door 1.  Enabled means the bus doors are able to be automatically opened or closed.00b = door disabled01b = door enabled10b = error11b = not available";
CM_ SG_ 2566759934 EnableStatusofDoor10 "Enable Status of Door 10: Enable status of bus door 10.  Enabled means the bus doors are able to be automatically opened or closed.00b = door disabled01b = door enabled10b = error11b = not available";
CM_ SG_ 2566759934 EnableStatusofDoor2 "Enable Status of Door 2: Enable status of bus door 2.  Enabled means the bus doors are able to be automatically opened or closed.00b = door disabled01b = door enabled10b = error11b = not available";
CM_ SG_ 2566759934 EnableStatusofDoor3 "Enable Status of Door 3: Enable status of bus door 3.  Enabled means the bus doors are able to be automatically opened or closed.00b = door disabled01b = door enabled10b = error11b = not available";
CM_ SG_ 2566759934 EnableStatusofDoor4 "Enable Status of Door 4: Enable status of bus door 4.  Enabled means the bus doors are able to be automatically opened or closed.00b = door disabled01b = door enabled10b = error11b = not available";
CM_ SG_ 2566759934 EnableStatusofDoor5 "Enable Status of Door 5: Enable status of bus door 5.  Enabled means the bus doors are able to be automatically opened or closed.00b = door disabled01b = door enabled10b = error11b = not available";
CM_ SG_ 2566759934 EnableStatusofDoor6 "Enable Status of Door 6: Enable status of bus door 6.  Enabled means the bus doors are able to be automatically opened or closed.00b = door disabled01b = door enabled10b = error11b = not available";
CM_ SG_ 2566759934 EnableStatusofDoor7 "Enable Status of Door 7: Enable status of bus door 7.  Enabled means the bus doors are able to be automatically opened or closed.00b = door disabled01b = door enabled10b = error11b = not available";
CM_ SG_ 2566759934 EnableStatusofDoor8 "Enable Status of Door 8: Enable status of bus door 8.  Enabled means the bus doors are able to be automatically opened or closed.00b = door disabled01b = door enabled10b = error11b = not available";
CM_ SG_ 2566759934 EnableStatusofDoor9 "Enable Status of Door 9: Enable status of bus door 9.  Enabled means the bus doors are able to be automatically opened or closed.00b = door disabled01b = door enabled10b = error11b = not available";
CM_ SG_ 2566759934 LockStatusofDoor1 "Lock Status of Door 1: Lock status of bus door 100b = unlocked 01b = locked10b = error11b = not available";
CM_ SG_ 2566759934 LockStatusofDoor10 "Lock Status of Door 10: Lock status of bus door 1000b = unlocked 01b = locked10b = error11b = not available";
CM_ SG_ 2566759934 LockStatusofDoor2 "Lock Status of Door 2: Lock status of bus door 200b = unlocked 01b = locked10b = error11b = not available";
CM_ SG_ 2566759934 LockStatusofDoor3 "Lock Status of Door 3: Lock status of bus door 300b = unlocked 01b = locked10b = error11b = not available";
CM_ SG_ 2566759934 LockStatusofDoor4 "Lock Status of Door 4: Lock status of bus door 400b = unlocked 01b = locked10b = error11b = not available";
CM_ SG_ 2566759934 LockStatusofDoor5 "Lock Status of Door 5: Lock status of bus door 500b = unlocked 01b = locked10b = error11b = not available";
CM_ SG_ 2566759934 LockStatusofDoor6 "Lock Status of Door 6: Lock status of bus door 600b = unlocked 01b = locked10b = error11b = not available";
CM_ SG_ 2566759934 LockStatusofDoor7 "Lock Status of Door 7: Lock status of bus door 700b = unlocked 01b = locked10b = error11b = not available";
CM_ SG_ 2566759934 LockStatusofDoor8 "Lock Status of Door 8: Lock status of bus door 800b = unlocked 01b = locked10b = error11b = not available";
CM_ SG_ 2566759934 LockStatusofDoor9 "Lock Status of Door 9: Lock status of bus door 900b = unlocked 01b = locked10b = error11b = not available";
CM_ SG_ 2566759934 OpenStatusofDoor1 "Open Status of Door 1: Open status of bus door 100b = door closed01b = door opened10b = error11b = not available";
CM_ SG_ 2566759934 OpenStatusofDoor10 "Open Status of Door 10: Open status of bus door 1000b = door closed01b = door opened10b = error11b = not available";
CM_ SG_ 2566759934 OpenStatusofDoor2 "Open Status of Door 2: Open status of bus door 200b = door closed01b = door opened10b = error11b = not available";
CM_ SG_ 2566759934 OpenStatusofDoor3 "Open Status of Door 3: Open status of bus door 300b = door closed01b = door opened10b = error11b = not available";
CM_ SG_ 2566759934 OpenStatusofDoor4 "Open Status of Door 4: Open status of bus door 400b = door closed01b = door opened10b = error11b = not available";
CM_ SG_ 2566759934 OpenStatusofDoor5 "Open Status of Door 5: Open status of bus door 500b = door closed01b = door opened10b = error11b = not available";
CM_ SG_ 2566759934 OpenStatusofDoor6 "Open Status of Door 6: Open status of bus door 600b = door closed01b = door opened10b = error11b = not available";
CM_ SG_ 2566759934 OpenStatusofDoor7 "Open Status of Door 7: Open status of bus door 700b = door closed01b = door opened10b = error11b = not available";
CM_ SG_ 2566759934 OpenStatusofDoor8 "Open Status of Door 8: Open status of bus door 800b = door closed01b = door opened10b = error11b = not available";
CM_ SG_ 2566759934 OpenStatusofDoor9 "Open Status of Door 9: Open status of bus door 900b = door closed01b = door opened10b = error11b = not available";
CM_ BO_ 2566760702 "Wireless Communications Message 2";
CM_ SG_ 2566760702 NetworkAntennaStatus2 "Network Antenna Status 2: Indicates the status of the antenna for the wireless communications network type0 = Off1 = On2 to 250 = Reserved for Future Assignment251 to 253 = Reserved254 = Error255 = Not Available";
CM_ SG_ 2566760702 NetworkServiceStatus2 "Network Service Status 2: Indicates the status of the Service for the wireless communications network type0 = Local Service1 = Roaming Service2 = Service not available3 = Not Authorized to Operate on Service4 to 250 = Reserved for Future Assignment25...";
CM_ SG_ 2566760702 NetworkSignalStrength2 "Network Signal Strength 2: Indicates the signal strength for the wireless communications network type.";
CM_ SG_ 2566760702 NetworkTransceiverStatus2 "Network Transceiver Status 2: Indicates the status of the transceiver for the wireless communications network type0 = Off1 = On2 = Not Authorized to Operate on Network3 to 250 = Reserved for Future Assignment251 to 253 = Reserved254 = Error255 = Not ...";
CM_ SG_ 2566760702 WrlssCmmntnNtwrkTp2 "Wireless Communication Network Type 2: Type of Wireless Communication Network0 = Cellular network #11 = Cellular network #22 = Wireless LAN #13 = Wireless LAN #24 = Satellite network5 to 250 = Reserved for Future Assignment251 to 253 = Reserved254 = ...";
CM_ BO_ 2566760958 "Wireless Communications Message 1";
CM_ SG_ 2566760958 NetworkAntennaStatus1 "Network Antenna Status 1: Indicates the status of the antenna for the wireless communications network type0 = Off1 = On2 to 250 = Reserved for Future Assignment251 to 253 = Reserved254 = Error255 = Not Available";
CM_ SG_ 2566760958 NetworkServiceStatus1 "Network Service Status 1: Indicates the status of the Service for the wireless communications network type0 = Local Service1 = Roaming Service2 = Service not available3 = Not Authorized to Operate on Service4 to 250 = Reserved for Future Assignment25...";
CM_ SG_ 2566760958 NetworkSignalStrength1 "Network Signal Strength 1: Indicates the signal strength for the wireless communications network type.";
CM_ SG_ 2566760958 NetworkTransceiverStatus1 "Network Transceiver Status 1: Indicates the status of the transceiver for the wireless communications network type0 = Off1 = On2 = Not Authorized to Operate on Network3 to 250 = Reserved for Future Assignment251 to 253 = Reserved254 = Error255 = Not ...";
CM_ SG_ 2566760958 WrlssCmmntnNtwrkTp1 "Wireless Communication Network Type 1: Type of Wireless Communication Network0 = Cellular network #11 = Cellular network #22 = Wireless LAN #13 = Wireless LAN #24 = Satellite network5 to 250 = Reserved for Future Assignment251 to 253 = Reserved254 = ...";
CM_ BO_ 2566761214 "Engine Fluid Level/Pressure 4";
CM_ SG_ 2566761214 EngineAftercoolerCoolantLevel "Engine Aftercooler Coolant Level: Ratio of aftercooler coolant system volume of liquid to total cooling system volume.  The engine aftercooler coolant level is for  the low temperature (LT) cooling circuit used for the compressor outlet air or charge...";
CM_ SG_ 2566761214 EngineCentrifugalOilFilterspeed "Engine Centrifugal Oil Filter speed: The speed of a rotating (centrifugal) engine oil filter.";
CM_ SG_ 2566761214 EngnChrgArClr1IntkPrssr "Engine Charge Air Cooler 1 Intake Pressure: Pressure of air at intake to 1st or only charge air cooler, from multiple first stage turbochargers being cooled and feeding multiple second stage turbochargers.";
CM_ SG_ 2566761214 EngnChrgArClr2IntkPrssr "Engine Charge Air Cooler 2 Intake Pressure: Pressure of air at intake to 2nd charge air cooler, from multiple first stage turbochargers being cooled and feeding multiple second stage turbochargers.";
CM_ SG_ 2566761214 EngnChrgArClrClntLvl "Engine Charge Air Cooler Coolant Level: Ratio of volume of liquid found in an engine charge air cooler cooling system to total engine charge air cooler cooling system volume.";
CM_ SG_ 2566761214 EngnChrgArClrOtltPrssr "Engine Charge Air Cooler Outlet Pressure: Measures pressure of air at outlet from charge air cooler";
CM_ SG_ 2566761214 EngnClntPmpDffrntlPrssr "Engine Coolant Pump Differential Pressure: The differential pressure measured across the input and output of the engine coolant pump.";
CM_ BO_ 2566761726 "Engine Fuel Information";
CM_ SG_ 2566761726 EngineIdleFuelFlowRateThreshold "Engine Idle Fuel Flow Rate Threshold: A configuration value that indicates the maximum flow rate for engine idle operation.";
CM_ SG_ 2566761726 NmrfFlCnsmptnMntrngTrnsdrs "Number of Fuel Consumption Monitoring Transducers: The number of fuel consumption monitoring transducers installed in the fuel consumption monitoring system.";
CM_ BO_ 2566762238 "Fifth Wheel Smart Systems 2";
CM_ SG_ 2566762238 FfthWhlLkCplSttsIndtr "Fifth Wheel Lock Couple Status Indicator: Indicates results of coupling operation to the vehicle operator. For incomplete couples further information can be obtained from the fifth wheel error status SP.00b = Incomplete or bad couple, truck should no...";
CM_ SG_ 2566762238 FfthWhlLkRdtCplIndtr "Fifth Wheel Lock Ready to Couple Indicator: Indicates to the vehicle operator that the fifth wheel lock is open and ready to couple.00b = Lock not open, not ready to couple01b = Lock open, ready to couple10b = Error11b = Not Available";
CM_ SG_ 2566762238 FifthWheelErrorStatus "Fifth Wheel Error Status: Fifth wheel error state which conveys information when coupling status is incomplete or bad.0000b = Improper Couple0001b = Locks Closed / No Kingpin at Startup0010b = Kingpin / Locks Open at Startup0011b = Not Used0100b = No...";
CM_ SG_ 2566762238 FifthWheelSliderLockIndicator "Fifth Wheel Slider Lock Indicator: Indicates to vehicle operator that the fifth wheel slider is in position and locked. 00b = Not Locked01b = Locked10b = Error11b = Not Available";
CM_ SG_ 2566762238 FifthWheelSliderPosition "Fifth Wheel Slider Position: Slider position measurement. Zero equals fully back position, that is, the farthest to the rear of the vehicle.";
CM_ BO_ 2566762494 "Aftertreatment 2 Intermediate Gas";
CM_ SG_ 2566762494 Aftrtrtmnt2ExhstTmprtr2 "Aftertreatment 2 Exhaust Temperature 2: The reading from the exhaust temperature sensor located midstream of the other two temperature sensors in the aftertreatment system in exhaust bank 2.  (For a single exhaust bank system, refer to parameters in ...";
CM_ SG_ 2566762494 Atttt2DsPttFtDtPss "Aftertreatment 2 Diesel Particulate Filter Differential Pressure: Exhaust differential pressure measured between the intake and exhaust of a diesel particulate filter in exhaust bank 2.  (For a single exhaust bank system, refer to parameters in PGNs ...";
CM_ SG_ 2566762494 Atttt2DsPttFtDtPssPFMI "Aftertreatment 2 Diesel Particulate Filter Differential Pressure Preliminary FMI: Used to identify the applicable J1939-73 FMI detected in the diesel particulate filter differential pressure sensor by the manufacturer’s sensor control software in exh...";
CM_ SG_ 2566762494 Atttt2DsPttFtItdtTpt "Aftertreatment 2 Diesel Particulate Filter Intermediate Temperature: Temperature of engine combustion byproducts at a mid-point in the diesel particulate filter in exhaust bank 2.  (For a single exhaust bank system, refer to parameters in PGNs 61454,...";
CM_ SG_ 2566762494 Atttt2DsPttFtItdtTptPFMI "Aftertreatment 2 Diesel Particulate Filter Intermediate Temperature Preliminary FMI: Used to identify the applicable J1939-73 FMI detected in the diesel particulate filter intermediate temperature sensor by the manufacturer’s sensor control software ...";
CM_ SG_ 2566762494 Atttt2ExstTpt2PFMI "Aftertreatment 2 Exhaust Temperature 2 Preliminary FMI: Used to identify the applicable J1939-73 FMI detected in the exhaust temperature 2 sensor by the manufacturer’s sensor control software in exhaust bank 2.  In the case of multiple failures the m...";
CM_ BO_ 2566762750 "Aftertreatment 2 Outlet Gas 2";
CM_ SG_ 2566762750 Aftrtrtmnt2ExhstTmprtr3 "Aftertreatment 2 Exhaust Temperature 3: The reading from the exhaust temperature sensor located farthest downstream in the aftertreatment system in exhaust bank 2.  (For a single exhaust bank system, refer to parameters in PGNs 61454, 61455,  64946, ...";
CM_ SG_ 2566762750 Atttt2DsPttFtExstTptPFMI "Aftertreatment 2 Diesel Particulate Filter Exhaust Temperature Preliminary FMI: Used to identify the applicable J1939-73 FMI detected in the diesel particulate filter outlet temperature sensor by the manufacturer’s sensor control software in exhaust ...";
CM_ SG_ 2566762750 Atttt2DsPttFtOttTpt "Aftertreatment 2 Diesel Particulate Filter Outlet Temperature: Temperature of engine combustion byproducts leaving the diesel particulate filter exhaust in exhaust bank 2.  (For a single exhaust bank system, refer to parameters in PGNs 61454, 61455, ...";
CM_ SG_ 2566762750 Atttt2ExstTpt3PFMI "Aftertreatment 2 Exhaust Temperature 3 Preliminary FMI: Used to identify the applicable J1939-73 FMI detected in the exhaust temperature 3 sensor by the manufacturer’s sensor control software in exhaust bank 2.  In the case of multiple failures the m...";
CM_ BO_ 2566763006 "Aftertreatment 2 Intake Gas 2";
CM_ SG_ 2566763006 Aftrtrtmnt2ExhstTmprtr1 "Aftertreatment 2 Exhaust Temperature 1: The reading from the exhaust temperature sensor located farthest upstream in the aftertreatment system in exhaust bank 2.  (For a single exhaust bank system, refer to parameters in PGNs 61454, 61455,  64946, 64...";
CM_ SG_ 2566763006 Atttt2DsPttFtItTpt "Aftertreatment 2 Diesel Particulate Filter Intake Temperature: Temperature of engine combustion byproducts entering the diesel particulate filter in exhaust bank 2.  (For a single exhaust bank system, refer to parameters in PGNs 61454, 61455,  64946,...";
CM_ SG_ 2566763006 Atttt2DsPttFtItTptPFMI "Aftertreatment 2 Diesel Particulate Filter Intake Temperature Preliminary FMI: Used to identify the applicable J1939-73 FMI detected in the diesel particulate filter intake temperature sensor by the manufacturer’s sensor control software in exhaust b...";
CM_ SG_ 2566763006 Atttt2ExstTpt1PFMI "Aftertreatment 2 Exhaust Temperature 1 Preliminary FMI: Used to identify the applicable J1939-73 FMI detected in the exhaust temperature 1 sensor by the manufacturer’s sensor control software in exhaust bank 2.  In the case of multiple failures the m...";
CM_ BO_ 2566763262 "Aftertreatment 1 Intermediate Gas";
CM_ SG_ 2566763262 Aftrtrtmnt1ExhstTmprtr2 "Aftertreatment 1 Exhaust Temperature 2: The reading from the exhaust temperature sensor located midstream of the other two temperature sensors in the aftertreatment system in exhaust bank 1.";
CM_ SG_ 2566763262 Atttt1DsPttFtDtPss "Aftertreatment 1 Diesel Particulate Filter Differential Pressure: Exhaust differential pressure measured between the intake and exhaust of a diesel particulate filter in exhaust bank 1.";
CM_ SG_ 2566763262 Atttt1DsPttFtDtPssPFMI "Aftertreatment 1 Diesel Particulate Filter Differential Pressure Preliminary FMI: Used to identify the applicable J1939-73 FMI detected in the diesel particulate filter differential pressure sensor by the manufacturer’s sensor control software in exh...";
CM_ SG_ 2566763262 Atttt1DsPttFtItdtTpt "Aftertreatment 1 Diesel Particulate Filter Intermediate Temperature: Temperature of engine combustion byproducts at a mid-point in the diesel particulate filter in exhaust bank 1.";
CM_ SG_ 2566763262 Atttt1DsPttFtItdtTptPFMI "Aftertreatment 1 Diesel Particulate Filter Intermediate Temperature Preliminary FMI: Used to identify the applicable J1939-73 FMI detected in the diesel particulate filter intermediate temperature sensor by the manufacturer’s sensor control software ...";
CM_ SG_ 2566763262 Atttt1ExstTpt2PFMI "Aftertreatment 1 Exhaust Temperature 2 Preliminary FMI: Used to identify the applicable J1939-73 FMI detected in the exhaust temperature 2 sensor by the manufacturer’s sensor control software in exhaust bank 1.  In the case of multiple failures the m...";
CM_ BO_ 2566763518 "Aftertreatment 1 Outlet Gas 2";
CM_ SG_ 2566763518 Aftrtrtmnt1ExhstTmprtr3 "Aftertreatment 1 Exhaust Temperature 3: The reading from the exhaust temperature sensor located farthest downstream in the aftertreatment system in exhaust bank 1.";
CM_ SG_ 2566763518 Atttt1DsPttFtOttExstTptPFMI "Aftertreatment 1 Diesel Particulate Filter Outlet Exhaust Temperature Preliminary FMI: Used to identify the applicable J1939-73 FMI detected in the diesel particulate filter outlet temperature sensor by the manufacturer’s sensor control software in e...";
CM_ SG_ 2566763518 Atttt1DsPttFtOttTpt "Aftertreatment 1 Diesel Particulate Filter Outlet Temperature: Temperature of engine combustion byproducts leaving the diesel particulate filter exhaust in exhaust bank 1.";
CM_ SG_ 2566763518 Atttt1ExstTpt3PFMI "Aftertreatment 1 Exhaust Temperature 3 Preliminary FMI: Used to identify the applicable J1939-73 FMI detected in the exhaust temperature 3 sensor by the manufacturer’s sensor control software in exhaust bank 1.  In the case of multiple failures the m...";
CM_ BO_ 2566763774 "Aftertreatment 1 Intake Gas 2";
CM_ SG_ 2566763774 Aftrtrtmnt1ExhstTmprtr1 "Aftertreatment 1 Exhaust Temperature 1: The reading from the exhaust temperature sensor located farthest upstream in the aftertreatment system in exhaust bank 1.";
CM_ SG_ 2566763774 Atttt1DsPttFtItTpt "Aftertreatment 1 Diesel Particulate Filter Intake Temperature: Temperature of engine combustion byproducts entering the diesel particulate filter in exhaust bank 1.";
CM_ SG_ 2566763774 Atttt1DsPttFtItTptPFMI "Aftertreatment 1 Diesel Particulate Filter Intake Temperature Preliminary FMI: Used to identify the applicable J1939-73 FMI detected in the diesel particulate filter intake temperature sensor by the manufacturer’s sensor control software in exhaust b...";
CM_ SG_ 2566763774 Atttt1ExstTpt1PFMI "Aftertreatment 1 Exhaust Temperature 1 Preliminary FMI: Used to identify the applicable J1939-73 FMI detected in the exhaust temperature 1 sensor by the manufacturer’s sensor control software in exhaust bank 1.   In the case of multiple failures the ...";
CM_ BO_ 2566765054 "Tire Pressure Reference Information";
CM_ SG_ 2566765054 ReferenceTirePressure "Reference Tire Pressure: Reference value of the tire pressure as basis for the tire pressure monitoring";
CM_ SG_ 2566765054 TireLocation "Tire Location: Identifies which tire is associated with the parametric data in this PG.The low order 4 bits represent a position number, counting left to right when facing in the direction of normal vehicle travel (forward).The high order 4 bits repr...";
CM_ BO_ 2566765310 "Farebox Status";
CM_ SG_ 2566765310 FareboxAlarmIdentifier "Farebox Alarm Identifier: Indicates the nature of the farebox alarm condition.0000000b = Voltage dropout0000001b = Voltage restored0000010b = Probe started0000011b = Probe completed0000100b = Cashbox removed0000101b = Cashbox restored0000110b = Cashb...";
CM_ SG_ 2566765310 FareboxEmergencyStatus "Farebox Emergency Status: Indicates if a farebox emergency condition exists.00b = Non-emergency condition01b = Emergency condition10b = Error Condition11b = Not available";
CM_ BO_ 2566765566 "Farebox Point of Sale";
CM_ SG_ 2566765566 FareValidity "Fare Validity: Agency defined value indicating validity of this fare";
CM_ SG_ 2566765566 InitialFareAgency "Initial Fare Agency: Identifies where the initial fare is paidNote:  The definition of the agency numbering plan shall be agreed by the operating agency and the farebox manufacturer.  The value of 0 is reserved, the usable range is 1 to 31.";
CM_ SG_ 2566765566 PassCategory "Pass Category: Agency defined value indicating the category of the passenger associated with this fare";
CM_ SG_ 2566765566 PassengerType "Passenger Type: Enumerated value representing the type/class of passenger, as defined by the agency.";
CM_ SG_ 2566765566 PaymentDetails "Payment Details: Payment details.0000b = Not an upgrade0001b = Cash0010b = Token0011b = Ticket0100b = Pass0101b = Card0110b to 1010b = Reserved for assignment1011b to 1111b = Agency defined";
CM_ SG_ 2566765566 RouteNumber "Route Number: The route number issuing the transfer.";
CM_ SG_ 2566765566 TransactionType "Transaction Type: Enumerated value representing the type of transaction completed0000b = Cash0001b = Token0010b = Ticket0011b = Pass0100b = Card0101b = Permit0110b = Transfer0111b = Free1000b to 1011b = Reserved for assignment1100b to 1111b = Agency ...";
CM_ SG_ 2566765566 TransferSold "Transfer Sold: Indicates that a transfer was sold or issued on this transaction including its type and/or restrictions. The final definitions of the transfer issued information shall be agreed by the operating agency and the farebox manufacturer.Note...";
CM_ SG_ 2566765566 TransferType "Transfer Type: The kind of transfer used00000b = North00001b = South00010b = East00011b = West00100b = In00101b = Out00110b to 11111b = Agency defined";
CM_ SG_ 2566765566 TypeofFare "Type of Fare: Type of Fare0000b = Cash/No detail0001b = Token A0010b = Token B0011b = Ticket A0100b = Ticket B0101b = Pass A0110b = Pass B0111b to 1010b = Reserved for assignment1011b to 1111b = Agency defined";
CM_ SG_ 2566765566 TypeofService "Type of Service: The type of service provided000b = Local service001b = Express service010b to 111b = Agency defined";
CM_ BO_ 2566765822 "Farebox Service Detail";
CM_ SG_ 2566765822 AssignedBlock "Assigned Block: The agency defined block number for this trip";
CM_ SG_ 2566765822 AssignedRoute "Assigned Route: The identity number assigned to this route.Note:  This is the numerical value for the route as opposed to the Transit Assigned Route Identity (SPN 3074) which is variable length ASCII or the Route number (SPN 3169) which is 12 bit num...";
CM_ SG_ 2566765822 AssignedRun "Assigned Run: The agency defined run number for this trip";
CM_ SG_ 2566765822 Driversfareboxsecuritycode "Driver's farebox security code: Security code for the farebox, numerical only.Note:  0 = Farebox is in reporting status1 to 65535 = security code";
CM_ SG_ 2566765822 FareboxServiceStatus "Farebox Service Status: Indicates if the farebox is in or out of service.00b = Farebox out of service01b = Farebox in service10b = Error Condition11b = Not available";
CM_ SG_ 2566765822 FarePresets "Fare Presets: Fare Presets00000000b to 00001111b = Agency defined00010000b to 11111111b = Reserved for assignment";
CM_ SG_ 2566765822 PatternNumber "Pattern Number : The agency defined pattern number for this trip";
CM_ SG_ 2566765822 TripDirection "Trip Direction: The general direction of travel for this trip.0000b = North0001b = South0010b = East0011b = West0100b = In0101b = Out0110b to 1111b = Agency defined";
CM_ SG_ 2566765822 TripNumber "Trip Number: The identity number assigned to this trip.";
CM_ SG_ 2566765822 TripStatus "Trip Status: Trip Status000b = Undefined001b = Trip start010b = Trip end011b = Undefined100b = Undefined101b = Layover start110b = Layover end111b = Undefined";
CM_ BO_ 2566766078 "Signal Preemption";
CM_ SG_ 2566766078 IntrstnPrmptnRqstRspns "Intersection Preemption Request/Response: Status of the intersection signal preemption00b = Message is a request directed to the emitter01b = Message is a response from the emitter10b = Error condition11b = Not available";
CM_ SG_ 2566766078 PriorityofResponseSentbyEmitter "Priority of Response Sent by Emitter: Priority of response sent by emitter0000b = Reserved0001b = Low priority0010b = Probe priority0011b = High priority0100b to 1000b = Reserved1001b = Priority set by hardware to low priority1010b = Priority set by ...";
CM_ SG_ 2566766078 RangeCodeEnable "Range Code Enable: Range code enable00b = Range code not used for interleaved data01b = Range code used for interleaved data10b = Error condition11b = Not available";
CM_ SG_ 2566766078 StrobeActivationControlStatus "Strobe Activation Control Status: Strobe activation control status00b = Deactivate strobe01b = Activate strobe10b = Error condition11b = Not availableNote: Strobe will flash if not overridden by transit door status, strobe is working, and emitter is ...";
CM_ SG_ 2566766078 TransitDoorEnable "Transit Door Enable: Transit door enable00b = Ignore transit door status01b = Transit door status will override strobe activation10b = Error condition11b = Not available";
CM_ SG_ 2566766078 TransitRouteIDUsage "Transit Route ID Usage: Transit route ID usage00b = Transit route ID not used for interleaved data01b = Transit route ID used for interleaved data (if range code not enabled)10b = Error condition11b = Not available";
CM_ SG_ 2566766078 VehicleID "Vehicle ID: Numerical designation of the vehicle.   65535 is used to represent the vehicle ID is not available.";
CM_ BO_ 2566766334 "Transit Route";
CM_ SG_ 2566766334 Agency "Agency: The identity of the agency involved in this transaction";
CM_ SG_ 2566766334 NmrftsnthTrnstAssgndBlkIdntt "Number of bytes in the Transit Assigned Block Identity: Number of bytes in the Transit Assigned Block Identity.  This parameter identifies the length, in bytes, of the data in SPN 3076 (Transit Assigned Block Identity).";
CM_ SG_ 2566766334 NmrftsnthTrnstAssgndRnIdntt "Number of bytes in the Transit Assigned Run Identity: Number of bytes in the Transit Assigned Run Identity.  This parameter identifies the length, in bytes, of the data in SPN 3075 (Transit Assigned Run Identity).";
CM_ SG_ 2566766334 NmrftsnthTrnstAssgndRtIdntt "Number of bytes in the Transit Assigned Route Identity: Number of bytes in the Transit Assigned Route Identity.  This parameter identifies the length, in bytes, of the data in SPN 3074 (Transit Assigned Route Identity).";
CM_ BO_ 2566766590 "Transit Milepost";
CM_ SG_ 2566766590 NmrftsnthMlpstIdntftn "Number of bytes in the Milepost Identification: Number of bytes in the Milepost Identification.  This parameter identifies the length, in bytes, of the data in SPN 509 (Milepost Identification).";
CM_ BO_ 2566766846 "Passenger Counter";
CM_ SG_ 2566766846 PatronCount "Patron Count: Count of the number of passengers on a transit vehicle.  If the type of passenger count (SPN 3043) is 0, the patron count indicates the number of patrons currently on vehicle after the door has closed.  If the type of passenger count is...";
CM_ SG_ 2566766846 SilentAlarmStatus "Silent Alarm Status: Used to report silent alarm push button status.00b = Off01b = On10b = Error condition11b = Not available";
CM_ SG_ 2566766846 TransitRunStatus "Transit Run Status: Status of the run switch for the vehicle.00b = Off01b = On10b = Error condition11b = Not available";
CM_ SG_ 2566766846 TypeofPassengerCount "Type of Passenger Count: Used to notify transit link devices of the type of passenger counting system used in the vehicle.  Some passenger counting systems indicate real-time boarding and exiting data for other devices to accumulate. Other types of p...";
CM_ SG_ 2566766846 VehicleUseStatus "Vehicle Use Status: Used to indicate the proper or unauthorized use of the vehicle. The administrative control device or any device issuing the vehicle use status PID should be sensitive to the run switch status (SPN 3046) and any other locally defin...";
CM_ BO_ 2566767102 "Engine Fluid Level/Pressure 3";
CM_ SG_ 2566767102 EngnExhstGsRrltn1IntkPrssr "Engine Exhaust Gas Recirculation 1 Intake Pressure: EGR intake gage pressure is measured after the EGR cooler and before the EGR valve.";
CM_ SG_ 2566767102 EngnExhstGsRrltn1OtltPrssr "Engine Exhaust Gas Recirculation 1 Outlet Pressure: EGR outlet pressure is measured immediately after the EGR valve.";
CM_ SG_ 2566767102 EngnExhstVlvAttnSstmOlPrssr "Engine Exhaust Valve Actuation System Oil Pressure: The absolute pressure of the oil in the hydraulic system that powers the engine exhaust valve actuation system";
CM_ SG_ 2566767102 EngnIntkVlvAttnSstmOlPrssr "Engine Intake Valve Actuation System Oil Pressure: The gage pressure of the oil in the hydraulic system that powers the engine intake valve actuation system";
CM_ SG_ 2566767102 EngnThrttlVlv1DffrntlPrssr "Engine Throttle Valve 1 Differential Pressure: The differential pressure between the intake and outlet of the throttle valve 1 (SPN 51).  The differential pressure is measured from the intake with respect to the outlet of the throttle valve.";
CM_ BO_ 2566767358 "Electronic Engine Controller 14";
CM_ SG_ 2566767358 EngineFuelIsolationControl "Engine Fuel Isolation Control: Control setting for fuel isolation. In a single injector dual fuel system when using just diesel fuel, diesel must not be allowed to migrate into the gaseous fuel system. When the fuel isolation valve is closed the engi...";
CM_ SG_ 2566767358 EngineFuelMassFlowRate "Engine Fuel Mass Flow Rate: Mass of liquid fuel consumed by engine per unit of time.";
CM_ SG_ 2566767358 EngnExhstGsRrltn1Vlv1PstnErrr "Engine Exhaust Gas Recirculation 1 Valve 1 Position Error: The position error of the Exhaust Gas Recirculation 1 valve, determined as the actual position (SPN 27) minus the commanded position (SPN 2791).";
CM_ SG_ 2566767358 EngnExhstGsRrltn1Vlv2PstnErrr "Engine Exhaust Gas Recirculation 1 Valve 2 Position Error: The position error of the Exhaust Gas Recirculation 1 valve 2, determined as the actual position (SPN 3821) minus the commanded position (SPN 3822).";
CM_ SG_ 2566767358 FuelType "Fuel Type: Type of fuel currently being utilized by the vehicleData Byte - Scaling - External Display00h = Not available - NONE01h = Gasoline/petrol - GAS02h = Methanol - METH03h = Ethanol - ETH04h = Diesel - DSL05h = Liquefied Petroleum Gas (LPG) - ...";
CM_ BO_ 2566767614 "Electronic Engine Controller 15";
CM_ SG_ 2566767614 AcceleratorPedal1Channel2 "Accelerator Pedal #1 Channel 2: Sensor output 2 for the accelerator pedal #1 position when using a redundant-style sensor.  The ratio of actual accelerator pedal position to maximum pedal position. This is for the first occurrence of the accelerator ...";
CM_ SG_ 2566767614 AcceleratorPedal1Channel3 "Accelerator Pedal #1 Channel 3: Sensor output 3 for the accelerator pedal #1 position when using a redundant-style sensor.  The ratio of actual accelerator pedal position to maximum pedal position. This is for the first occurrence of the accelerator ...";
CM_ SG_ 2566767614 AcceleratorPedal2Channel2 "Accelerator Pedal #2 Channel 2: Sensor output 2 for the accelerator pedal #2 position when using a redundant-style sensor.  The ratio of actual accelerator pedal position to maximum pedal position. This is for the second occurrence of the accelerator...";
CM_ SG_ 2566767614 AcceleratorPedal2Channel3 "Accelerator Pedal #2 Channel 3: Sensor output 3 for the accelerator pedal #2 position when using a redundant-style sensor.  The ratio of actual accelerator pedal position to maximum pedal position. This is for the second occurrence of the accelerator...";
CM_ SG_ 2566767614 EngnExhstGsRstrtnVlvCntrl "Engine Exhaust Gas Restriction Valve Control: Desired percentage of maximum Exhaust Gas Restriction opening for valve. 0% means valve is closed. 100% means maximum valve opening (full gas flow).";
CM_ BO_ 2566767870 "Electronic Brake Controller 5";
CM_ SG_ 2566767870 BrakeTemperatureWarning "Brake Temperature Warning: This parameter indicates if the temperature in the service brakes exceeds a certain value. It can be used for a warning information for the driver. The temperature warning value is vehicle manufacturer specific.00b = Not Ac...";
CM_ SG_ 2566767870 EmergencyBrakingActive "Emergency Braking Active: Signal which indicates an emergency braking situation (ref. ECE Regulation 13 paragraph 5.2.1.31) with high  deceleration values.  This signal can be used to activate the hazard lights (ref ECE Regulation 48 paragraph 6.23) ...";
CM_ SG_ 2566767870 FoundationBrakeUse "Foundation Brake Use: This parameter indicates if the brake system presently uses the foundation brakes.00b = Foundation brakes not in use01b = Foundation brakes in use10b = Reserved11b = Not available";
CM_ SG_ 2566767870 Haltbrakemode "Halt brake mode: Signal which indicates the current mode of the halt brake function.000b = Inactive001b = Active010b = Active, but not functioning properly.  (This mode may be used to warn the driver)011b to 101b = Not defined110b = Halt brake not fu...";
CM_ SG_ 2566767870 Hillholdermode "Hill holder mode: Signal which indicates the current mode of the hill holder function.000b = Inactive001b = Active010b = Active, but will change to inactive in a short time.  (This mode may be used to warn the driver)011b = Active, but may activate p...";
CM_ SG_ 2566767870 PrkngBrkAttrFllAtvtd "Parking Brake Actuator Fully Activated: Signal which indicates when the parking brake actuator is fully activated.  (see also SPN 70 and 619).00b = Parking Brake Actuator not fully activated01b = Parking Brake Actuator fully activated10b = Error11b =...";
CM_ SG_ 2566767870 RailroadMode "Railroad Mode: Signal which indicates the current state of the Railroad Mode / Function.00b = Inactive (Driving mode: Steer Axle on ground)01b = Active (Railroad mode: Steer Axle lifted off ground)10b = Error11b = Not availableNote: This status signa...";
CM_ SG_ 2566767870 XBRAccelerationLimit "XBR Acceleration Limit: The brake system may temporarily or generally limit the maximum brake performance available for external systems. A temporary limit may be nessary due to high brake temperature; a general limit may be defined by the vehicle ma...";
CM_ SG_ 2566767870 XBRActiveControlMode "XBR Active Control Mode: This parameter indicates which XBR Control Mode is executed by the brake system.0000b = No brake demand being executed (default mode)0001b = Driver's brake demand being executed, no external brake demand0010b = Addition mode ...";
CM_ SG_ 2566767870 XBRSystemState "XBR System State: This parameter indicates which external brake control is allowed.00b = Any external brake demand will be accepted (brake system fully operational)01b = Only external brake demand of highest XBR Priority (00b) will be accepted  (e.g....";
CM_ BO_ 2566768126 "ECU Identification Information";
CM_ SG_ 2566768126 ECUHardwareID "ECU Hardware ID: The ECU Hardware ID provides information to identify a specific ECU hardware version.As an example, on a CAN network, this parameter can be used to uniquely identify the hardware version that is relevant for the interface of the ECU ...";
CM_ SG_ 2566768126 ECULocation "ECU Location: The location of the ECU within a network.";
CM_ SG_ 2566768126 ECUManufacturerName "ECU Manufacturer Name: The name of the manufacturer of the physical ECU.This name may be different than the manufacturer identified by the Manufacturer Code (SPN 2838) and listed in table B10 of J1939.";
CM_ SG_ 2566768126 ECUPartNumber "ECU Part Number: The part number of the physical ECU.";
CM_ SG_ 2566768126 ECUSerialNumber "ECU Serial Number: The serial number of the physical ECU.";
CM_ SG_ 2566768126 ECUType "ECU Type: The type of ECU.  One example of a use of the ECU type could be for classifying ECU capabilities, such as I/O.";
CM_ SG_ 2566768126 ECUDateofManufacture "ECU Date of Manufacture: The date of manufacture for the physical ECU. Devices supporting this field are recommended to observe the date formats as described in ISO 8601.";
CM_ BO_ 2566768382 "Cold Start Aids";
CM_ SG_ 2566768382 EngineColdStartFuelIgniterRelay "Engine Cold Start Fuel Igniter Relay: The engine cold start fuel igniter relay control command.  This command controls the relay, not the igniter.00b = Off01b = On10b = Reserved11b = Don't care/take no action";
CM_ SG_ 2566768382 EngineStartEnableDevice1 "Engine Start Enable Device 1: Devices that assist an Engine in starting, e.g. intake heaters and ether.  Primary starting aid.Parameter indicating whether the start enable device 1 is ON or OFF00b = start enable OFF01b = start enable ON10b = reserved...";
CM_ SG_ 2566768382 EngineStartEnableDevice2 "Engine Start Enable Device 2: Devices that assist an engine in starting, e.g. intake heaters, ether, or an alternate/secondary starting aid.  May be of the same type or different than Start Enable Device 1 (SPN 626). Parameter indicating whether the ...";
CM_ SG_ 2566768382 EngnCldStrtFlIgntrCmmnd "Engine Cold Start Fuel Igniter Command: The engine cold start fuel igniter control command, normalized to %, where 0% represents fully off and 100% represents fully on.";
CM_ SG_ 2566768382 EngnCldStrtFlIgntrRlFdk "Engine Cold Start Fuel Igniter Relay Feedback: Feedback state of the engine cold start fuel igniter relay which indicates the status of the relay output.00b = Off01b = On10b = Error11b = Not available";
CM_ SG_ 2566768382 EngnStrtEnlDv1Cnfgrtn "Engine Start Enable Device 1 Configuration: The start enable device installed for start enable device 1.0000b = no start enable device 1 installed0001b = glow plugs installed0010b = fuelled start installed0011b = ether injection installed0100b = elec...";
CM_ SG_ 2566768382 EngnStrtEnlDv2Cnfgrtn "Engine Start Enable Device 2 Configuration: The start enable device installed for start enable device 2.0000b = no start enable device 2 installed0001b = glow plugs installed0010b = fuelled start installed0011b = ether injection installed0100b = elec...";
CM_ BO_ 2566768638 "Off-Highway Engine Control Selection States";
CM_ SG_ 2566768638 EngineAuxiliaryGovernorState "Engine Auxiliary Governor State: This is the Engine Auxiliary Governor feature. This feature is used to allow engine speed to be controlled by an auxiliary input such as pressure or tailshaft speed. This feature is requested by an operator switch, th...";
CM_ SG_ 2566768638 EngineMultiUnitSyncState "Engine Multi-Unit Sync State: This feature is widely used in Industry to operate multiple engines from a single command source. A master engine will synchronize one or more slave engines to operate at the same speed. This feature is requested by an o...";
CM_ SG_ 2566768638 EngineOperatingModeSelection "Engine Operating Mode Selection: Identifies the current engine operating mode. In some off-highway applications it may be desirable to have multiple preconfigured operating modes available for selection by the operator. Examples would be an economy m...";
CM_ SG_ 2566768638 EngineTorqueCurveSelection "Engine Torque Curve Selection: This parameter will report the selected torque curve, as indicated by SPN 6796.0 = Indicates that the engine is using a torque that is not presently selected by SPN 67961 = Indicates that Torque Curve 1 is selected2 = I...";
CM_ SG_ 2566768638 EngnAltrntDrpAlrtr2SltStt "Engine Alternate Droop Accelerator 2 Select State: In some off-highway applications it may be desirable to have multiple droop settings available across the range of engine operation.  For example, in an agricultural tractor application, this functio...";
CM_ SG_ 2566768638 EngnAltrntLwIdlSltStt "Engine Alternate Low Idle Select State: In many applications, it is desirable that an alternate low idle speed setting be made available via switch input. The normal programmed low idle is the default low idle, and when the Alternate Low Idle feature...";
CM_ SG_ 2566768638 EngnAltrntRtngSltStt "Engine Alternate Rating Select State: This parameter reflects the control state that has been achieved based on the input from the SPN 2882.  In some off-highway applications it may be desirable to have multiple engine ratings available for selection...";
CM_ SG_ 2566768638 EngnDrpAlrtr1SltStt "Engine Droop Accelerator 1 Select State: In some off-highway applications it may be desirable to have multiple droop settings available across the range of engine operation.  For example, in an agricultural tractor application, this functionality all...";
CM_ SG_ 2566768638 EngnDrpAxlrInptSltStt "Engine Droop Auxiliary Input Select State: In some off-highway applications it may be desirable to have multiple droop settings available across the range of engine operation.  For example, in an agricultural tractor application, this functionality a...";
CM_ SG_ 2566768638 EngnDrpRmtAlrtrSltStt "Engine Droop Remote Accelerator Select State: In some off-highway applications it may be desirable to have multiple droop settings available across the range of engine operation.  For example, in an agricultural tractor application, this functionalit...";
CM_ BO_ 2566768894 "Operator Primary Intermediate Speed Control state";
CM_ SG_ 2566768894 EngnOprtrPrmrIntrmdtSpdSltStt "Engine Operator Primary Intermediate Speed Select State: 13 preprogrammed intermediate speed control settings are available for the controlling ECM to select.  If no speed setting is requested, the engine operates normally. The Intermediate Speed Con...";
CM_ BO_ 2566769406 "Intermediate Speed Control";
CM_ SG_ 2566769406 EngnOprtrPrmrIntrmdtSpdSlt "Engine Operator Primary Intermediate Speed Select: Allows the operator to select one of 13 preprogrammed Intermediate Speed Control settings. If no speed setting is requested, the engine operates normally. The Intermediate Speed Control is widely use...";
CM_ BO_ 2566769662 "Off-Highway Engine Control Selection";
CM_ SG_ 2566769662 EngineAlternateLowIdleSwitch "Engine Alternate Low Idle Switch: Operator switch which selects between two low idle speeds, default and alternate.The normal programmed low idle is the default low idle, and when the Alternate Low Idle switch is activated, a alternate preprogrammed ...";
CM_ SG_ 2566769662 EngineAlternateRatingSelect "Engine Alternate Rating Select: In some off-highway applications it may be desirable to have multiple engine ratings available for selection by the operator. There is the default engine rating, which provides the maximum available power across the ra...";
CM_ SG_ 2566769662 EngineAuxiliaryGovernorSwitch "Engine Auxiliary Governor Switch: This is the On/Off operation of the Auxiliary Governor feature switch. This feature is used to allow engine speed to be controlled by an auxiliary input such as pressure or tailshaft speed. This switch position indic...";
CM_ SG_ 2566769662 EngineDroopAccelerator1Select "Engine Droop Accelerator 1 Select: In some off-highway applications it may be desirable to have multiple droop settings available across the range of engine operation.  For example, in an agricultural tractor application, this functionality allows a ...";
CM_ SG_ 2566769662 EngineDroopAccelerator2Select "Engine Droop Accelerator 2 Select: In some off-highway applications it may be desirable to have multiple droop settings available across the range of engine operation.  For example, in an agricultural tractor application, this functionality allows a ...";
CM_ SG_ 2566769662 EngineDroopAuxiliaryInputSelect "Engine Droop Auxiliary Input Select: In some off-highway applications it may be desirable to have multiple droop settings available across the range of engine operation.  For example, in an agricultural tractor application, this functionality allows ...";
CM_ SG_ 2566769662 EngineOperatingModeCommand "Engine Operating Mode Command: Command signal identifying the desired preconfigured engine operating mode. In some off-highway applications it may be desirable to have multiple preconfigured operating modes available for selection by the operator. Ex...";
CM_ SG_ 2566769662 EngineSynchronizationSwitch "Engine Synchronization Switch: This is the On/Off operation of the Multiple Unit Synchronization functionality. When it is enabled (i.e. On) the master engine will synchronize one or more slave engines to operate at the same speed. This switch positi...";
CM_ SG_ 2566769662 EngnDrpRmtAlrtrSlt "Engine Droop Remote Accelerator Select: In some off-highway applications it may be desirable to have multiple droop settings available across the range of engine operation.  For example, in an agricultural tractor application, this functionality allo...";
CM_ SG_ 2566769662 EngnTrqCrvSltnCmmnd "Engine Torque Curve Selection Command: This parameter will allow selection of a torque curve that is higher than the base curve.0 = Indicates that this parameter is not presently requesting a different torque curve be used1 = Indicates that Torque Cu...";
CM_ BO_ 2566770174 "Operator Wiper and Washer Controls Message";
CM_ SG_ 2566770174 FrntNnprtrWprDlCntrl "Front Non-operator Wiper Delay Control: Time between cycles of the front non-operator side wiper (i.e. from end of cycle 'n' to start of cycle 'n+1') as selected by the operator control (switch, etc.) in percentage of position with maximum position c...";
CM_ SG_ 2566770174 FrontNonoperatorWasherSwitch "Front Non-operator Washer Switch: State of operation selected by operator switch for the front washer not in front of the operator position.  The parameter, 'Front Operator Washer Switch' should be used for the control information if this parameter  ...";
CM_ SG_ 2566770174 FrontNonoperatorWiperSwitch "Front Non-operator Wiper Switch: State of operation selected by operator switch for the front wiper not in front of the operator position.  The parameter, 'Front Operator Washer Switch' should be used for the control information if this parameter is ...";
CM_ SG_ 2566770174 FrontOperatorWasherSwitch "Front Operator Washer Switch: State of operation selected by operator switch for the washer in front of the operator position. This parameter, 'Front Operator Washer Switch' should be used for the control information if either of the other washer swi...";
CM_ SG_ 2566770174 FrontOperatorWiperDelayControl "Front Operator Wiper Delay Control: Time between cycles of the front operator side wiper (i.e. from end of cycle 'n' to start of cycle 'n+1') as selected by the operator control (switch, etc.) in percentage of position with maximum position correspon...";
CM_ SG_ 2566770174 FrontOperatorWiperSwitch "Front Operator Wiper Switch: State of operation selected by operator switch for the Wiper in front of the operator position. This parameter, 'Front Operator Wiper Switch' should be used for the control information if either of the other wiper switch ...";
CM_ SG_ 2566770174 RearWasherFunction "Rear Washer Function: State of operation selected by operator switch for the rear washer.   The parameter, 'Front Operator Washer Switch' should be used for the control information if this parameter is 'Not Available' and the associated washer still ...";
CM_ SG_ 2566770174 RearWiperDelayControl "Rear Wiper Delay Control: Time between cycles of the rear wiper (i.e. from end of cycle 'n' to start of cycle 'n+1') as selected by the operator control (switch, etc.) in percentage of position with maximum position corresponding to maximum delay sel...";
CM_ SG_ 2566770174 RearWiperSwitch "Rear Wiper Switch: State of operation selected by operator switch for the rear wiper.  The parameter, 'Front Operator Washer Switch' should be used for the control information if this parameter is 'Not Available' and the associated washer still needs...";
CM_ BO_ 2566770942 "Intake/Exhaust Conditions 2";
CM_ SG_ 2566770942 EngineIntakeManifold2Pressure "Engine Intake Manifold #2 Pressure: The gage pressure measurement of the air intake manifold for bank #2 or the second air intake manifold. If there are multiple air pressure sensors in the second intake stream, this is the last one in flow direction...";
CM_ SG_ 2566770942 EngnArFltr2DffrntlPrssr "Engine Air Filter 2 Differential Pressure: Change in engine air system pressure, measured across the second air filter, due to the filter and any accumulation of solid foreign matter on or in the filter.This is for monitoring the air filter on the in...";
CM_ SG_ 2566770942 EngnArFltr3DffrntlPrssr "Engine Air Filter 3 Differential Pressure: Change in engine air system pressure, measured across the third air filter, due to the filter and any accumulation of solid foreign matter on or in the filter.This is for monitoring the air filter on the int...";
CM_ SG_ 2566770942 EngnArFltr4DffrntlPrssr "Engine Air Filter 4 Differential Pressure: Change in engine air system pressure, measured across the fourth air filter, due to the filter and any accumulation of solid foreign matter on or in the filter.This is for monitoring the air filter on the in...";
CM_ SG_ 2566770942 EngnIntkMnfld1AsltPrssr "Engine Intake Manifold #1 Absolute Pressure: The absolute pressure measurement of the air intake manifold. If there are multiple air pressure sensors in the intake stream, this is the last one in flow direction before entering the combustion chamber....";
CM_ SG_ 2566770942 EngnIntkMnfld1AsltPrssrHghRsltn "Engine Intake Manifold 1 Absolute Pressure (High Resolution): The absolute pressure measurement of the air intake manifold. If there are multiple air pressure sensors in the intake stream, this is the last one in flow direction before entering the co...";
CM_ SG_ 2566770942 EngnIntkMnfld2AsltPrssr "Engine Intake Manifold 2 Absolute Pressure: The absolute pressure measurement of the air intake manifold for bank 2 or the second air intake manifold. If there are multiple air pressure sensors in the intake stream, this is the last one in flow direc...";
CM_ BO_ 2566771454 "ECU Performance";
CM_ SG_ 2566771454 DataMemoryUsage "Data Memory Usage: The used storage capacity of the data buffer memory internal to an ECU, such as a data logger.";
CM_ SG_ 2566771454 KeepAliveBatteryConsumption "Keep-Alive Battery Consumption: The capacity consumed from the direct battery connection since the key was last turned off.  This value is maintained and does not accumulate while the key switch is on.  The value is reset to 0 when the key switch is ...";
CM_ BO_ 2566771710 "Turbocharger Information 6";
CM_ SG_ 2566771710 EngnTrhrgr1CmprssrOtltTmprtr "Engine Turbocharger 1 Compressor Outlet Temperature: Temperature of the air or air/fuel mixture exiting the turbocharger 1 compressor outlet";
CM_ SG_ 2566771710 EngnTrhrgr2CmprssrOtltTmprtr "Engine Turbocharger 2 Compressor Outlet Temperature: Temperature of the air or air/fuel mixture exiting the turbocharger 2 compressor outlet.";
CM_ SG_ 2566771710 EngnTrhrgr3CmprssrOtltTmprtr "Engine Turbocharger 3 Compressor Outlet Temperature: Temperature of the air or air/fuel mixture exiting the turbocharger 3 compressor outlet.";
CM_ SG_ 2566771710 EngnTrhrgr4CmprssrOtltTmprtr "Engine Turbocharger 4 Compressor Outlet Temperature: Temperature of the air or air/fuel mixture exiting the turbocharger 4 compressor outlet.";
CM_ BO_ 2566771966 "Cab Message 3";
CM_ SG_ 2566771966 FfthWhlRlsCntrlSrtLkt "Fifth Wheel Release Control Security Lockout: Operator's fifth wheel release control interlock. This operator input must be enabled prior to activating the fifth wheel release control (SPN 3314). 00b = Fifth wheel release Disabled01b = Fifth wheel re...";
CM_ SG_ 2566771966 FifthWheelReleaseControl "Fifth Wheel Release Control: Operator input used to release the fifth wheel. Fifth Wheel Release Control Security Lockout and other conditions must be properly enabled before this will function.00b = Coupler Locked01b = Coupler Unlocked, trailer can ...";
CM_ SG_ 2566771966 TransferCaseSelectorSwitch "Transfer Case Selector Switch: Operator switch to select the condition of the transfer case.  States 000b and 001b should be used if the transfer case only functions to switch between 2-wheel and 4-wheel drive.  If the transfer case includes a High /...";
CM_ SG_ 2566771966 TransmissionOilLevelRequest "Transmission Oil Level Request: Conveys operator or vehicle system desire for a transmission oil level reading to be taken. 00b = No transmission oil level reading desired01b = Transmission oil level reading desired10b = Reserved11b = Don't care / ta...";
CM_ SG_ 2566771966 VehicleTrailerStatus "Vehicle Trailer Status: Indicates a trailer is connected to the towing mechanism.  This is not intended to indicate that the trailer is latched.00b = Trailer is not detected01b = Trailer is detected10b = Error11b = Not available";
CM_ SG_ 2566771966 AftrtrtmntSCRDsngMdCmmnd "Aftertreatment SCR Dosing Mode Command: Request the aftertreatment system to run in standard or reduced mode. Standard indicates that the system will dose at higher capacity where the reduced mode will dose at a lower capacity.  (e.g., IMO 3 to IMO 2...";
CM_ SG_ 2566771966 MomentaryOperatorKeySwitch "Momentary Operator Key Switch: Momentary switch (possibly a push button switch) that indicates the operator's desire to enter accessory mode, enter run mode, enter crank mode, activate the propulsion system, or initiate another behavior as determined...";
CM_ SG_ 2566771966 OperatorKeyDetected "Operator Key Detected: Indicates that a key is physically inserted in the key switch, or for keyless systems, that a valid key is within activation range.00b = No key detected01b = Key is detected10b = Error11b = Not Available";
CM_ SG_ 2566771966 OperatorKeySwitchAccessoryPower "Operator Key Switch Accessory Power: Indicates that the accessory state of the operator key switch is active.This parameter represents the capability of a rotary key switch position, a keyless switch state, or a state determined by the Momentary Oper...";
CM_ SG_ 2566771966 OperatorKeySwitchIgnitionPower "Operator Key Switch Ignition Power: Indicates that the ignition (or run) state of the operator key switch is active. This state is also known in DIN 75552 as KL15. Devices should use SPN 158 to report voltage at their switched battery input.This para...";
CM_ SG_ 2566771966 OperatorKeySwitchStart "Operator Key Switch Start: Indicates that the start state of the operator key switch is active. This state is also known in DIN 75552 as KL50.This parameter represents the capability of a rotary key switch position, a keyless switch state, or a state...";
CM_ SG_ 2566771966 OprtrKSwthDldBttrOff "Operator Key Switch Delayed Battery Off: Indicates a state in which the main battery switch will be opened after a short delay. This allows the battery to be disconnected (as may be required by ADR regulations) while avoiding memory corruption due to...";
CM_ SG_ 2566771966 HornSwitch "Horn Switch: Activates the vehicle (city) horn00b = Horn switch is off01b = Horn switch is on10b = Error11b = Not Available";
CM_ SG_ 2566771966 EngineAirShutoffTestSwitch "Engine Air Shutoff Test Switch: This switch, commonly a momentary switch, when activated will enable the test mode for the engine air shutoff valve. When all applicable criteria are true, the air shutoff valve will activate and shut down the engine.0...";
CM_ SG_ 2566771966 EngineAirShutoffManualSwitch "Engine Air Shutoff Manual Switch: This switch will be used by the operator to activate the engine air shutoff valve, which will cause the engine to shut down.00b = Off01b = On10b = Error11b = Not available";
CM_ BO_ 2566772222 "Electronic Engine Controller 5";
CM_ SG_ 2566772222 EngineFuelControlMode "Engine Fuel Control Mode: Indicates whether the Engine Fuel Control System is in open loop or closed loop.00b = Open loop01b = Closed loop10b = SAE reserved11b = Not available";
CM_ SG_ 2566772222 EngnExhstGsRrltn1Vlv1Cntrl1 "Engine Exhaust Gas Recirculation 1 Valve 1 Control 1: Desired percentage of maximum Exhaust Gas Recirculation (EGR) valve 1 opening.  0% means valve is closed. 100% means maximum valve opening (full gas flow).";
CM_ SG_ 2566772222 EngnTrhrgr1ClltdTrnIntkTmprtr "Engine Turbocharger 1 Calculated Turbine Intake Temperature: Calculated value of turbine intake temperature based on engine operating conditions, such as intake manifold temperature, charge fuel ratio, injection timing, and engine speed.  Use SPN 118...";
CM_ SG_ 2566772222 EngnTrhrgr1ClltdTrnOtltTmprtr "Engine Turbocharger 1 Calculated Turbine Outlet Temperature: Calculated value of turbocharger compressor outlet air temperature.  Temperature of air exiting the turbocharger compressor and before entering charge air cooler.  The estimate is based on ...";
CM_ SG_ 2566772222 EngnVrlGmtrTrhrgr1CntrlMd "Engine Variable Geometry Turbocharger 1 Control Mode: Indicates if the variable geometry turbocharger control status is either open loop or closed loop.00b = open loop01b = closed loop10b = SAE reserved11b = not available";
CM_ SG_ 2566772222 EngnVrlGmtrTrhrgrVGT1AttrPstn "Engine Variable Geometry Turbocharger (VGT) 1 Actuator Position: Sensor that measures the position of the variable geometry turbocharger actuator.  A  position of 0% indicates the actuator is in the position creating the smallest geometry turbocharge...";
CM_ SG_ 2566772222 EVGtTVGTACtStVv "Engine Variable Geometry Turbocharger (VGT) Air Control Shutoff Valve: Isolates vehicle brake air from the Variable Geometry Turbocharger (VGT) system when engine is not running.  This valve prevents vehicle air from bleeding off through the VGT Cont...";
CM_ BO_ 2566774014 "Marine Control Information";
CM_ SG_ 2566774014 EngineMarineOperatingModeStatus "Engine Marine Operating Mode Status: The operating mode of the engine for marine functions.000b = Maintenance Mode001b = Electrical Power Generation (EPG) mode010b = Propulsion Constant Speed Mode011b = Propulsion Variable Speed Mode100b = Propulsion...";
CM_ SG_ 2566774014 EngnThrttlSnhrnztnMdStts "Engine Throttle Synchronization Mode Status: The status of the Throttle Synchronization Mode. Throttle Synchronization Mode is used to indicate which throttle, if any, is currently being used for the synchronized throttle.  0000b = Not Synchronized00...";
CM_ SG_ 2566774014 SlowVesselModeStatus "Slow Vessel Mode Status: The status of the Slow Vessel Mode.  Slow Vessel Mode puts the engine in a lower-than-normal low idle speed during docking or other slow vessel operations.00b = Slow vessel mode is OFF.01b = Slow vessel mode is ACTIVE.10b = R...";
CM_ SG_ 2566774014 TrollingModeStatus "Trolling Mode Status: The status of the Trolling Mode.  Trolling mode limits the top speed.  Full range travel of the throttle level spans from low idle engine speed to maximum trolling speed.See Trolling Mode (Extended Range) - SPN 9657 for alternat...";
CM_ BO_ 2566775038 "Ambient Conditions 2";
CM_ SG_ 2566775038 BrmtrAsltPrssrHghRsltn "Barometric Absolute Pressure (High Resolution): Barometric Absolute Pressure (High Resolution).  See SPN 108 if high resolution is not needed.";
CM_ SG_ 2566775038 CalculatedAmbientAirTemperature "Calculated Ambient Air Temperature: Calculated temperature of air surrounding vehicle.  Use SPN 171 for actual measured ambient air temperature.";
CM_ SG_ 2566775038 SolarIntensityPercent "Solar Intensity Percent: This is the solar radiation (power density) falling on the vehicle in percent of the maximum sensor value (SPN 2611).  Currently this is in the infra-red spectrum.";
CM_ SG_ 2566775038 SolarSensorMaximum "Solar Sensor Maximum: This is the maximum value which can be reported by the sensor for the solar intensity. (This is a configuration parameter)";
CM_ SG_ 2566775038 SpecificHumidity "Specific Humidity: Specific humidity of the ambient intake air.";
CM_ BO_ 2566775294 "Cab Climate System Information 1";
CM_ SG_ 2566775294 AirConditionerCompressorStatus "Air Conditioner Compressor Status: Signal which indicates if the Air Conditioner compressor is on or off.00b = Air Conditioner Compressor is OFF01b = Air Conditioner Compressor is ON10b = Error11b = Not Available";
CM_ SG_ 2566775294 CACRfrgrntCmprssrOtltPrssr "Cab A/C Refrigerant Compressor Outlet Pressure: This is the gage pressure at the compressor outlet in the cab air conditioning system.";
CM_ BO_ 2566775550 "Supply Pressure Demand";
CM_ SG_ 2566775550 ArSspnsnSpplPrssrRqst "Air Suspension Supply Pressure Request: Command signal to influence the pneumatic pressure in the circuit for the electronically controlled air suspension system.   This parameter is the setpoint for the parameter SPN 1090.";
CM_ SG_ 2566775550 AxlrEqpmntSpplPrssrRqst "Auxiliary Equipment Supply Pressure Request: Command signal to influence the pneumatic pressure in the auxiliary circuit.   This parameter is the setpoint for the parameter SPN 1089.";
CM_ SG_ 2566775550 PneumaticSupplyPressureRequest "Pneumatic Supply Pressure Request: Command signal to influence the pneumatic pressure in the main reservoir.  This parameter is the setpoint for the parameter SPN 46.";
CM_ SG_ 2566775550 PrkngndrTrlrArPrssrRqst "Parking and/or Trailer Air Pressure Request: Command signal to influence the pneumatic pressure in the circuit or reservoir for the parking brake and/or the trailer supply.  This parameter is the setpoint for the parameter SPN 1086.";
CM_ SG_ 2566775550 PwrtrnCrtArSpplPrssrRqst "Powertrain Circuit Air Supply Pressure Request: Command signal to influence the air pressure in the powertrain circuit.  This parameter is the setpoint for the parameter SPN 6305.";
CM_ SG_ 2566775550 SrvBrkArPrssrRqstCrt1 "Service Brake Air Pressure Request, Circuit #1: Command signal to influence the pneumatic pressure in the service brake circuit or reservoir #1.  This parameter is the setpoint for the parameter SPN 1087.";
CM_ SG_ 2566775550 SrvBrkArPrssrRqstCrt2 "Service Brake Air Pressure Request, Circuit #2: Command signal to influence the pneumatic pressure in the service brake circuit or reservoir #2.  This parameter is the setpoint for the parameter SPN 1088.";
CM_ BO_ 2566775806 "Equipment Operation and Control";
CM_ SG_ 2566775806 TravelVelocityControlPosition "Travel Velocity Control Position: The position of the travel velocity control component reported as a percentage of the control's full displacement in each direction respectively.  Positive position values indicate forward travel direction;  negative...";
CM_ BO_ 2566776062 "Equipment Performance Data";
CM_ SG_ 2566776062 PayloadCapacityPercentage "Payload Capacity Percentage: The current equipment payload plus the weight of any after-factory modifications reported as a percentage of the equipment's maximum payload capacity. The equipment's maximum payload capacity is the maximum capacity of th...";
CM_ SG_ 2566776062 PayloadCarryBackWeight "Payload Carry Back Weight: The payload weight left on the machine after the last payload dump event.";
CM_ SG_ 2566776062 PayloadPercentage "Payload Percentage: The current payload of the equipment, reported as a percentage of the equipment's rated payload limit.";
CM_ SG_ 2566776062 PayloadWeight "Payload Weight: The current payload weight carried by the machine.";
CM_ SG_ 2566776062 PayloadWeightConfidence "Payload Weight Confidence: The level of confidence of the real time payload weight measurement (SPN 6851). Higher confidence values indicate greater probability the real time payload weight is the actual weight and providing feedback on the potential...";
CM_ BO_ 2566776318 "Maximum Vehicle Speed Limit Status";
CM_ SG_ 2566776318 AppliedVehicleSpeedLimit "Applied Vehicle Speed Limit: The vehicle speed limit in effect.251 (FBh) is used to indicate that a maximum vehicle speed limit is not selected.See SPN 7420 for alternate resolution.";
CM_ SG_ 2566776318 MaximumVehicleSpeedLimit1 "Maximum Vehicle Speed Limit 1: The lowest Maximum Vehicle Speed Limit. This value is the similar to SPN 74. However, SPN 74 was not specifically defined to convey the applied vehicle speed limit or what was possible to be applied. This new SP is the ...";
CM_ SG_ 2566776318 MaximumVehicleSpeedLimit2 "Maximum Vehicle Speed Limit 2: The highest of the two lowest vehicle speed limits";
CM_ SG_ 2566776318 MaximumVehicleSpeedLimit3 "Maximum Vehicle Speed Limit 3: The highest of the three lowest vehicle speed limits";
CM_ SG_ 2566776318 MaximumVehicleSpeedLimit4 "Maximum Vehicle Speed Limit 4: The highest of the four lowest vehicle speed limits";
CM_ SG_ 2566776318 MaximumVehicleSpeedLimit5 "Maximum Vehicle Speed Limit 5: The highest of the five lowest vehicle speed limits";
CM_ SG_ 2566776318 MaximumVehicleSpeedLimit6 "Maximum Vehicle Speed Limit 6: The highest of the six lowest vehicle speed limits";
CM_ SG_ 2566776318 MaximumVehicleSpeedLimit7 "Maximum Vehicle Speed Limit 7: The highest of the seven lowest vehicle speed limits";
CM_ BO_ 2566785022 "Exhaust Temperature";
CM_ SG_ 2566785022 EngnExhstMnfldBnk1Tmprtr1 "Engine Exhaust Manifold Bank 1 Temperature 1: Temperature of combustion byproducts measured in engine bank 1 (left bank) exhaust manifold.  Single manifold engines should use exhaust temperature (SPN 173).";
CM_ SG_ 2566785022 EngnExhstMnfldBnk1Tmprtr2 "Engine Exhaust Manifold Bank 1 Temperature 2: Temperature of combustion byproducts measured by a second sensor in engine bank 1 (left bank) exhaust manifold. This should be used for the sensor toward the rear of the engine on the bank 1 manifold.";
CM_ SG_ 2566785022 EngnExhstMnfldBnk2Tmprtr1 "Engine Exhaust Manifold Bank 2 Temperature 1: Temperature of combustion byproducts measured in engine bank 2 (right bank) exhaust manifold.  Single manifold engines should use exhaust temperature (SPN 173).";
CM_ SG_ 2566785022 EngnExhstMnfldBnk2Tmprtr2 "Engine Exhaust Manifold Bank 2 Temperature 2: Temperature of combustion byproducts measured by a second sensor in engine bank 2 (right bank) exhaust manifold. This should be used for the sensor toward the rear of the engine on the bank 2 manifold.";
CM_ BO_ 2566799614 "Lighting Data";
CM_ SG_ 2566799614 AlternateBeamHeadLightData "Alternate Beam Head Light Data: This parameter provides measured data from the tractor alternate beam head light lamps. 00b = De-activated01b = Activated10b = Fault Detected11b = Not Available";
CM_ SG_ 2566799614 BackUpLightandAlarmHorn "Back Up Light and Alarm Horn: This parameter provides measured data from the back up lights and/ or associated alarm.00b = De-activated01b = Activated10b = Fault Detected11b = Not Available";
CM_ SG_ 2566799614 CenterStopLight "Center Stop Light: This parameter provides measured data from the tractor and attached implement center stop lights.00b = De-activated01b = Activated10b = Fault Detected11b = Not Available";
CM_ SG_ 2566799614 HighBeamHeadLightData "High Beam Head Light Data: This parameter provides measured data from the tractor high beam head light lamps. 00b = De-activated01b = Activated10b = Fault Detected11b = Not Available";
CM_ SG_ 2566799614 ImplementClearanceLight "Implement Clearance Light: This parameter provides measured data from an attached implement high mounted clearance lights.00b = De-activated01b = Activated10b = Fault Detected11b = Not Available";
CM_ SG_ 2566799614 ImplementLeftFacingWorkLight "Implement Left Facing Work Light: This parameter provides measured data from the left facing work lights toward the left end of the implement.00b = De-activated01b = Activated10b = Fault Detected11b = Not Available";
CM_ SG_ 2566799614 ImplementLeftForwardWorkLight "Implement Left Forward Work Light: This parameter provides measured data from the work lights mounted on an implement to illuminate the forward left end of the implement.00b = De-activate01b = Activate10b = Fault Detected11b = Not Available";
CM_ SG_ 2566799614 ImplementMarkerLight "Implement Marker Light: This parameter provides measured data from an attached implement marker lights, including front position lights, rear tail lights, side running lights, license plate lights and instruments and switch back lights.00b = De-activ...";
CM_ SG_ 2566799614 ImplementOEMOption1Light "Implement OEM Option 1 Light: This parameter provides measured data from the implement OEM option 1 light.00b = De-activated01b = Activated10b = Fault Detected11b = Not Available";
CM_ SG_ 2566799614 ImplementOEMOption2Light "Implement OEM Option 2 Light: This parameter provides measured data from the implement OEM option 2 light.00b = De-activated01b = Activated10b = Fault Detected11b = Not Available";
CM_ SG_ 2566799614 ImplementRearWorkLight "Implement Rear Work Light: This parameter provides measured data from the implement rear work lamps.00b = De-activated01b = Activated10b = Fault Detected11b = Not Available";
CM_ SG_ 2566799614 ImplementRightFacingWorkLight "Implement Right Facing Work Light: This parameter provides measured data from the work lights mounted on an implement to illuminate beyond right end of the implement.00b = De-activated01b = Activated10b = Fault Detected11b = Not Available";
CM_ SG_ 2566799614 ImplementRightForwardWorkLight "Implement Right Forward Work Light: This parameter provides measured data from the forward facing work lights toward the right end of the implement.00b = De-activated01b = Activated10b = Fault Detected11b = Not Available";
CM_ SG_ 2566799614 LeftStopLight "Left Stop Light: This parameter provides measured data from the tractor and attached implement left stop lights.00b = De-activated01b = Activated10b = Fault Detected11b = Not Available";
CM_ SG_ 2566799614 LeftTurnSignalLights "Left Turn Signal Lights: This parameter provides measured data from the tractor and attached implement left turn signal lights.00b = De-activated01b = Activated10b = Fault Detected11b = Not Available";
CM_ SG_ 2566799614 LowBeamHeadLightData "Low Beam Head Light Data: This parameter provides measured data from the tractor low beam head light lamps. 00b = De-activated01b = Activated10b = Fault Detected11b = Not Available";
CM_ SG_ 2566799614 RearFogLights "Rear Fog Lights: This parameter provides measured data from the tractor and/or implement rear fog lights.00b = De-activated01b = Activated10b = Fault Detected11b = Not Available";
CM_ SG_ 2566799614 RightStopLight "Right Stop Light: This parameter provides measured data from the tractor and attached implement right stop lights.00b = De-activated01b = Activated10b = Fault Detected11b = Not Available";
CM_ SG_ 2566799614 RightTurnSignalLights "Right Turn Signal Lights: This parameter provides measured data from the tractor and attached implement right turn signal lights.00b = De-activated01b = Activated10b = Fault Detected11b = Not Available";
CM_ SG_ 2566799614 RotatingBeaconLight "Rotating Beacon Light: This parameter provides measured data from the beacon light on tractor or attached implements.00b = De-activated01b = Activated10b = Fault Detected11b = Not Available";
CM_ SG_ 2566799614 RunningLight "Running Light: This parameter provides measured data from the vehicle's running lights.00b = De-activated01b = Activated10b = Fault Detected11b = Not Available";
CM_ SG_ 2566799614 TractorClearanceLight "Tractor Clearance Light: This parameter provides measured data from the tractor high mounted clearance and center ID lights.00b = De-activated01b = Activated10b = Fault Detected11b = Not Available";
CM_ SG_ 2566799614 TractorFrontFogLights "Tractor Front Fog Lights: This parameter provides measured data from the tractor front fog lights.00b = De-activated01b = Activated10b = Fault Detected11b = Not Available";
CM_ SG_ 2566799614 TractorMarkerLight "Tractor Marker Light: This parameter provides measured data from the tractor and attached implement marker lights, including front position lights, rear tail lights, side running lights, license plate lights and instruments and switch back lights.00b...";
CM_ SG_ 2566799614 TractorRearLowMountedWorkLights "Tractor Rear Low Mounted Work Lights: This parameter provides measured data from the tractor rear low mounted work lights.00b = De-activated01b = Activated10b = Fault Detected11b = Not Available";
CM_ SG_ 2566799614 TractorSideLowMountedWorkLights "Tractor Side Low Mounted Work Lights: This parameter provides measured data from the tractor side low mounted work lights. 00b = De-activated01b = Activated10b = Fault Detected11b = Not Available";
CM_ SG_ 2566799614 TrtrFrntHghMntdWrkLghts "Tractor Front High Mounted Work Lights: This parameter provides measured data from the tractor front high mounted work lights. 00b = De-activated01b = Activated10b = Fault Detected11b = Not Available";
CM_ SG_ 2566799614 TrtrFrntLwMntdWrkLghts "Tractor Front Low Mounted Work Lights: This parameter provides measured data from the tractor front low mounted work lights. 00b = De-activated01b = Activated10b = Fault Detected11b = Not Available";
CM_ SG_ 2566799614 TrtrRrHghMntdWrkLghts "Tractor Rear High Mounted Work Lights: This parameter provides measured data from the tractor rear high mounted work lights. 00b = De-activated01b = Activated10b = Fault Detected11b = Not Available";
CM_ SG_ 2566799614 TrtrSdHghMntdWrkLghts "Tractor Side High Mounted Work Lights: This parameter provides measured data from the tractor side high mounted work lights. 00b = De-activated01b = Activated10b = Fault Detected11b = Not Available";
CM_ SG_ 2566799614 TrtrUndrsdMntdWrkLghts "Tractor Underside Mounted Work Lights: This parameter provides measured data from the tractor underside mounted work lights. 00b = De-activated01b = Activated10b = Fault Detected11b = Not Available";
CM_ BO_ 2566802174 "Electronic Transmission Controller 7";
CM_ SG_ 2566802174 ActiveShiftConsoleIndicator "Active Shift Console Indicator: Signal from transmission control unit indicating which shift console (primary or secondary) it currently considers as the active shift selector input.00b = Primary shift console is active01b = Secondary shift console i...";
CM_ SG_ 2566802174 TransmissionEngineCrankEnable "Transmission Engine Crank Enable: State signal from the transmission indicating if the transmission's status is such that engine cranking is allowed (i.e.  at a minimum, transmission is in neutral and the driveline is disengaged).  As sender of this ...";
CM_ SG_ 2566802174 TransmissionManualModeIndicator "Transmission Manual Mode Indicator: This parameter indicates if the operator has selected a Manual Mode of the transmission. When a Manual Mode is active, the operator has directly and intentionally restricted the available transmission ranges for th...";
CM_ SG_ 2566802174 TransmissionMode10Indicator "Transmission Mode 10 Indicator: Indicates that the transmission is operating under transmission mode 10 (SPN 6570) as commanded via the TC2 message (PGN 3328). The definition of the transmission mode is left to the discretion of the transmission manu...";
CM_ SG_ 2566802174 TransmissionMode1Indicator "Transmission Mode 1 Indicator: This state signal is the transmission's indication that it is operating under transmission mode 1 (SPN 1852) as commanded via the TC1 message (PGN 256).  The definition of the transmission mode is left to the discretion...";
CM_ SG_ 2566802174 TransmissionMode2Indicator "Transmission Mode 2 Indicator: This state signal is the transmission's indication that it is operating under transmission mode 2 (SPN 1853) as commanded via the TC1 message (PGN 256).  The definition of the transmission mode is left to the discretion...";
CM_ SG_ 2566802174 TransmissionMode3Indicator "Transmission Mode 3 Indicator: This state signal is the transmission's indication that it is operating under transmission mode 3 (SPN 1854) as commanded via the TC1 message (PGN 256).  The definition of the transmission mode is left to the discretion...";
CM_ SG_ 2566802174 TransmissionMode4Indicator "Transmission Mode 4 Indicator: This state signal is the transmission's indication that it is operating under transmission mode 4 (SPN 1855) as commanded via the TC1 message (PGN 256).  The definition of the transmission mode is left to the discretion...";
CM_ SG_ 2566802174 TransmissionMode5Indicator "Transmission Mode 5 Indicator: This state signal is the transmission's indication that it is operating under transmission mode 5 (SPN 4246) as commanded via the TC1 message (PGN 256).  The definition of the transmission mode is left to the discretion...";
CM_ SG_ 2566802174 TransmissionMode6Indicator "Transmission Mode 6 Indicator: This state signal is the transmission's indication that it is operating under transmission mode 6 (SPN 4247) as commanded via the TC1 message (PGN 256).  The definition of the transmission mode is left to the discretion...";
CM_ SG_ 2566802174 TransmissionMode7Indicator "Transmission Mode 7 Indicator: This state signal is the transmission's indication that it is operating under transmission mode 7 (SPN 4248) as commanded via the TC1 message (PGN 256).  The definition of the transmission mode is left to the discretion...";
CM_ SG_ 2566802174 TransmissionMode8Indicator "Transmission Mode 8 Indicator: This state signal is the transmission's indication that it is operating under transmission mode 8 (SPN 4249) as commanded via the TC1 message (PGN 256).  The definition of the transmission mode is left to the discretion...";
CM_ SG_ 2566802174 TransmissionMode9Indicator "Transmission Mode 9 Indicator: Indicates that the transmission is operating under transmission mode 9 (SPN 6569) as commanded via the TC2 message (PGN 3328). The definition of the transmission mode is left to the discretion of the transmission manufa...";
CM_ SG_ 2566802174 TransmissionServiceIndicator "Transmission Service Indicator: Signal from transmission indicating that some aspect of the gearbox requires servicing, such as the oil, filter, clutch(es) or other component.00b = Transmission Service Indicator is off01b = Transmission Service Indic...";
CM_ SG_ 2566802174 TransmissionWarningIndicator "Transmission Warning Indicator: Signal from transmission indicating that some aspect of its operation is not functioning correctly, and as a result, transmission operation may be altered or restricted.  The indicator is typically a lamp.  Distinction...";
CM_ SG_ 2566802174 TrnsmssnArSpplPrssrIndtr "Transmission Air Supply Pressure Indicator: Indicates whether transmission air supply is sufficient000b = Normal Pressure Range - The transmission supply air pressure is within the normal operational range.001b = Low pressure - The transmission suppl...";
CM_ SG_ 2566802174 TrnsmssnAtNtrlMnlRtrnStt "Transmission Auto-Neutral (Manual Return) State: Indicates the transmission response to a Neutral request from SPN 7695 [Transmission Auto-Neutral (Manual Return) Request] or other vehicle input configured for Auto-Neutral (Manual Return) functionali...";
CM_ SG_ 2566802174 TrnsmssnCrrntRngDsplBlnkStt "Transmission Current Range Display Blank State: State signal indicating a transmission request for the display of the Transmission Current Range parameter (SPN 163) to be blanked or not blanked.  The 'Transmission Current Range Display Blank State' i...";
CM_ SG_ 2566802174 TrnsmssnRdfrBrkRls "Transmission Ready for Brake Release: This parameter indicates that enough torque / motive force is available at the transmission output shaft to release all the brakes without a risk of unintentional movement in the opposite direction.00b = Transmis...";
CM_ SG_ 2566802174 TrnsmssnRqstdGrFdk "Transmission Requested Gear Feedback: Feedback of the SPN 525 Transmission Requested Gear input as received from the shift selector, ABS or engine via PGN 256, Transmission Control 1 (TC1) or other transmission selector input.  Scaling, values and pa...";
CM_ SG_ 2566802174 TrnsmssnRqstdRngDsplBlnkStt "Transmission Requested Range Display Blank State: State signal indicating a transmission request for the display of the Transmission Requested Range parameter (SPN162) to be blanked or not blanked.  The 'Transmission Requested Range Display Blank Sta...";
CM_ SG_ 2566802174 TrnsmssnRqstdRngDsplFlshStt "Transmission Requested Range Display Flash State: State signal indicating a transmission request for the display of the Transmission Requested Range parameter (SPN 162) to flash or not to flash. The 'Transmission Requested Range Display Flash State' ...";
CM_ SG_ 2566802174 TrnsmssnRvrsGrShftInhtStts "Transmission Reverse Gear Shift Inhibit Status: Reflects the status of transmission reverse inhibit activity in response to requests via SPN 4242 - Transmission Reverse Gear Shift Inhibit Request.  Typically broadcast by the transmission controller.0...";
CM_ SG_ 2566802174 TrnsmssnShftInhtIndtr "Transmission Shift Inhibit Indicator: State signal indicating a transmission request for the Shift Inhibit Indicator to be active or inactive. The shift inhibit indicator can be of lamp or text form, located on (but not limited to) the shift console,...";
CM_ SG_ 2566802174 TrnsmssnLdRdtnIndtr "Transmission Load Reduction Indicator: This parameter indicates whether or not the transmission has internally disconnected from the driveline in order to reduce transmission parastic drag on the vehicle while it is stopped or nearly stopped. Most of...";
CM_ SG_ 2566802174 TrnsmssnPrDfndRngLmtIndtr "Transmission Pre-Defined Range Limit Indicator: This parameter indicates if the transmission is currently restricted to operation below a pre-defined range as requested by SPN 11751 [Transmission Pre-Defined Maximum Gear Activation Request].00b = Pre...";
CM_ SG_ 2566802174 TransmissionCoastModeIndicator "Transmission Coast Mode Indicator: Parameter indicates whether or not the transmission has internally disconnected from the driveline in order to reduce engine and transmission parastic drag on the vehicle while it is in motion. Most often used to im...";
CM_ BO_ 2566802430 "Transmission Configuration 2";
CM_ SG_ 2566802430 TransmissionReferenceTorque "Transmission Reference Torque: This parameter is the 100% reference value for all defined transmission output torque parameters.  For a given vehicle application, it is only defined once and doesn't change.";
CM_ SG_ 2566802430 TransmissionTorqueLimit "Transmission Torque Limit: Parameter provided to the engine from the transmission as a torque limit to be invoked by the engine in the event that J1939 communication with the transmission is lost.The intention is to protect transmissions that use a c...";
CM_ SG_ 2566802430 TrnsmssnCmmntnsFlrIdlTrqLmt "Transmission Communications Failure Idle Torque Limit: This parameter is provided to the engine from the transmission as an idle governor torque limit to be invoked by the engine in the event that CAN communication with the transmission is lost.The d...";
CM_ BO_ 2566802686 "Military Lighting Command";
CM_ SG_ 2566802686 BlackOutBrakeStopLampSelect "Black Out Brake/Stop Lamp Select: Black Out Brake/Stop Lamp Selection00b = Off01b = On10b = Reserved11b = Not Supported";
CM_ SG_ 2566802686 BlackOutWorkLampSelect "Black Out Work Lamp Select: Black Out Work Lamp Selection00b = Off01b = On10b = Reserved11b = Not Supported";
CM_ SG_ 2566802686 ConvoyDrivingLampSelect "Convoy Driving Lamp Select: Black Out Convoy Driving Lamp Selection00b = Off01b = On10b = Reserved11b = Not Supported";
CM_ SG_ 2566802686 ConvoyLampSelect "Convoy Lamp Select: Black Out Convoy Lamp Selection00b = Off01b = On10b = Reserved11b = Not Supported";
CM_ SG_ 2566802686 FrontBlackOutMarkerLampSelect "Front Black Out Marker Lamp Select: Front Black Out Marker Lamp Selection00b = Off01b = On10b = Reserved11b = Not Supported";
CM_ SG_ 2566802686 NightVisionIlluminatorSelect "Night Vision Illuminator Select: Night Vision Illuminator Selection00b = Off01b = On10b = Reserved11b = Not Supported";
CM_ SG_ 2566802686 OprtrsBlkOtIntnstSltn "Operators Black Out Intensity Selection: Operators Selection of lamp intensity in black out mode.  This parameter provides the operators selected illumination intensity as a percentage of available full scale.  This parameter would be typically used ...";
CM_ SG_ 2566802686 RearBlackOutMarkerSelect "Rear Black Out Marker Select: Rear Black Out Marker Selection00b = Off01b = On10b = Reserved11b = Not Supported";
CM_ BO_ 2566803198 "Door Control 1";
CM_ SG_ 2566803198 Positionofdoors "Position of doors: Signal which indicates the actual position of the doors.0000b = At least 1 door is open0001b = Closing last door0010b = All doors close0011b to 1101b = Not defined1110b = Error1111b = Not available";
CM_ SG_ 2566803198 RampWheelChairLiftPosition "Ramp / Wheel Chair Lift Position: Signal which indicates the actual position of the ramp / wheel chair lift.00b = Inside bus01b = Outside bus10b = Error11b = Not available";
CM_ SG_ 2566803198 Status2ofdoors "Status 2 of doors: Composite indication of all bus door statuses. Enabled means the bus doors are able to be automatically opened or closed.00b = all bus doors are disabled01b = at least 1 bus door enabled 10b = error11b = not available";
CM_ BO_ 2566803454 "Vehicle Dynamic Stability Control 1";
CM_ SG_ 2566803454 ROPBrakeControlactive "ROP Brake Control active: State signal which indicates that Roll over Prevention (ROP) has activated brake control. Active means that ROP actually controls wheel brake pressure at one or more wheels of the vehicle or vehicle combination. Within the p...";
CM_ SG_ 2566803454 ROPEngineControlactive "ROP Engine Control active: State Signal which indicates that the Roll Over Prevention (ROP) has commanded engine control to be active. Within the physical limits, ROP attempts to prevent rolling over of the vehicle. Active means that ROP actually tri...";
CM_ SG_ 2566803454 TrailerVDCActive "Trailer-VDC Active: The trailer-VDC (Vehicle Dynamic Control) is an electronic vehicle stability function within the (semi) trailer braking system. It acts to stabilize the (semi) trailer during dynamic maneuvers. VDC includes Roll Over Prevention (R...";
CM_ SG_ 2566803454 VDCbrakelightrequest "VDC brake light request: Indicates whether VDC requests to turn the vehicle brake lights on00b = Turn brake light not on01b = Turn brake light on10b = Reserved11b = Don't care/Take no action";
CM_ SG_ 2566803454 VDCFullyOperational "VDC Fully Operational: Signal that indicates whether VDC is fully operational or whether its functionality is reduced by a permanent or temporary (e.g. low voltage) defect, by intended action (e.g. disabled by a switch or during special diagnostic pr...";
CM_ SG_ 2566803454 VDCInformationSignal "VDC Information Signal: This parameter commands the VDC information signal, for example a dash lamp.00b = Off01b = On10b = Reserved11b = Don't care/Take no action";
CM_ SG_ 2566803454 YCBrakeControlactive "YC Brake Control active: State signal which indicates that Yaw Control (YC) has activated brake control. Active means that YC actually controls wheel brake pressure at one or more wheels of the vehicle or vehicle combination. Within the physical limi...";
CM_ SG_ 2566803454 YCEngineControlactive "YC Engine Control active: State Signal which indicates that the Yaw Control (YC) has commanded engine control to be active. Within the physical limits, YC attempts to prevent yawing of the vehicle. Active means that YC actually tries to control the e...";
CM_ BO_ 2566803710 "Battery Temperature";
CM_ SG_ 2566803710 SLIBattery1Temperature "SLI Battery 1 Temperature: Temperature of the battery 1 used for starting the engine, for lighting, and for ignition (SLI). The relation to physical location is determined by the equipment manufacturer.";
CM_ SG_ 2566803710 SLIBattery2Temperature "SLI Battery 2 Temperature: Temperature of the second battery or second set of batteries used for starting the engine, for lighting, and for ignition (SLI). The relation to physical location is determined by the equipment manufacturer.";
CM_ SG_ 2566803710 SLIBattery3Temperature "SLI Battery 3 Temperature: Temperature of the third battery or third set of batteries used for starting the engine, for lighting, and for ignition (SLI). The relation to physical location is determined by the equipment manufacturer.";
CM_ SG_ 2566803710 SLIBattery4Temperature "SLI Battery 4 Temperature: Temperature of the fourth battery or fourth set of batteries used for starting the engine, for lighting, and for ignition (SLI). The relation to physical location is determined by the equipment manufacturer.";
CM_ BO_ 2566803966 "Adaptive Cruise Control, Operator Input";
CM_ SG_ 2566803966 ACCusagedemand "ACC usage demand: This parameter indicates the drivers demand to activate or deactivate ACC keeping distance control.00b = driver demand for not using ACC distance keeping control01b = driver demand for using ACC distance keeping control10b = reserve...";
CM_ SG_ 2566803966 RequestedACCDistanceMode "Requested ACC Distance Mode: The Requested Distance Control Mode to the ACC system from the operators interface.The ACC Set Distance Mode (SPN 1589) indicates the selected Distance Control Mode for the ACC system. This parameter is the driver request...";
BA_DEF_ SG_  "SPN" INT 0 524287;
BA_DEF_ BO_  "VFrameFormat" ENUM  "StandardCAN","ExtendedCAN","reserved","J1939PG";
BA_DEF_DEF_  "SPN" 0;
BA_DEF_DEF_  "VFrameFormat" "J1939PG";
BA_ "SPN" SG_ 2566756606 Aftertreatment1TotalFuelUsed 3522;
BA_ "SPN" SG_ 2566756606 Aftrtrtmnt1TtlDsldTm 3524;
BA_ "SPN" SG_ 2566756606 Aftrtrtmnt1TtlNmrfAtvRgnrtns 3525;
BA_ "SPN" SG_ 2566756606 Aftrtrtmnt1TtlRgnrtnTm 3523;
BA_ "SPN" SG_ 2566756606 Atttt1DsPttFtAvDstBtwAtvRts 5827;
BA_ "SPN" SG_ 2566756606 Atttt1DsPttFtAvTBtwAtvRts 5454;
BA_ "SPN" SG_ 2566756606 Atttt1DsPttFtTtNAtvRtItRqsts 3727;
BA_ "SPN" SG_ 2566756606 Atttt1DsPttFtTtNAtvRtMRqsts 3728;
BA_ "SPN" SG_ 2566756606 Atttt1DsPttFtTtNPssvRts 3726;
BA_ "SPN" SG_ 2566756606 Atttt1DsPttFtTtPssvRtT 3725;
BA_ "SPN" SG_ 2566756862 Aftertreatment2TotalFuelUsed 3526;
BA_ "SPN" SG_ 2566756862 Aftrtrtmnt2TtlDsldTm 3528;
BA_ "SPN" SG_ 2566756862 Aftrtrtmnt2TtlNmrfAtvRgnrtns 3529;
BA_ "SPN" SG_ 2566756862 Aftrtrtmnt2TtlRgnrtnTm 3527;
BA_ "SPN" SG_ 2566756862 Atttt2DsPttFtAvDstBtwAtvRts 5828;
BA_ "SPN" SG_ 2566756862 Atttt2DsPttFtAvTBtwAtvRts 5455;
BA_ "SPN" SG_ 2566756862 Atttt2DsPttFtTtNAtvRtItRqsts 3731;
BA_ "SPN" SG_ 2566756862 Atttt2DsPttFtTtNAtvRtMRqsts 3732;
BA_ "SPN" SG_ 2566756862 Atttt2DsPttFtTtNPssvRts 3730;
BA_ "SPN" SG_ 2566756862 Atttt2DsPttFtTtPssvRtT 3729;
BA_ "SPN" SG_ 2566757374 Aftrtrtmnt1DslExhstFldCndtvt 3518;
BA_ "SPN" SG_ 2566757374 Aftrtrtmnt1DslExhstFldCnntrtn 3516;
BA_ "SPN" SG_ 2566757374 Aftrtrtmnt1DslExhstFldPrprt 3521;
BA_ "SPN" SG_ 2566757374 Aftrtrtmnt1DslExhstFldTmprtr2 3515;
BA_ "SPN" SG_ 2566757374 Atttt1DsExstFdPptsPFMI 3520;
BA_ "SPN" SG_ 2566757374 Atttt1DsExstFdTpt2PFMI 3519;
BA_ "SPN" SG_ 2566757374 DieselExhaustFluidSpeedofSound 7346;
BA_ "SPN" SG_ 2566757630 Sensorsupplyvoltage5 3513;
BA_ "SPN" SG_ 2566757630 Sensorsupplyvoltage6 3514;
BA_ "SPN" SG_ 2566757630 Sensorsupplyvoltage7 5125;
BA_ "SPN" SG_ 2566757630 Sensorsupplyvoltage8 5126;
BA_ "SPN" SG_ 2566757886 Sensorsupplyvoltage1 3509;
BA_ "SPN" SG_ 2566757886 Sensorsupplyvoltage2 3510;
BA_ "SPN" SG_ 2566757886 Sensorsupplyvoltage3 3511;
BA_ "SPN" SG_ 2566757886 Sensorsupplyvoltage4 3512;
BA_ "SPN" SG_ 2566758142 Aftertreatment2AirSystemRelay 3506;
BA_ "SPN" SG_ 2566758142 Aftertreatment2PurgeAirActuator 3504;
BA_ "SPN" SG_ 2566758142 Aftertreatment2PurgeAirPressure 3500;
BA_ "SPN" SG_ 2566758142 Aftrtrtmnt2ArEnlAttr 3503;
BA_ "SPN" SG_ 2566758142 Aftrtrtmnt2ArPrssrAttrPstn 3502;
BA_ "SPN" SG_ 2566758142 Aftrtrtmnt2ArPrssrCntrl 3501;
BA_ "SPN" SG_ 2566758142 Aftrtrtmnt2AtmztnArAttr 3505;
BA_ "SPN" SG_ 2566758142 Aftrtrtmnt2SpplArPrssr 3499;
BA_ "SPN" SG_ 2566758398 Aftertreatment1AirSystemRelay 3492;
BA_ "SPN" SG_ 2566758398 Aftertreatment1PurgeAirActuator 3490;
BA_ "SPN" SG_ 2566758398 Aftertreatment1PurgeAirPressure 3486;
BA_ "SPN" SG_ 2566758398 Aftrtrtmnt1ArEnlAttr 3489;
BA_ "SPN" SG_ 2566758398 Aftrtrtmnt1ArPrssrAttrPstn 3488;
BA_ "SPN" SG_ 2566758398 Aftrtrtmnt1ArPrssrCntrl 3487;
BA_ "SPN" SG_ 2566758398 Aftrtrtmnt1AtmztnArAttr 3491;
BA_ "SPN" SG_ 2566758398 Aftrtrtmnt1SpplArPrssr 3485;
BA_ "SPN" SG_ 2566758654 Aftertreatment2FuelPressure1 3494;
BA_ "SPN" SG_ 2566758654 Aftertreatment2FuelRate 3495;
BA_ "SPN" SG_ 2566758654 Aftertreatment2Ignition 3498;
BA_ "SPN" SG_ 2566758654 Aftrtrtmnt2FlDrnAttr 4098;
BA_ "SPN" SG_ 2566758654 Aftrtrtmnt2FlEnlAttr 3496;
BA_ "SPN" SG_ 2566758654 Aftrtrtmnt2FlInjtr1HtrCntrl 4302;
BA_ "SPN" SG_ 2566758654 Aftrtrtmnt2FlPrssr1Cntrl 3493;
BA_ "SPN" SG_ 2566758654 Aftrtrtmnt2RgnrtnStts 3497;
BA_ "SPN" SG_ 2566758910 Aftertreatment1FuelPressure1 3480;
BA_ "SPN" SG_ 2566758910 Aftertreatment1FuelRate 3481;
BA_ "SPN" SG_ 2566758910 Aftertreatment1Ignition 3484;
BA_ "SPN" SG_ 2566758910 Aftrtrtmnt1FlDrnAttr 4097;
BA_ "SPN" SG_ 2566758910 Aftrtrtmnt1FlEnlAttr 3482;
BA_ "SPN" SG_ 2566758910 Aftrtrtmnt1FlInjtr1HtrCntrl 4301;
BA_ "SPN" SG_ 2566758910 Aftrtrtmnt1FlPrssr1Cntrl 3479;
BA_ "SPN" SG_ 2566758910 Aftrtrtmnt1RgnrtnStts 3483;
BA_ "SPN" SG_ 2566759678 AtleastonePTOengaged 3948;
BA_ "SPN" SG_ 2566759678 EnableSwitchPTOEngineFlywheel 3939;
BA_ "SPN" SG_ 2566759678 EnggmntCnsntPTOEngnAssrDrv1 3943;
BA_ "SPN" SG_ 2566759678 EnggmntCnsntPTOEngnAssrDrv2 3946;
BA_ "SPN" SG_ 2566759678 EnggmntCnsntPTOEngnFlwhl 3940;
BA_ "SPN" SG_ 2566759678 EnggmntSttsPTOEngnAssrDrv1 3944;
BA_ "SPN" SG_ 2566759678 EnggmntSttsPTOEngnAssrDrv2 3947;
BA_ "SPN" SG_ 2566759678 EnggmntSttsPTOEngnFlwhl 3941;
BA_ "SPN" SG_ 2566759678 EnlSwthPTOEngnAssrDrv1 3942;
BA_ "SPN" SG_ 2566759678 EnlSwthPTOEngnAssrDrv2 3945;
BA_ "SPN" SG_ 2566759678 EnlSwthTrnsfrstptshftPTO 3455;
BA_ "SPN" SG_ 2566759678 EnlSwthTrnsmssntptshftPTO 3454;
BA_ "SPN" SG_ 2566759678 EnlSwthTrnsmssnnptshftPTO2 3453;
BA_ "SPN" SG_ 2566759678 EnlSwthTrnsmssnnptshftPTO1 3452;
BA_ "SPN" SG_ 2566759678 EnggmntCnsntTrnsfrstptshftPTO 3459;
BA_ "SPN" SG_ 2566759678 EnggmntCnsntTrnsmssntptshftPTO 3458;
BA_ "SPN" SG_ 2566759678 EnggmntCnsntTrnsmssnnptshftPTO2 3457;
BA_ "SPN" SG_ 2566759678 EnggmntCnsntTrnsmssnnptshftPTO1 3456;
BA_ "SPN" SG_ 2566759678 EnggmntSttsTrnsfrstptshftPTO 3463;
BA_ "SPN" SG_ 2566759678 EnggmntSttsTrnsmssntptshftPTO 3462;
BA_ "SPN" SG_ 2566759678 EnggmntSttsTrnsmssnnptshftPTO2 3461;
BA_ "SPN" SG_ 2566759678 EnggmntSttsTrnsmssnnptshftPTO1 3460;
BA_ "SPN" SG_ 2566759678 PTOMessageCounter 15243;
BA_ "SPN" SG_ 2566759678 PTOMessageChecksum 15244;
BA_ "SPN" SG_ 2566759934 EnableStatusofDoor1 3414;
BA_ "SPN" SG_ 2566759934 EnableStatusofDoor10 3441;
BA_ "SPN" SG_ 2566759934 EnableStatusofDoor2 3417;
BA_ "SPN" SG_ 2566759934 EnableStatusofDoor3 3420;
BA_ "SPN" SG_ 2566759934 EnableStatusofDoor4 3423;
BA_ "SPN" SG_ 2566759934 EnableStatusofDoor5 3426;
BA_ "SPN" SG_ 2566759934 EnableStatusofDoor6 3429;
BA_ "SPN" SG_ 2566759934 EnableStatusofDoor7 3432;
BA_ "SPN" SG_ 2566759934 EnableStatusofDoor8 3435;
BA_ "SPN" SG_ 2566759934 EnableStatusofDoor9 3438;
BA_ "SPN" SG_ 2566759934 LockStatusofDoor1 3412;
BA_ "SPN" SG_ 2566759934 LockStatusofDoor10 3439;
BA_ "SPN" SG_ 2566759934 LockStatusofDoor2 3415;
BA_ "SPN" SG_ 2566759934 LockStatusofDoor3 3418;
BA_ "SPN" SG_ 2566759934 LockStatusofDoor4 3421;
BA_ "SPN" SG_ 2566759934 LockStatusofDoor5 3424;
BA_ "SPN" SG_ 2566759934 LockStatusofDoor6 3427;
BA_ "SPN" SG_ 2566759934 LockStatusofDoor7 3430;
BA_ "SPN" SG_ 2566759934 LockStatusofDoor8 3433;
BA_ "SPN" SG_ 2566759934 LockStatusofDoor9 3436;
BA_ "SPN" SG_ 2566759934 OpenStatusofDoor1 3413;
BA_ "SPN" SG_ 2566759934 OpenStatusofDoor10 3440;
BA_ "SPN" SG_ 2566759934 OpenStatusofDoor2 3416;
BA_ "SPN" SG_ 2566759934 OpenStatusofDoor3 3419;
BA_ "SPN" SG_ 2566759934 OpenStatusofDoor4 3422;
BA_ "SPN" SG_ 2566759934 OpenStatusofDoor5 3425;
BA_ "SPN" SG_ 2566759934 OpenStatusofDoor6 3428;
BA_ "SPN" SG_ 2566759934 OpenStatusofDoor7 3431;
BA_ "SPN" SG_ 2566759934 OpenStatusofDoor8 3434;
BA_ "SPN" SG_ 2566759934 OpenStatusofDoor9 3437;
BA_ "SPN" SG_ 2566760702 NetworkAntennaStatus2 3444;
BA_ "SPN" SG_ 2566760702 NetworkServiceStatus2 3443;
BA_ "SPN" SG_ 2566760702 NetworkSignalStrength2 3445;
BA_ "SPN" SG_ 2566760702 NetworkTransceiverStatus2 3442;
BA_ "SPN" SG_ 2566760702 WrlssCmmntnNtwrkTp2 3446;
BA_ "SPN" SG_ 2566760958 NetworkAntennaStatus1 3370;
BA_ "SPN" SG_ 2566760958 NetworkServiceStatus1 3369;
BA_ "SPN" SG_ 2566760958 NetworkSignalStrength1 3371;
BA_ "SPN" SG_ 2566760958 NetworkTransceiverStatus1 3368;
BA_ "SPN" SG_ 2566760958 WrlssCmmntnNtwrkTp1 3372;
BA_ "SPN" SG_ 2566761214 EngineAftercoolerCoolantLevel 3676;
BA_ "SPN" SG_ 2566761214 EngineCentrifugalOilFilterspeed 3343;
BA_ "SPN" SG_ 2566761214 EngnChrgArClr1IntkPrssr 3340;
BA_ "SPN" SG_ 2566761214 EngnChrgArClr2IntkPrssr 3341;
BA_ "SPN" SG_ 2566761214 EngnChrgArClrClntLvl 3668;
BA_ "SPN" SG_ 2566761214 EngnChrgArClrOtltPrssr 2631;
BA_ "SPN" SG_ 2566761214 EngnClntPmpDffrntlPrssr 3342;
BA_ "SPN" SG_ 2566761726 EngineIdleFuelFlowRateThreshold 2778;
BA_ "SPN" SG_ 2566761726 NmrfFlCnsmptnMntrngTrnsdrs 2777;
BA_ "SPN" SG_ 2566762238 FfthWhlLkCplSttsIndtr 3313;
BA_ "SPN" SG_ 2566762238 FfthWhlLkRdtCplIndtr 3312;
BA_ "SPN" SG_ 2566762238 FifthWheelErrorStatus 3307;
BA_ "SPN" SG_ 2566762238 FifthWheelSliderLockIndicator 3316;
BA_ "SPN" SG_ 2566762238 FifthWheelSliderPosition 3311;
BA_ "SPN" SG_ 2566762494 Aftrtrtmnt2ExhstTmprtr2 3283;
BA_ "SPN" SG_ 2566762494 Atttt2DsPttFtDtPss 3285;
BA_ "SPN" SG_ 2566762494 Atttt2DsPttFtDtPssPFMI 3287;
BA_ "SPN" SG_ 2566762494 Atttt2DsPttFtItdtTpt 3284;
BA_ "SPN" SG_ 2566762494 Atttt2DsPttFtItdtTptPFMI 3288;
BA_ "SPN" SG_ 2566762494 Atttt2ExstTpt2PFMI 3286;
BA_ "SPN" SG_ 2566762750 Aftrtrtmnt2ExhstTmprtr3 3279;
BA_ "SPN" SG_ 2566762750 Atttt2DsPttFtExstTptPFMI 3282;
BA_ "SPN" SG_ 2566762750 Atttt2DsPttFtOttTpt 3280;
BA_ "SPN" SG_ 2566762750 Atttt2ExstTpt3PFMI 3281;
BA_ "SPN" SG_ 2566763006 Aftrtrtmnt2ExhstTmprtr1 3275;
BA_ "SPN" SG_ 2566763006 Atttt2DsPttFtItTpt 3276;
BA_ "SPN" SG_ 2566763006 Atttt2DsPttFtItTptPFMI 3278;
BA_ "SPN" SG_ 2566763006 Atttt2ExstTpt1PFMI 3277;
BA_ "SPN" SG_ 2566763262 Aftrtrtmnt1ExhstTmprtr2 3249;
BA_ "SPN" SG_ 2566763262 Atttt1DsPttFtDtPss 3251;
BA_ "SPN" SG_ 2566763262 Atttt1DsPttFtDtPssPFMI 3253;
BA_ "SPN" SG_ 2566763262 Atttt1DsPttFtItdtTpt 3250;
BA_ "SPN" SG_ 2566763262 Atttt1DsPttFtItdtTptPFMI 3254;
BA_ "SPN" SG_ 2566763262 Atttt1ExstTpt2PFMI 3252;
BA_ "SPN" SG_ 2566763518 Aftrtrtmnt1ExhstTmprtr3 3245;
BA_ "SPN" SG_ 2566763518 Atttt1DsPttFtOttExstTptPFMI 3248;
BA_ "SPN" SG_ 2566763518 Atttt1DsPttFtOttTpt 3246;
BA_ "SPN" SG_ 2566763518 Atttt1ExstTpt3PFMI 3247;
BA_ "SPN" SG_ 2566763774 Aftrtrtmnt1ExhstTmprtr1 3241;
BA_ "SPN" SG_ 2566763774 Atttt1DsPttFtItTpt 3242;
BA_ "SPN" SG_ 2566763774 Atttt1DsPttFtItTptPFMI 3244;
BA_ "SPN" SG_ 2566763774 Atttt1ExstTpt1PFMI 3243;
BA_ "SPN" SG_ 2566765054 ReferenceTirePressure 3191;
BA_ "SPN" SG_ 2566765054 TireLocation 3190;
BA_ "SPN" SG_ 2566765310 FareboxAlarmIdentifier 3181;
BA_ "SPN" SG_ 2566765310 FareboxEmergencyStatus 3179;
BA_ "SPN" SG_ 2566765566 FareValidity 3165;
BA_ "SPN" SG_ 2566765566 InitialFareAgency 3167;
BA_ "SPN" SG_ 2566765566 PassCategory 3166;
BA_ "SPN" SG_ 2566765566 PassengerType 3171;
BA_ "SPN" SG_ 2566765566 PaymentDetails 3177;
BA_ "SPN" SG_ 2566765566 RouteNumber 3169;
BA_ "SPN" SG_ 2566765566 TransactionType 3170;
BA_ "SPN" SG_ 2566765566 TransferSold 3168;
BA_ "SPN" SG_ 2566765566 TransferType 3173;
BA_ "SPN" SG_ 2566765566 TypeofFare 3176;
BA_ "SPN" SG_ 2566765566 TypeofService 3172;
BA_ "SPN" SG_ 2566765822 AssignedBlock 3163;
BA_ "SPN" SG_ 2566765822 AssignedRoute 3160;
BA_ "SPN" SG_ 2566765822 AssignedRun 3162;
BA_ "SPN" SG_ 2566765822 Driversfareboxsecuritycode 3164;
BA_ "SPN" SG_ 2566765822 FareboxServiceStatus 3178;
BA_ "SPN" SG_ 2566765822 FarePresets 3175;
BA_ "SPN" SG_ 2566765822 PatternNumber 3161;
BA_ "SPN" SG_ 2566765822 TripDirection 3174;
BA_ "SPN" SG_ 2566765822 TripNumber 3159;
BA_ "SPN" SG_ 2566765822 TripStatus 3180;
BA_ "SPN" SG_ 2566766078 IntrstnPrmptnRqstRspns 3079;
BA_ "SPN" SG_ 2566766078 PriorityofResponseSentbyEmitter 3084;
BA_ "SPN" SG_ 2566766078 RangeCodeEnable 3081;
BA_ "SPN" SG_ 2566766078 StrobeActivationControlStatus 3082;
BA_ "SPN" SG_ 2566766078 TransitDoorEnable 3083;
BA_ "SPN" SG_ 2566766078 TransitRouteIDUsage 3080;
BA_ "SPN" SG_ 2566766078 VehicleID 3085;
BA_ "SPN" SG_ 2566766334 Agency 3078;
BA_ "SPN" SG_ 2566766334 NmrftsnthTrnstAssgndBlkIdntt 3073;
BA_ "SPN" SG_ 2566766334 NmrftsnthTrnstAssgndRnIdntt 3072;
BA_ "SPN" SG_ 2566766334 NmrftsnthTrnstAssgndRtIdntt 3071;
BA_ "SPN" SG_ 2566766590 NmrftsnthMlpstIdntftn 3070;
BA_ "SPN" SG_ 2566766846 PatronCount 3047;
BA_ "SPN" SG_ 2566766846 SilentAlarmStatus 3044;
BA_ "SPN" SG_ 2566766846 TransitRunStatus 3046;
BA_ "SPN" SG_ 2566766846 TypeofPassengerCount 3043;
BA_ "SPN" SG_ 2566766846 VehicleUseStatus 3045;
BA_ "SPN" SG_ 2566767102 EngnExhstGsRrltn1IntkPrssr 3358;
BA_ "SPN" SG_ 2566767102 EngnExhstGsRrltn1OtltPrssr 5019;
BA_ "SPN" SG_ 2566767102 EngnExhstVlvAttnSstmOlPrssr 4287;
BA_ "SPN" SG_ 2566767102 EngnIntkVlvAttnSstmOlPrssr 2948;
BA_ "SPN" SG_ 2566767102 EngnThrttlVlv1DffrntlPrssr 5631;
BA_ "SPN" SG_ 2566767358 EngineFuelIsolationControl 7394;
BA_ "SPN" SG_ 2566767358 EngineFuelMassFlowRate 5833;
BA_ "SPN" SG_ 2566767358 EngnExhstGsRrltn1Vlv1PstnErrr 5829;
BA_ "SPN" SG_ 2566767358 EngnExhstGsRrltn1Vlv2PstnErrr 5830;
BA_ "SPN" SG_ 2566767358 FuelType 5837;
BA_ "SPN" SG_ 2566767614 AcceleratorPedal1Channel2 2623;
BA_ "SPN" SG_ 2566767614 AcceleratorPedal1Channel3 2624;
BA_ "SPN" SG_ 2566767614 AcceleratorPedal2Channel2 2625;
BA_ "SPN" SG_ 2566767614 AcceleratorPedal2Channel3 2626;
BA_ "SPN" SG_ 2566767614 EngnExhstGsRstrtnVlvCntrl 8150;
BA_ "SPN" SG_ 2566767870 BrakeTemperatureWarning 3839;
BA_ "SPN" SG_ 2566767870 EmergencyBrakingActive 5847;
BA_ "SPN" SG_ 2566767870 FoundationBrakeUse 2919;
BA_ "SPN" SG_ 2566767870 Haltbrakemode 2913;
BA_ "SPN" SG_ 2566767870 Hillholdermode 2912;
BA_ "SPN" SG_ 2566767870 PrkngBrkAttrFllAtvtd 5275;
BA_ "SPN" SG_ 2566767870 RailroadMode 7942;
BA_ "SPN" SG_ 2566767870 XBRAccelerationLimit 2921;
BA_ "SPN" SG_ 2566767870 XBRActiveControlMode 2918;
BA_ "SPN" SG_ 2566767870 XBRSystemState 2917;
BA_ "SPN" SG_ 2566768126 ECUHardwareID 6714;
BA_ "SPN" SG_ 2566768126 ECULocation 2903;
BA_ "SPN" SG_ 2566768126 ECUManufacturerName 4304;
BA_ "SPN" SG_ 2566768126 ECUPartNumber 2901;
BA_ "SPN" SG_ 2566768126 ECUSerialNumber 2902;
BA_ "SPN" SG_ 2566768126 ECUType 2904;
BA_ "SPN" SG_ 2566768126 ECUDateofManufacture 11746;
BA_ "SPN" SG_ 2566768382 EngineColdStartFuelIgniterRelay 5549;
BA_ "SPN" SG_ 2566768382 EngineStartEnableDevice1 626;
BA_ "SPN" SG_ 2566768382 EngineStartEnableDevice2 1804;
BA_ "SPN" SG_ 2566768382 EngnCldStrtFlIgntrCmmnd 5548;
BA_ "SPN" SG_ 2566768382 EngnCldStrtFlIgntrRlFdk 5550;
BA_ "SPN" SG_ 2566768382 EngnStrtEnlDv1Cnfgrtn 2899;
BA_ "SPN" SG_ 2566768382 EngnStrtEnlDv2Cnfgrtn 2898;
BA_ "SPN" SG_ 2566768638 EngineAuxiliaryGovernorState 2896;
BA_ "SPN" SG_ 2566768638 EngineMultiUnitSyncState 2890;
BA_ "SPN" SG_ 2566768638 EngineOperatingModeSelection 8664;
BA_ "SPN" SG_ 2566768638 EngineTorqueCurveSelection 1568;
BA_ "SPN" SG_ 2566768638 EngnAltrntDrpAlrtr2SltStt 2893;
BA_ "SPN" SG_ 2566768638 EngnAltrntLwIdlSltStt 2891;
BA_ "SPN" SG_ 2566768638 EngnAltrntRtngSltStt 2888;
BA_ "SPN" SG_ 2566768638 EngnDrpAlrtr1SltStt 2889;
BA_ "SPN" SG_ 2566768638 EngnDrpAxlrInptSltStt 2895;
BA_ "SPN" SG_ 2566768638 EngnDrpRmtAlrtrSltStt 2894;
BA_ "SPN" SG_ 2566768894 EngnOprtrPrmrIntrmdtSpdSltStt 2892;
BA_ "SPN" SG_ 2566769406 EngnOprtrPrmrIntrmdtSpdSlt 2880;
BA_ "SPN" SG_ 2566769662 EngineAlternateLowIdleSwitch 2883;
BA_ "SPN" SG_ 2566769662 EngineAlternateRatingSelect 2882;
BA_ "SPN" SG_ 2566769662 EngineAuxiliaryGovernorSwitch 2884;
BA_ "SPN" SG_ 2566769662 EngineDroopAccelerator1Select 2881;
BA_ "SPN" SG_ 2566769662 EngineDroopAccelerator2Select 2879;
BA_ "SPN" SG_ 2566769662 EngineDroopAuxiliaryInputSelect 2885;
BA_ "SPN" SG_ 2566769662 EngineOperatingModeCommand 8608;
BA_ "SPN" SG_ 2566769662 EngineSynchronizationSwitch 1377;
BA_ "SPN" SG_ 2566769662 EngnDrpRmtAlrtrSlt 2886;
BA_ "SPN" SG_ 2566769662 EngnTrqCrvSltnCmmnd 6796;
BA_ "SPN" SG_ 2566770174 FrntNnprtrWprDlCntrl 2870;
BA_ "SPN" SG_ 2566770174 FrontNonoperatorWasherSwitch 2867;
BA_ "SPN" SG_ 2566770174 FrontNonoperatorWiperSwitch 2864;
BA_ "SPN" SG_ 2566770174 FrontOperatorWasherSwitch 2866;
BA_ "SPN" SG_ 2566770174 FrontOperatorWiperDelayControl 2869;
BA_ "SPN" SG_ 2566770174 FrontOperatorWiperSwitch 2863;
BA_ "SPN" SG_ 2566770174 RearWasherFunction 2868;
BA_ "SPN" SG_ 2566770174 RearWiperDelayControl 2871;
BA_ "SPN" SG_ 2566770174 RearWiperSwitch 2865;
BA_ "SPN" SG_ 2566770942 EngineIntakeManifold2Pressure 3562;
BA_ "SPN" SG_ 2566770942 EngnArFltr2DffrntlPrssr 2809;
BA_ "SPN" SG_ 2566770942 EngnArFltr3DffrntlPrssr 2810;
BA_ "SPN" SG_ 2566770942 EngnArFltr4DffrntlPrssr 2811;
BA_ "SPN" SG_ 2566770942 EngnIntkMnfld1AsltPrssr 3563;
BA_ "SPN" SG_ 2566770942 EngnIntkMnfld1AsltPrssrHghRsltn 4817;
BA_ "SPN" SG_ 2566770942 EngnIntkMnfld2AsltPrssr 5422;
BA_ "SPN" SG_ 2566771454 DataMemoryUsage 2802;
BA_ "SPN" SG_ 2566771454 KeepAliveBatteryConsumption 2803;
BA_ "SPN" SG_ 2566771710 EngnTrhrgr1CmprssrOtltTmprtr 2629;
BA_ "SPN" SG_ 2566771710 EngnTrhrgr2CmprssrOtltTmprtr 2799;
BA_ "SPN" SG_ 2566771710 EngnTrhrgr3CmprssrOtltTmprtr 2800;
BA_ "SPN" SG_ 2566771710 EngnTrhrgr4CmprssrOtltTmprtr 2801;
BA_ "SPN" SG_ 2566771966 FfthWhlRlsCntrlSrtLkt 3315;
BA_ "SPN" SG_ 2566771966 FifthWheelReleaseControl 3314;
BA_ "SPN" SG_ 2566771966 TransferCaseSelectorSwitch 2796;
BA_ "SPN" SG_ 2566771966 TransmissionOilLevelRequest 3809;
BA_ "SPN" SG_ 2566771966 VehicleTrailerStatus 7711;
BA_ "SPN" SG_ 2566771966 AftrtrtmntSCRDsngMdCmmnd 9175;
BA_ "SPN" SG_ 2566771966 MomentaryOperatorKeySwitch 9842;
BA_ "SPN" SG_ 2566771966 OperatorKeyDetected 10144;
BA_ "SPN" SG_ 2566771966 OperatorKeySwitchAccessoryPower 3996;
BA_ "SPN" SG_ 2566771966 OperatorKeySwitchIgnitionPower 10145;
BA_ "SPN" SG_ 2566771966 OperatorKeySwitchStart 10146;
BA_ "SPN" SG_ 2566771966 OprtrKSwthDldBttrOff 10147;
BA_ "SPN" SG_ 2566771966 HornSwitch 2641;
BA_ "SPN" SG_ 2566771966 EngineAirShutoffTestSwitch 13363;
BA_ "SPN" SG_ 2566771966 EngineAirShutoffManualSwitch 13364;
BA_ "SPN" SG_ 2566772222 EngineFuelControlMode 5323;
BA_ "SPN" SG_ 2566772222 EngnExhstGsRrltn1Vlv1Cntrl1 2791;
BA_ "SPN" SG_ 2566772222 EngnTrhrgr1ClltdTrnIntkTmprtr 2789;
BA_ "SPN" SG_ 2566772222 EngnTrhrgr1ClltdTrnOtltTmprtr 2790;
BA_ "SPN" SG_ 2566772222 EngnVrlGmtrTrhrgr1CntrlMd 5457;
BA_ "SPN" SG_ 2566772222 EngnVrlGmtrTrhrgrVGT1AttrPstn 2795;
BA_ "SPN" SG_ 2566772222 EVGtTVGTACtStVv 2792;
BA_ "SPN" SG_ 2566774014 EngineMarineOperatingModeStatus 7845;
BA_ "SPN" SG_ 2566774014 EngnThrttlSnhrnztnMdStts 2615;
BA_ "SPN" SG_ 2566774014 SlowVesselModeStatus 2617;
BA_ "SPN" SG_ 2566774014 TrollingModeStatus 2616;
BA_ "SPN" SG_ 2566775038 BrmtrAsltPrssrHghRsltn 5685;
BA_ "SPN" SG_ 2566775038 CalculatedAmbientAirTemperature 5581;
BA_ "SPN" SG_ 2566775038 SolarIntensityPercent 2610;
BA_ "SPN" SG_ 2566775038 SolarSensorMaximum 2611;
BA_ "SPN" SG_ 2566775038 SpecificHumidity 4490;
BA_ "SPN" SG_ 2566775294 AirConditionerCompressorStatus 7853;
BA_ "SPN" SG_ 2566775294 CACRfrgrntCmprssrOtltPrssr 2609;
BA_ "SPN" SG_ 2566775550 ArSspnsnSpplPrssrRqst 2608;
BA_ "SPN" SG_ 2566775550 AxlrEqpmntSpplPrssrRqst 2607;
BA_ "SPN" SG_ 2566775550 PneumaticSupplyPressureRequest 2603;
BA_ "SPN" SG_ 2566775550 PrkngndrTrlrArPrssrRqst 2604;
BA_ "SPN" SG_ 2566775550 PwrtrnCrtArSpplPrssrRqst 6306;
BA_ "SPN" SG_ 2566775550 SrvBrkArPrssrRqstCrt1 2605;
BA_ "SPN" SG_ 2566775550 SrvBrkArPrssrRqstCrt2 2606;
BA_ "SPN" SG_ 2566775806 TravelVelocityControlPosition 2601;
BA_ "SPN" SG_ 2566776062 PayloadCapacityPercentage 6854;
BA_ "SPN" SG_ 2566776062 PayloadCarryBackWeight 6853;
BA_ "SPN" SG_ 2566776062 PayloadPercentage 2600;
BA_ "SPN" SG_ 2566776062 PayloadWeight 6851;
BA_ "SPN" SG_ 2566776062 PayloadWeightConfidence 6852;
BA_ "SPN" SG_ 2566776318 AppliedVehicleSpeedLimit 2595;
BA_ "SPN" SG_ 2566776318 MaximumVehicleSpeedLimit1 2588;
BA_ "SPN" SG_ 2566776318 MaximumVehicleSpeedLimit2 2589;
BA_ "SPN" SG_ 2566776318 MaximumVehicleSpeedLimit3 2590;
BA_ "SPN" SG_ 2566776318 MaximumVehicleSpeedLimit4 2591;
BA_ "SPN" SG_ 2566776318 MaximumVehicleSpeedLimit5 2592;
BA_ "SPN" SG_ 2566776318 MaximumVehicleSpeedLimit6 2593;
BA_ "SPN" SG_ 2566776318 MaximumVehicleSpeedLimit7 2594;
BA_ "SPN" SG_ 2566785022 EngnExhstMnfldBnk1Tmprtr1 2434;
BA_ "SPN" SG_ 2566785022 EngnExhstMnfldBnk1Tmprtr2 5970;
BA_ "SPN" SG_ 2566785022 EngnExhstMnfldBnk2Tmprtr1 2433;
BA_ "SPN" SG_ 2566785022 EngnExhstMnfldBnk2Tmprtr2 5969;
BA_ "SPN" SG_ 2566799614 AlternateBeamHeadLightData 2352;
BA_ "SPN" SG_ 2566799614 BackUpLightandAlarmHorn 2392;
BA_ "SPN" SG_ 2566799614 CenterStopLight 2376;
BA_ "SPN" SG_ 2566799614 HighBeamHeadLightData 2348;
BA_ "SPN" SG_ 2566799614 ImplementClearanceLight 2384;
BA_ "SPN" SG_ 2566799614 ImplementLeftFacingWorkLight 2400;
BA_ "SPN" SG_ 2566799614 ImplementLeftForwardWorkLight 2598;
BA_ "SPN" SG_ 2566799614 ImplementMarkerLight 2380;
BA_ "SPN" SG_ 2566799614 ImplementOEMOption1Light 2396;
BA_ "SPN" SG_ 2566799614 ImplementOEMOption2Light 2398;
BA_ "SPN" SG_ 2566799614 ImplementRearWorkLight 2394;
BA_ "SPN" SG_ 2566799614 ImplementRightFacingWorkLight 2407;
BA_ "SPN" SG_ 2566799614 ImplementRightForwardWorkLight 2402;
BA_ "SPN" SG_ 2566799614 LeftStopLight 2372;
BA_ "SPN" SG_ 2566799614 LeftTurnSignalLights 2368;
BA_ "SPN" SG_ 2566799614 LowBeamHeadLightData 2350;
BA_ "SPN" SG_ 2566799614 RearFogLights 2390;
BA_ "SPN" SG_ 2566799614 RightStopLight 2374;
BA_ "SPN" SG_ 2566799614 RightTurnSignalLights 2370;
BA_ "SPN" SG_ 2566799614 RotatingBeaconLight 2386;
BA_ "SPN" SG_ 2566799614 RunningLight 2404;
BA_ "SPN" SG_ 2566799614 TractorClearanceLight 2382;
BA_ "SPN" SG_ 2566799614 TractorFrontFogLights 2388;
BA_ "SPN" SG_ 2566799614 TractorMarkerLight 2378;
BA_ "SPN" SG_ 2566799614 TractorRearLowMountedWorkLights 2360;
BA_ "SPN" SG_ 2566799614 TractorSideLowMountedWorkLights 2364;
BA_ "SPN" SG_ 2566799614 TrtrFrntHghMntdWrkLghts 2356;
BA_ "SPN" SG_ 2566799614 TrtrFrntLwMntdWrkLghts 2354;
BA_ "SPN" SG_ 2566799614 TrtrRrHghMntdWrkLghts 2362;
BA_ "SPN" SG_ 2566799614 TrtrSdHghMntdWrkLghts 2366;
BA_ "SPN" SG_ 2566799614 TrtrUndrsdMntdWrkLghts 2358;
BA_ "SPN" SG_ 2566802174 ActiveShiftConsoleIndicator 2945;
BA_ "SPN" SG_ 2566802174 TransmissionEngineCrankEnable 2900;
BA_ "SPN" SG_ 2566802174 TransmissionManualModeIndicator 8291;
BA_ "SPN" SG_ 2566802174 TransmissionMode10Indicator 6568;
BA_ "SPN" SG_ 2566802174 TransmissionMode1Indicator 2536;
BA_ "SPN" SG_ 2566802174 TransmissionMode2Indicator 2537;
BA_ "SPN" SG_ 2566802174 TransmissionMode3Indicator 2538;
BA_ "SPN" SG_ 2566802174 TransmissionMode4Indicator 2539;
BA_ "SPN" SG_ 2566802174 TransmissionMode5Indicator 4250;
BA_ "SPN" SG_ 2566802174 TransmissionMode6Indicator 4251;
BA_ "SPN" SG_ 2566802174 TransmissionMode7Indicator 4252;
BA_ "SPN" SG_ 2566802174 TransmissionMode8Indicator 4253;
BA_ "SPN" SG_ 2566802174 TransmissionMode9Indicator 6567;
BA_ "SPN" SG_ 2566802174 TransmissionServiceIndicator 4178;
BA_ "SPN" SG_ 2566802174 TransmissionWarningIndicator 5344;
BA_ "SPN" SG_ 2566802174 TrnsmssnArSpplPrssrIndtr 6566;
BA_ "SPN" SG_ 2566802174 TrnsmssnAtNtrlMnlRtrnStt 7696;
BA_ "SPN" SG_ 2566802174 TrnsmssnCrrntRngDsplBlnkStt 4176;
BA_ "SPN" SG_ 2566802174 TrnsmssnRdfrBrkRls 3086;
BA_ "SPN" SG_ 2566802174 TrnsmssnRqstdGrFdk 3289;
BA_ "SPN" SG_ 2566802174 TrnsmssnRqstdRngDsplBlnkStt 1850;
BA_ "SPN" SG_ 2566802174 TrnsmssnRqstdRngDsplFlshStt 1849;
BA_ "SPN" SG_ 2566802174 TrnsmssnRvrsGrShftInhtStts 4261;
BA_ "SPN" SG_ 2566802174 TrnsmssnShftInhtIndtr 1851;
BA_ "SPN" SG_ 2566802174 TrnsmssnLdRdtnIndtr 11747;
BA_ "SPN" SG_ 2566802174 TrnsmssnPrDfndRngLmtIndtr 11748;
BA_ "SPN" SG_ 2566802174 TransmissionCoastModeIndicator 11749;
BA_ "SPN" SG_ 2566802430 TransmissionReferenceTorque 7778;
BA_ "SPN" SG_ 2566802430 TransmissionTorqueLimit 1845;
BA_ "SPN" SG_ 2566802430 TrnsmssnCmmntnsFlrIdlTrqLmt 7827;
BA_ "SPN" SG_ 2566802686 BlackOutBrakeStopLampSelect 1841;
BA_ "SPN" SG_ 2566802686 BlackOutWorkLampSelect 1842;
BA_ "SPN" SG_ 2566802686 ConvoyDrivingLampSelect 1837;
BA_ "SPN" SG_ 2566802686 ConvoyLampSelect 1838;
BA_ "SPN" SG_ 2566802686 FrontBlackOutMarkerLampSelect 1839;
BA_ "SPN" SG_ 2566802686 NightVisionIlluminatorSelect 1843;
BA_ "SPN" SG_ 2566802686 OprtrsBlkOtIntnstSltn 1844;
BA_ "SPN" SG_ 2566802686 RearBlackOutMarkerSelect 1840;
BA_ "SPN" SG_ 2566803198 Positionofdoors 1821;
BA_ "SPN" SG_ 2566803198 RampWheelChairLiftPosition 1820;
BA_ "SPN" SG_ 2566803198 Status2ofdoors 3411;
BA_ "SPN" SG_ 2566803454 ROPBrakeControlactive 1818;
BA_ "SPN" SG_ 2566803454 ROPEngineControlactive 1816;
BA_ "SPN" SG_ 2566803454 TrailerVDCActive 5624;
BA_ "SPN" SG_ 2566803454 VDCbrakelightrequest 1815;
BA_ "SPN" SG_ 2566803454 VDCFullyOperational 1814;
BA_ "SPN" SG_ 2566803454 VDCInformationSignal 1813;
BA_ "SPN" SG_ 2566803454 YCBrakeControlactive 1819;
BA_ "SPN" SG_ 2566803454 YCEngineControlactive 1817;
BA_ "SPN" SG_ 2566803710 SLIBattery1Temperature 1800;
BA_ "SPN" SG_ 2566803710 SLIBattery2Temperature 1801;
BA_ "SPN" SG_ 2566803710 SLIBattery3Temperature 2779;
BA_ "SPN" SG_ 2566803710 SLIBattery4Temperature 2780;
BA_ "SPN" SG_ 2566803966 ACCusagedemand 5023;
BA_ "SPN" SG_ 2566803966 RequestedACCDistanceMode 1799;
VAL_ 2566758142 Aftertreatment2AirSystemRelay 3 "notAvailable" 2 "reservedForSAEAssignment" 1 "active" 0 "notActive" ;
VAL_ 2566758142 Aftertreatment2PurgeAirActuator 3 "notAvailable" 2 "reservedForSAEAssignment" 1 "active" 0 "notActive" ;
VAL_ 2566758398 Aftertreatment1AirSystemRelay 3 "notAvailable" 2 "reservedForSAEAssignment" 1 "active" 0 "notActive" ;
VAL_ 2566758398 Aftertreatment1PurgeAirActuator 3 "notAvailable" 2 "reservedForSAEAssignment" 1 "active" 0 "notActive" ;
VAL_ 2566759678 AtleastonePTOengaged 3 "NotAvailable" 2 "Error" 1 "AtLeastOnePTODriveIsEngaged" 0 "NoPTODriveIsEngaged" ;
VAL_ 2566759934 EnableStatusofDoor1 3 "notAvailable" 2 "error" 1 "doorEnabled" 0 "doorDisabled" ;
VAL_ 2566759934 EnableStatusofDoor10 3 "notAvailable" 2 "error" 1 "doorEnabled" 0 "doorDisabled" ;
VAL_ 2566759934 EnableStatusofDoor2 3 "notAvailable" 2 "error" 1 "doorEnabled" 0 "doorDisabled" ;
VAL_ 2566759934 EnableStatusofDoor3 3 "notAvailable" 2 "error" 1 "doorEnabled" 0 "doorDisabled" ;
VAL_ 2566759934 EnableStatusofDoor4 3 "notAvailable" 2 "error" 1 "doorEnabled" 0 "doorDisabled" ;
VAL_ 2566759934 EnableStatusofDoor5 3 "notAvailable" 2 "error" 1 "doorEnabled" 0 "doorDisabled" ;
VAL_ 2566759934 EnableStatusofDoor6 3 "notAvailable" 2 "error" 1 "doorEnabled" 0 "doorDisabled" ;
VAL_ 2566759934 EnableStatusofDoor7 3 "notAvailable" 2 "error" 1 "doorEnabled" 0 "doorDisabled" ;
VAL_ 2566759934 EnableStatusofDoor8 3 "notAvailable" 2 "error" 1 "doorEnabled" 0 "doorDisabled" ;
VAL_ 2566759934 EnableStatusofDoor9 3 "notAvailable" 2 "error" 1 "doorEnabled" 0 "doorDisabled" ;
VAL_ 2566759934 LockStatusofDoor1 3 "notAvailable" 2 "error" 1 "locked" 0 "unlocked" ;
VAL_ 2566759934 LockStatusofDoor10 3 "notAvailable" 2 "error" 1 "locked" 0 "unlocked" ;
VAL_ 2566759934 LockStatusofDoor2 3 "notAvailable" 2 "error" 1 "locked" 0 "unlocked" ;
VAL_ 2566759934 LockStatusofDoor3 3 "notAvailable" 2 "error" 1 "locked" 0 "unlocked" ;
VAL_ 2566759934 LockStatusofDoor4 3 "notAvailable" 2 "error" 1 "locked" 0 "unlocked" ;
VAL_ 2566759934 LockStatusofDoor5 3 "notAvailable" 2 "error" 1 "locked" 0 "unlocked" ;
VAL_ 2566759934 LockStatusofDoor6 3 "notAvailable" 2 "error" 1 "locked" 0 "unlocked" ;
VAL_ 2566759934 LockStatusofDoor7 3 "notAvailable" 2 "error" 1 "locked" 0 "unlocked" ;
VAL_ 2566759934 LockStatusofDoor8 3 "notAvailable" 2 "error" 1 "locked" 0 "unlocked" ;
VAL_ 2566759934 LockStatusofDoor9 3 "notAvailable" 2 "error" 1 "locked" 0 "unlocked" ;
VAL_ 2566759934 OpenStatusofDoor1 3 "notAvailable" 2 "error" 1 "doorOpened" 0 "doorClosed" ;
VAL_ 2566759934 OpenStatusofDoor10 3 "notAvailable" 2 "error" 1 "doorOpened" 0 "doorClosed" ;
VAL_ 2566759934 OpenStatusofDoor2 3 "notAvailable" 2 "error" 1 "doorOpened" 0 "doorClosed" ;
VAL_ 2566759934 OpenStatusofDoor3 3 "notAvailable" 2 "error" 1 "doorOpened" 0 "doorClosed" ;
VAL_ 2566759934 OpenStatusofDoor4 3 "notAvailable" 2 "error" 1 "doorOpened" 0 "doorClosed" ;
VAL_ 2566759934 OpenStatusofDoor5 3 "notAvailable" 2 "error" 1 "doorOpened" 0 "doorClosed" ;
VAL_ 2566759934 OpenStatusofDoor6 3 "notAvailable" 2 "error" 1 "doorOpened" 0 "doorClosed" ;
VAL_ 2566759934 OpenStatusofDoor7 3 "notAvailable" 2 "error" 1 "doorOpened" 0 "doorClosed" ;
VAL_ 2566759934 OpenStatusofDoor8 3 "notAvailable" 2 "error" 1 "doorOpened" 0 "doorClosed" ;
VAL_ 2566759934 OpenStatusofDoor9 3 "notAvailable" 2 "error" 1 "doorOpened" 0 "doorClosed" ;
VAL_ 2566760702 NetworkAntennaStatus2 1 "On" 0 "Off" ;
VAL_ 2566760702 NetworkServiceStatus2 1 "RoamingService" 0 "LocalService" ;
VAL_ 2566760702 NetworkTransceiverStatus2 1 "On" 0 "Off" ;
VAL_ 2566760958 NetworkAntennaStatus1 1 "On" 0 "Off" ;
VAL_ 2566760958 NetworkServiceStatus1 1 "RoamingService" 0 "LocalService" ;
VAL_ 2566760958 NetworkTransceiverStatus1 1 "On" 0 "Off" ;
VAL_ 2566762238 FifthWheelErrorStatus 15 "NotAvailable" 9 "Kingpin_LockOpen" 8 "KingpinMissingMoreThan5Seconds" 7 "CouplingTimingError" 6 "CouplingSequenceError_Kingpin" 5 "CouplingSequenceError" 14 "NotUsed" 2 "Kingpin_LocksOpenAtStartup" 1 "LocksClosed_NoKingpinAtStartup" 0 "ImproperCouple" ;
VAL_ 2566762238 FifthWheelSliderLockIndicator 3 "NotAvailable" 2 "Error" 1 "Locked" 0 "NotLocked" ;
VAL_ 2566765310 FareboxAlarmIdentifier 97 "1111111AgencyDefined" 26 "1100000ReservedToBeAssigned" 25 "MaintenanceAccessOutOfService" 24 "MntnncAccssInSrvcCnsdrdAnAlrmCn" 23 "PaperCurrencyJamCleared" 22 "PaperCurrencyJam" 21 "Pass_TransferJamCleared" 20 "Pass_TransferJam" 19 "FareboxResetToAutomaticMode" 18 "FareboxSetInManualBypass" 17 "CoinDejamOperated" 16 "Card_PassBoxFull" 15 "Card_PassBoxLessThan75Full" 14 "Card_PassBox75Full" 13 "CurrencyBoxFull" 12 "CurrencyBoxLessThan75Full" 11 "CurrencyBox75Full" 10 "CoinboxFull" 9 "Coinbox75Full" 8 "InsufficientFareAccepted" 7 "CshbxOpndInSrvcCnsdrdAnAlrmCndt" 6 "CashboxDoorTimeout" 5 "CashboxRestored" 4 "CashboxRemoved" 3 "ProbeCompleted" 2 "ProbeStarted" 1 "VoltageRestored" 0 "VoltageDropout" ;
VAL_ 2566765310 FareboxEmergencyStatus 3 "NotAvailable" 2 "ErrorCondition" 1 "EmergencyCondition" 0 "NonemergencyCondition" ;
VAL_ 2566765566 PaymentDetails 11 "1111AgencyDefined" 6 "1010ReservedForAssignment" 5 "Card" 4 "Pass" 3 "Ticket" 2 "Token" 1 "Cash" 0 "NotAnUpgrade" ;
VAL_ 2566765566 TransactionType 12 "1111AgencyDefined" 8 "1011ReservedForAssignment" 7 "Free" 6 "Transfer" 5 "Permit" 4 "Card" 3 "Pass" 2 "Ticket" 1 "Token" 0 "Cash" ;
VAL_ 2566765566 TransferType 6 "11111AgencyDefined" 5 "Out" 4 "In" 3 "West" 2 "East" 1 "South" 0 "North" ;
VAL_ 2566765566 TypeofFare 11 "1111AgencyDefined" 7 "1010ReservedForAssignment" 6 "PassB" 5 "PassA" 4 "TicketB" 3 "TicketA" 2 "TokenB" 1 "TokenA" 0 "Cash_NoDetail" ;
VAL_ 2566765566 TypeofService 2 "111AgencyDefined" 1 "ExpressService" 0 "LocalService" ;
VAL_ 2566765822 FareboxServiceStatus 3 "NotAvailable" 2 "ErrorCondition" 1 "FareboxInService" 0 "FareboxOutOfService" ;
VAL_ 2566765822 FarePresets 16 "to11111111ReservedForAssignment" 0 "to00001111AgencyDefined" ;
VAL_ 2566765822 TripDirection 6 "1111AgencyDefined" 5 "Out" 4 "In" 3 "West" 2 "East" 1 "South" 0 "North" ;
VAL_ 2566765822 TripStatus 6 "LayoverEnd" 5 "LayoverStart" 2 "TripEnd" 1 "TripStart" 7 "Undefined" ;
VAL_ 2566766078 RangeCodeEnable 3 "NotAvailable" 2 "ErrorCondition" 1 "RangeCodeUsedForInterleavedData" 0 "RngCdeNotUsedForInterleavedData" ;
VAL_ 2566766078 TransitDoorEnable 3 "NotAvailable" 2 "ErrorCondition" 1 "TrnstDrSttsWllOvrrdStrbActvtion" 0 "IgnoreTransitDoorStatus" ;
VAL_ 2566766078 TransitRouteIDUsage 3 "NotAvailable" 2 "ErrorCondition" 1 "TrnstRtIDUsedForInterleavedData" 0 "TrnstRtIDNtUsdFrInterleavedData" ;
VAL_ 2566766846 SilentAlarmStatus 3 "NotAvailable" 2 "ErrorCondition" 1 "On" 0 "Off" ;
VAL_ 2566766846 TransitRunStatus 3 "NotAvailable" 2 "ErrorCondition" 1 "On" 0 "Off" ;
VAL_ 2566766846 TypeofPassengerCount 1 "BoardingPassenger" 0 "AbsPassengerCount" 4 "Exiting Passenger (second passenger stream)" 3 "Boarding Passenger (second passenger stream)" 2 "Exiting Passenger" ;
VAL_ 2566766846 VehicleUseStatus 3 "NotAvailable" 2 "ErrorCondition" 1 "UnauthorizedUse" 0 "NormalUse" ;
VAL_ 2566767870 FoundationBrakeUse 3 "NotAvailable" 2 "Reserved" 1 "FoundationBrakesInUse" 0 "FoundationBrakesNotInUse" ;
VAL_ 2566767870 Haltbrakemode 7 "NotAvailable" 6 "Reserved" 3 "101NotDefined" 2 "ActiveButNotFunctioningProperly" 1 "Active" 0 "Inactive" ;
VAL_ 2566767870 Hillholdermode 7 "NotAvailable" 6 "HillHolderNotFunctional" 3 "101Reserved" 2 "ActvBtWllChngTInctvInAShortTime" 1 "Active" 0 "Inactive" ;
VAL_ 2566767870 XBRSystemState 3 "NotAvailable" 2 "NoExtlBrakeDemandWillBeAccepted" 1 "OnlyExtlBrkDmndOfHghstXBRPrrtyW" 0 "AnyExtlBrkeDemandWillBeAccepted" ;
VAL_ 2566770174 FrontNonoperatorWasherSwitch 7 "NotAvailable" 4 "110Reserved" 3 "High" 2 "Medium" 1 "Low" 0 "Off" ;
VAL_ 2566770174 FrontNonoperatorWiperSwitch 15 "NotAvailable" 7 "1110Reserved" 6 "Mist" 5 "Delayed2" 4 "Delayed1" 3 "High" 2 "Medium" 1 "Low" 0 "Off" ;
VAL_ 2566770174 FrontOperatorWasherSwitch 7 "NotAvailable" 4 "110Reserved" 3 "High" 2 "Medium" 1 "Low" 0 "Off" ;
VAL_ 2566770174 FrontOperatorWiperSwitch 7 "1110Reserved" 6 "Mist" 5 "Delayed2" 4 "Delayed1" 2 "Medium" 15 "NotAvailable" 3 "High" 1 "Low" 0 "Off" ;
VAL_ 2566770174 RearWasherFunction 7 "NotAvailable" 4 "110Reserved" 3 "High" 2 "Medium" 1 "Low" 0 "Off" ;
VAL_ 2566770174 RearWiperSwitch 7 "1110Reserved" 6 "Mist" 5 "Delayed2" 4 "Delayed1" 2 "Medium" 15 "NotAvailable" 3 "High" 1 "Low" 0 "Off" ;
VAL_ 2566771966 TransferCaseSelectorSwitch 7 "NotAvailable" 5 "ReservedForSAEAssignment" 4 "4WheelLow" 0 "2WheelHigh" 6 "ErrorIndicator" 3 "2WheelLow" 2 "Neutral" 1 "4WheelHigh" ;
VAL_ 2566774014 SlowVesselModeStatus 3 "TakeNoAction" 2 "Reserved" 1 "SlowVesselModeIsACTIVE" 0 "SlowVesselModeIsOFF" ;
VAL_ 2566774014 TrollingModeStatus 3 "TakeNoAction" 2 "Reserved" 1 "TrollingModeIsACTIVE" 0 "TrollingModeIsOFF" ;
VAL_ 2566799614 BackUpLightandAlarmHorn 3 "NotAvailable" 2 "FaultDetected" 1 "Activated" 0 "Deactivated" ;
VAL_ 2566799614 CenterStopLight 3 "NotAvailable" 2 "FaultDetected" 1 "Activated" 0 "Deactivated" ;
VAL_ 2566799614 HighBeamHeadLightData 3 "NotAvailable" 2 "FaultDetected" 1 "Activated" 0 "Deactivated" ;
VAL_ 2566799614 ImplementClearanceLight 3 "NotAvailable" 2 "FaultDetected" 1 "Activated" 0 "Deactivated" ;
VAL_ 2566799614 ImplementMarkerLight 3 "NotAvailable" 2 "FaultDetected" 1 "Activated" 0 "Deactivated" ;
VAL_ 2566799614 ImplementOEMOption1Light 3 "NotAvailable" 2 "FaultDetected" 1 "Activated" 0 "Deactivated" ;
VAL_ 2566799614 ImplementOEMOption2Light 3 "NotAvailable" 2 "FaultDetected" 1 "Activated" 0 "Deactivated" ;
VAL_ 2566799614 ImplementRearWorkLight 3 "NotAvailable" 2 "FaultDetected" 1 "Activated" 0 "Deactivated" ;
VAL_ 2566799614 ImplementRightFacingWorkLight 3 "NotAvailable" 2 "FaultDetected" 1 "Activated" 0 "Deactivated" ;
VAL_ 2566799614 ImplementRightForwardWorkLight 3 "NotAvailable" 2 "FaultDetected" 1 "Activated" 0 "Deactivated" ;
VAL_ 2566799614 LeftStopLight 3 "NotAvailable" 2 "FaultDetected" 1 "Activated" 0 "Deactivated" ;
VAL_ 2566799614 LeftTurnSignalLights 3 "NotAvailable" 2 "FaultDetected" 1 "Activated" 0 "Deactivated" ;
VAL_ 2566799614 LowBeamHeadLightData 3 "NotAvailable" 2 "FaultDetected" 1 "Activated" 0 "Deactivated" ;
VAL_ 2566799614 RearFogLights 3 "NotAvailable" 2 "FaultDetected" 1 "Activated" 0 "Deactivated" ;
VAL_ 2566799614 RightStopLight 3 "NotAvailable" 2 "FaultDetected" 1 "Activated" 0 "Deactivated" ;
VAL_ 2566799614 RightTurnSignalLights 3 "NotAvailable" 2 "FaultDetected" 1 "Activated" 0 "Deactivated" ;
VAL_ 2566799614 RotatingBeaconLight 3 "NotAvailable" 2 "FaultDetected" 1 "Activated" 0 "Deactivated" ;
VAL_ 2566799614 RunningLight 3 "NotAvailable" 2 "FaultDetected" 1 "Activated" 0 "Deactivated" ;
VAL_ 2566799614 TractorClearanceLight 3 "NotAvailable" 2 "FaultDetected" 1 "Activated" 0 "Deactivated" ;
VAL_ 2566799614 TractorFrontFogLights 3 "NotAvailable" 2 "FaultDetected" 1 "Activated" 0 "Deactivated" ;
VAL_ 2566799614 TractorMarkerLight 3 "NotAvailable" 2 "FaultDetected" 1 "Activated" 0 "Deactivated" ;
VAL_ 2566799614 TractorRearLowMountedWorkLights 3 "NotAvailable" 2 "FaultDetected" 1 "Activated" 0 "Deactivated" ;
VAL_ 2566799614 TractorSideLowMountedWorkLights 3 "NotAvailable" 2 "FaultDetected" 1 "Activated" 0 "Deactivated" ;
VAL_ 2566802174 ActiveShiftConsoleIndicator 3 "NotAvailable" 2 "Reserved" 1 "SecondShiftConsoleIsActive" 0 "PrimaryShiftConsoleIsActive" ;
VAL_ 2566802686 BlackOutWorkLampSelect 3 "NotSupported" 2 "Reserved" 1 "On" 0 "Off" ;
VAL_ 2566802686 ConvoyDrivingLampSelect 3 "NotSupported" 2 "Reserved" 1 "On" 0 "Off" ;
VAL_ 2566802686 ConvoyLampSelect 3 "NotSupported" 2 "Reserved" 1 "On" 0 "Off" ;
VAL_ 2566802686 FrontBlackOutMarkerLampSelect 3 "NotSupported" 2 "Reserved" 1 "On" 0 "Off" ;
VAL_ 2566802686 NightVisionIlluminatorSelect 3 "NotSupported" 2 "Reserved" 1 "On" 0 "Off" ;
VAL_ 2566802686 RearBlackOutMarkerSelect 3 "NotSupported" 2 "Reserved" 1 "On" 0 "Off" ;
VAL_ 2566803198 Status2ofdoors 3 "notAvailable" 2 "error" 1 "atLeast1BusDoorEnabled" 0 "allBusDoorsAreDisabled" ;
VAL_ 2566803454 VDCFullyOperational 3 "DontCare_TakeNoAction" 2 "Reserved" 1 "FullyOperational" 0 "NotFullyOperational" ;
VAL_ 2566803454 VDCInformationSignal 3 "DontCare_TakeNoAction" 2 "Reserved" 1 "On" 0 "Off" ;
VAL_ 2566803966 ACCusagedemand 3 "dontCare" 2 "reserved" 1 "drvrDmndFrUsngACCDstncKpingCtrl" 0 "drvrDmndFrNtUsngACCDstncKpngCtr" ;
VAL_ 2566757374 Aftrtrtmnt1DslExhstFldPrprt 15 "NotAvailable" 14 "ErrrDtctdWthUrRgntTypeDetection" 13 "NtAblTDtrmneCatalystReagentType" 5 "to1100ReservedForSAEAssignment" 3 "CatalystReagentIsProperMixture" 2 "CatalystReagentIsDiesel" 1 "CtlystRgntIsUrCncntrationTooLow" 0 "CtlystRgntIsUrCncntrtionTooHigh" ;
VAL_ 2566758142 Aftrtrtmnt2AtmztnArAttr 3 "notAvailable" 2 "reservedForSAEAssignment" 1 "active" 0 "notActive" ;
VAL_ 2566758142 Aftrtrtmnt2ArEnlAttr 3 "notAvailable" 2 "reservedForSAEAssignment" 1 "active" 0 "notActive" ;
VAL_ 2566758398 Aftrtrtmnt1AtmztnArAttr 3 "notAvailable" 2 "reservedForSAEAssignment" 1 "active" 0 "notActive" ;
VAL_ 2566758398 Aftrtrtmnt1ArEnlAttr 3 "notAvailable" 2 "reservedForSAEAssignment" 1 "active" 0 "notActive" ;
VAL_ 2566758654 Aftrtrtmnt2FlDrnAttr 3 "notAvailable" 2 "reservedForSAEAssignment" 1 "active" 0 "notActive" ;
VAL_ 2566758654 Aftertreatment2Ignition 3 "notAvailable" 2 "reservedForSAEAssignment" 1 "active" 0 "notActive" ;
VAL_ 2566758654 Aftrtrtmnt2RgnrtnStts 3 "notAvailable" 2 "reservedForSAEAssignment" 1 "active" 0 "notActive" ;
VAL_ 2566758654 Aftrtrtmnt2FlEnlAttr 3 "notAvailable" 2 "reservedForSAEAssignment" 1 "active" 0 "notActive" ;
VAL_ 2566758910 Aftrtrtmnt1FlDrnAttr 3 "notAvailable" 2 "reservedForSAEAssignment" 1 "active" 0 "notActive" ;
VAL_ 2566758910 Aftertreatment1Ignition 3 "notAvailable" 2 "reservedForSAEAssignment" 1 "active" 0 "notActive" ;
VAL_ 2566758910 Aftrtrtmnt1RgnrtnStts 3 "notAvailable" 2 "reservedForSAEAssignment" 1 "active" 0 "notActive" ;
VAL_ 2566758910 Aftrtrtmnt1FlEnlAttr 3 "notAvailable" 2 "reservedForSAEAssignment" 1 "active" 0 "notActive" ;
VAL_ 2566759678 EnlSwthTrnsfrstptshftPTO 3 "NotAvailable" 2 "Error" 1 "EnblSwtchOffPTOOperationDesired" 0 "EnblSwtchOffPTOOprtonNotDesired" ;
VAL_ 2566759678 EnlSwthTrnsmssntptshftPTO 3 "NotAvailable" 2 "Error" 1 "EnblSwtchOffPTOOperationDesired" 0 "EnblSwtchOffPTOOprtonNotDesired" ;
VAL_ 2566759678 EnlSwthTrnsmssnnptshftPTO2 3 "NotAvailable" 2 "Error" 1 "EnblSwtchOffPTOOperationDesired" 0 "EnblSwtchOffPTOOprtonNotDesired" ;
VAL_ 2566759678 EnlSwthTrnsmssnnptshftPTO1 3 "NotAvailable" 2 "Error" 1 "EnblSwtchOffPTOOperationDesired" 0 "EnblSwtchOffPTOOprtonNotDesired" ;
VAL_ 2566759678 EnableSwitchPTOEngineFlywheel 3 "NotAvailable" 2 "Error" 1 "EnblSwitchOnPTOOperationDesired" 0 "EnblSwtchOffPTOOprtonNotDesired" ;
VAL_ 2566759678 EnlSwthPTOEngnAssrDrv1 3 "NotAvailable" 2 "Error" 1 "EnblSwitchOnPTOOperationDesired" 0 "EnblSwtchOffPTOOprtonNotDesired" ;
VAL_ 2566759678 EnlSwthPTOEngnAssrDrv2 3 "NotAvailable" 2 "Error" 1 "EnblSwitchOnPTOOperationDesired" 0 "EnblSwtchOffPTOOprtonNotDesired" ;
VAL_ 2566759678 EnggmntCnsntTrnsfrstptshftPTO 3 "NotAvailable" 2 "Error" 1 "CnsentGivenPTODriveMayBeEngaged" 0 "CnsntNtGvnPTODrvShldNtBeEngaged" ;
VAL_ 2566759678 EnggmntCnsntTrnsmssntptshftPTO 3 "NotAvailable" 2 "Error" 1 "CnsentGivenPTODriveMayBeEngaged" 0 "CnsntNtGvnPTODrvShldNtBeEngaged" ;
VAL_ 2566759678 EnggmntCnsntTrnsmssnnptshftPTO2 3 "NotAvailable" 2 "Error" 1 "CnsentGivenPTODriveMayBeEngaged" 0 "CnsntNtGvnPTODrvShldNtBeEngaged" ;
VAL_ 2566759678 EnggmntCnsntTrnsmssnnptshftPTO1 3 "NotAvailable" 2 "Error" 1 "CnsentGivenPTODriveMayBeEngaged" 0 "CnsntNtGvnPTODrvShldNtBeEngaged" ;
VAL_ 2566759678 EnggmntCnsntPTOEngnFlwhl 3 "NotAvailable" 2 "Error" 1 "CnsentGivenPTODriveMayBeEngaged" 0 "CnsntNtGvnPTODrvMayNotBeEngaged" ;
VAL_ 2566759678 EnggmntCnsntPTOEngnAssrDrv1 3 "NotAvailable" 2 "Error" 1 "CnsentGivenPTODriveMayBeEngaged" 0 "CnsntNtGvnPTODrvMayNotBeEngaged" ;
VAL_ 2566759678 EnggmntCnsntPTOEngnAssrDrv2 3 "NotAvailable" 2 "Error" 1 "CnsentGivenPTODriveMayBeEngaged" 0 "CnsntNtGvnPTODrvMayNotBeEngaged" ;
VAL_ 2566759678 EnggmntSttsTrnsfrstptshftPTO 3 "NotAvailable" 2 "Error" 1 "DriveIsEngaged" 0 "DriveNotEngaged" ;
VAL_ 2566759678 EnggmntSttsTrnsmssntptshftPTO 3 "NotAvailable" 2 "Error" 1 "DriveIsEngaged" 0 "DriveNotEngaged" ;
VAL_ 2566759678 EnggmntSttsTrnsmssnnptshftPTO2 3 "NotAvailable" 2 "Error" 1 "DriveIsEngaged" 0 "DriveNotEngaged" ;
VAL_ 2566759678 EnggmntSttsTrnsmssnnptshftPTO1 3 "NotAvailable" 2 "Error" 1 "DriveIsEngaged" 0 "DriveNotEngaged" ;
VAL_ 2566759678 EnggmntSttsPTOEngnFlwhl 3 "NotAvailable" 2 "Error" 1 "DriveEngaged" 0 "DriveNotEngaged" ;
VAL_ 2566759678 EnggmntSttsPTOEngnAssrDrv1 3 "NotAvailable" 2 "Error" 1 "DriveEngaged" 0 "DriveNotEngaged" ;
VAL_ 2566759678 EnggmntSttsPTOEngnAssrDrv2 3 "NotAvailable" 2 "Error" 1 "DriveEngaged" 0 "DriveNotEngaged" ;
VAL_ 2566760702 WrlssCmmntnNtwrkTp2 1 "CellularNetwork2" 0 "CellularNetwork1" ;
VAL_ 2566760958 WrlssCmmntnNtwrkTp1 1 "CellularNetwork2" 0 "CellularNetwork1" ;
VAL_ 2566762238 FfthWhlLkRdtCplIndtr 3 "NotAvailable" 2 "Error" 1 "LockOpenReadyToCouple" 0 "LockNotOpenNotReadyToCouple" ;
VAL_ 2566762238 FfthWhlLkCplSttsIndtr 3 "NotAvailable" 2 "Error" 1 "SuccessfulCoupleDetected" 0 "IncmpltBdCplTrckShuldNotBeMoved" ;
VAL_ 2566765054 TireLocation 51 "Axle3_Position3" 50 "Axle3_Position2" 49 "Axle3_Position1" 35 "Axle2_Position3" 34 "Axle2_Position2" 33 "Axle2_Position1" 19 "Axle1_Position3" 18 "Axle1_Position2" 17 "Axle1_Position1" 1 "Axle0_Position1" 48 "Axle3_Position0" 32 "Axle2_Position0" 16 "Axle1_Position0" 0 "Axle0_Position0" ;
VAL_ 2566766078 IntrstnPrmptnRqstRspns 3 "NotAvailable" 2 "ErrorCondition" 1 "MessageIsARespFromEmitter" 0 "MessageIsARqDirectedToEmitter" ;
VAL_ 2566766078 PriorityofResponseSentbyEmitter 15 "NotAvailable" 14 "ErrorCondition" 12 "to1101Reserved" 11 "PrrtyStByHardwareToHighPriority" 10 "PrrtyStByHrdwareToProbePriority" 9 "PrrtySetByHardwareToLowPriority" 4 "to1000Reserved" 3 "HighPriority" 2 "ProbePriority" 1 "LowPriority" 0 "Reserved" ;
VAL_ 2566766078 StrobeActivationControlStatus 3 "NotAvailable" 2 "ErrorCondition" 1 "ActivateStrobe" 0 "DeactivateStrobe" ;
VAL_ 2566767870 BrakeTemperatureWarning 3 "notAvailable" 2 "Reserved" 1 "Active" 0 "NotActive" ;
VAL_ 2566767870 XBRActiveControlMode 15 "NotAvailable" 4 "1110ReservedForSAEAssignment" 3 "MxMdOfXBRAcclrtnCtrlBngExecuted" 2 "AddtnMdOfXBRAcclrtnCtrlBngExctd" 1 "DrvrsBrkDmndBngExctdNExtlBrkDmn" 0 "NoBrakeDemandBeingExecuted" ;
VAL_ 2566767870 PrkngBrkAttrFllAtvtd 3 "NotAvailable" 2 "Error" 1 "PrkngBrkeActuatorFullyActivated" 0 "PrkngBrkActtorNotFullyActivated" ;
VAL_ 2566768382 EngineStartEnableDevice1 3 "NotAvailable" 2 "Reserved" 1 "StartEnableON" 0 "StartEnableOFF" ;
VAL_ 2566768382 EngineStartEnableDevice2 3 "NotAvailable" 2 "Reserved" 1 "StartEnableON" 0 "StartEnableOFF" ;
VAL_ 2566768382 EngnStrtEnlDv1Cnfgrtn 15 "NotAvailable" 5 "1110Reserved" 4 "ElctricIntakeAirHeaterInstalled" 3 "EtherInjectionInstalled" 2 "FuelledStartInstalled" 1 "GlowPlugsInstalled" 0 "NoStartEnableDevice1Installed" ;
VAL_ 2566768382 EngnStrtEnlDv2Cnfgrtn 15 "NotAvailable" 5 "1110Reserved" 4 "ElctricIntakeAirHeaterInstalled" 3 "EtherInjectionInstalled" 2 "FuelledStartInstalled" 1 "GlowPlugsInstalled" 0 "NoStartEnableDevice2Installed" ;
VAL_ 2566768638 EngineAuxiliaryGovernorState 3 "NotAvailable" 2 "SAEReserved" 1 "CtrlStateIsAuxGovernorEnabled" 0 "CtrlStateIsAuxGovernorDisabled" ;
VAL_ 2566768638 EngineMultiUnitSyncState 3 "NotAvailable" 2 "SAEReserved" 1 "CtrlStateIsFunctionalityEnabled" 0 "CtrlStteIsFunctionalityDisabled" ;
VAL_ 2566768638 EngnAltrntLwIdlSltStt 3 "NotAvailable" 2 "SAEReserved" 1 "AltIdleState" 0 "NormalIdleState" ;
VAL_ 2566768638 EngnAltrntRtngSltStt 1 "CtrlStateIsAltPowerFueling1" 0 "CtrlStateIsMaxPowerFueling" ;
VAL_ 2566768638 EngnDrpAlrtr1SltStt 15 "NotAvailable" 14 "SAEReserved" 1 "thr1101CtrlSttIsOnOfAltDrpSttng" 0 "CtrlStateIsNormalDroopSetting" ;
VAL_ 2566768638 EngnAltrntDrpAlrtr2SltStt 15 "NotAvailable" 14 "SAEReserved" 1 "thr1101CtrlsSttIsOnOfAltDrpSttn" 0 "CtrlsStateIsNormalDroopSetting" ;
VAL_ 2566768638 EngnDrpRmtAlrtrSltStt 15 "NotAvailable" 14 "SAEReserved" 1 "thr1101CtrlSttIsOnOfAltDrpSttng" 0 "CtrlStateIsNormalDroopSetting" ;
VAL_ 2566768638 EngnDrpAxlrInptSltStt 15 "NotAvailable" 14 "SAEReserved" 1 "thr1101CtrlSttIsOnOfAltDrpSttng" 0 "CtrlStateIsNormalDroopSetting" ;
VAL_ 2566768894 EngnOprtrPrmrIntrmdtSpdSltStt 15 "NotAvailable" 14 "SAEReserved" 1 "thr1101CtrlSttIsISCSttng1Thru13" 0 "CtrlSttIsISCFnctnltyIsNtRqdEngO" ;
VAL_ 2566769406 EngnOprtrPrmrIntrmdtSpdSlt 15 "NotAvailable" 14 "ErrorCondition" 1 "thr1101IndctsThtISCSttng1Thr13I" 0 "IndctsThtISCFnctnltyIsNtRqdEngO" ;
VAL_ 2566769662 EngineAuxiliaryGovernorSwitch 2 "ErrorCondition" 1 "AuxGovernorIsEnabled" 0 "AuxGovernorIsDisabled" 3 "NotAvailable" ;
VAL_ 2566769662 EngineSynchronizationSwitch 3 "NotAvailableUnused" 2 "Error" 1 "FunctionalityIsEnabled" 0 "FunctionalityIsDisabled" ;
VAL_ 2566769662 EngineAlternateLowIdleSwitch 3 "NotAvailableUnused" 2 "Error" 1 "AltLowIdlePointIsSelected" 0 "DefaultLowIdlePointIsSelected" ;
VAL_ 2566769662 EngineDroopAccelerator1Select 15 "NotAvailable" 14 "ErrorCondition" 1 "thr1101OnOfAltDrpSttng1Thrgh13I" 0 "NormalDroopSettingIsSelected" ;
VAL_ 2566769662 EngineDroopAccelerator2Select 15 "NotAvailable" 14 "ErrorCondition" 1 "thr1101OnOfAltDrpSttng1Thrgh13I" 0 "NormalDroopSettingIsSelected" ;
VAL_ 2566769662 EngnDrpRmtAlrtrSlt 15 "NotAvailable" 14 "ErrorCondition" 1 "thr1101OnOfAltDrpSttng1Thrgh13I" 0 "NormalDroopSettingIsSelected" ;
VAL_ 2566769662 EngineDroopAuxiliaryInputSelect 15 "NotAvailable" 14 "ErrorCondition" 1 "thr1101OnOfAltDrpSttng1Thrgh13I" 0 "NormalDroopSettingIsSelected" ;
VAL_ 2566771966 FifthWheelReleaseControl 3 "NotAvailable" 2 "Error" 1 "CplrUnlckdTrlrCnBUnhtchdHitched" 0 "CouplerLocked" ;
VAL_ 2566771966 FfthWhlRlsCntrlSrtLkt 3 "NotAvailable" 2 "Error" 1 "FifthWheelReleaseEnabled" 0 "FifthWheelReleaseDisabled" ;
VAL_ 2566771966 TransmissionOilLevelRequest 3 "DontCare_TakeNoAction" 2 "Reserved" 1 "TransOilLevelReadingDesired" 0 "NoTransOilLevelReadingDesired" ;
VAL_ 2566772222 EVGtTVGTACtStVv 3 "NotAvailable" 2 "Reserved" 1 "VGTAirCtrlShutoffValveIsOn" 0 "VGTAirCtrlShutoffValveIsOff" ;
VAL_ 2566772222 EngnVrlGmtrTrhrgr1CntrlMd 3 "notAvailable" 2 "SAEReserved" 1 "closedLoop" 0 "openLoop" ;
VAL_ 2566774014 EngnThrttlSnhrnztnMdStts 15 "TakeNoAction" 5 "1110Reserved" 4 "SynchronizedMaster" 3 "SynchronizedStarboard" 2 "SynchronizedPort" 1 "SynchronizedCenter" 0 "NotSynchronized" ;
VAL_ 2566799614 AlternateBeamHeadLightData 3 "NotAvailable" 2 "FaultDetected" 1 "Activated" 0 "Deactivated" ;
VAL_ 2566799614 TrtrUndrsdMntdWrkLghts 3 "NotAvailable" 2 "FaultDetected" 1 "Activated" 0 "Deactivated" ;
VAL_ 2566799614 TrtrRrHghMntdWrkLghts 3 "NotAvailable" 2 "FaultDetected" 1 "Activated" 0 "Deactivated" ;
VAL_ 2566799614 TrtrSdHghMntdWrkLghts 3 "NotAvailable" 2 "FaultDetected" 1 "Activated" 0 "Deactivated" ;
VAL_ 2566799614 TrtrFrntLwMntdWrkLghts 3 "NotAvailable" 2 "FaultDetected" 1 "Activated" 0 "Deactivated" ;
VAL_ 2566799614 TrtrFrntHghMntdWrkLghts 3 "NotAvailable" 2 "FaultDetected" 1 "Activated" 0 "Deactivated" ;
VAL_ 2566799614 ImplementLeftForwardWorkLight 3 "NotAvailable" 2 "FaultDetected" 1 "Activate" 0 "Deactivate" ;
VAL_ 2566799614 ImplementLeftFacingWorkLight 3 "NotAvailable" 2 "FaultDetected" 1 "Activated" 0 "Deactivated" ;
VAL_ 2566802174 TrnsmssnCrrntRngDsplBlnkStt 3 "NotSupported" 2 "Error" 1 "Blanked" 0 "NotBlanked" ;
VAL_ 2566802174 TransmissionServiceIndicator 3 "NotAvailable" 2 "ServiceIndicatorFlashing" 1 "ServiceIndicatorOn" 0 "SeviceIndicatorOff" ;
VAL_ 2566802174 TrnsmssnRqstdRngDsplBlnkStt 3 "TakeNoAction" 2 "Reserved" 1 "ActvTrnsRqdRngDsplyShldBBlanked" 0 "InctvTrnsRqdRngDsplyShldNtBBlnk" ;
VAL_ 2566802174 TrnsmssnRqstdRngDsplFlshStt 3 "TakeNoAction" 2 "Reserved" 1 "ActvTrnsRqdRngDsplyShldBFlshing" 0 "InctvTrnsRqdRngDsplyShldNtBFlsh" ;
VAL_ 2566802174 TrnsmssnRdfrBrkRls 3 "NotAvailable" 2 "Error" 1 "TransReadyForBrakeRelease" 0 "TransNotReadyForBrakeRelease" ;
VAL_ 2566802174 TransmissionEngineCrankEnable 3 "NotAvailable" 2 "Error" 1 "CrnkngEnbldEngCrnkngIsAllwdByTr" 0 "CrnkngDsbldEngCrnkngIsPrhbtdByT" ;
VAL_ 2566802174 TrnsmssnShftInhtIndtr 3 "TakeNoAction" 2 "Reserved" 1 "ActiveShiftIsInhibited" 0 "InactiveShiftIsNotInhibited" ;
VAL_ 2566802174 TransmissionMode4Indicator 3 "NotAvailable" 2 "Error" 1 "TransMode4Active" 0 "TransMode4NotActive" ;
VAL_ 2566802174 TransmissionMode3Indicator 3 "NotAvailable" 2 "Error" 1 "TransMode3Active" 0 "TransMode3NotActive" ;
VAL_ 2566802174 TransmissionMode2Indicator 3 "NotAvailable" 2 "Error" 1 "TransMode2Active" 0 "TransMode2NotActive" ;
VAL_ 2566802174 TransmissionMode1Indicator 3 "NotAvailable" 2 "Error" 1 "TransMode1Active" 0 "TransMode1NotActive" ;
VAL_ 2566802174 TransmissionMode5Indicator 3 "TakeNoAction" 2 "Reserved" 1 "Enable" 0 "Disable" ;
VAL_ 2566802174 TransmissionMode6Indicator 3 "TakeNoAction" 2 "Reserved" 1 "Enable" 0 "Disable" ;
VAL_ 2566802174 TransmissionMode7Indicator 3 "TakeNoAction" 2 "Reserved" 1 "Enable" 0 "Disable" ;
VAL_ 2566802174 TransmissionMode8Indicator 3 "TakeNoAction" 2 "Reserved" 1 "Enable" 0 "Disable" ;
VAL_ 2566802174 TrnsmssnRvrsGrShftInhtStts 3 "NotAvailable" 2 "Error" 1 "RvrsGrShftsArCurrentlyInhibited" 0 "RvrsGrShiftsAreCurrentlyAllowed" ;
VAL_ 2566802174 TransmissionWarningIndicator 3 "NotAvailable" 2 "TransWarningIndicatorIsFlashing" 1 "TrnsWrnngIndctrIsOnContinuously" 0 "TransWarningIndicatorIsOff" ;
VAL_ 2566802686 BlackOutBrakeStopLampSelect 3 "NotSupported" 2 "Reserved" 1 "On" 0 "Off" ;
VAL_ 2566803198 Positionofdoors 15 "NotAvailable" 14 "Error" 3 "1101NotDefined" 2 "AllDoorsClosed" 1 "ClosingLastDoor" 0 "AtLeast1DoorIsOpen" ;
VAL_ 2566803198 RampWheelChairLiftPosition 3 "NotAvailable" 2 "Error" 1 "OutsideBus" 0 "InsideBus" ;
VAL_ 2566803454 VDCbrakelightrequest 3 "DontCare_TakeNoAction" 2 "Reserved" 1 "TurnBrakeLightOn" 0 "TurnBrakeLightNotOn" ;
VAL_ 2566803454 ROPEngineControlactive 3 "DontCare_TakeNoAction" 2 "Reserved" 1 "ROPEngCtrlActive" 0 "ROPEngCtrlPassiveButInstalled" ;
VAL_ 2566803454 ROPBrakeControlactive 3 "DontCare_TakeNoAction" 2 "Reserved" 1 "ROPBrakeCtrlActive" 0 "ROPBrakeCtrlPassiveButInstalled" ;
VAL_ 2566803454 YCEngineControlactive 3 "DontCare_TakeNoAction" 2 "Reserved" 1 "YCEngCtrlActive" 0 "YCEngCtrlPassiveButInstalled" ;
VAL_ 2566803454 YCBrakeControlactive 3 "DontCare_TakeNoAction" 2 "Reserved" 1 "YCBrakeCtrlActive" 0 "YCBrakeCtrlPassiveButInstalled" ;
VAL_ 2566803966 RequestedACCDistanceMode 7 "notAvailable" 6 "errorCondition" 5 "notDefined" 4 "RqedACCDistanceMode5" 3 "RqedACCDistanceMode4" 2 "RqedACCDistanceMode3" 1 "RqedACCDistanceMode2" 0 "RqedACCDistanceMode1" ;
